VERSION "Version"

NS_ :

BS_:

BU_: Tester CCU ADC CCU_CCURT1 CCU_CCURT2 RLR RRR ZCUF ZCUL ZCUR ZCUT EMS IDM DCDC IPS NIDU NIDUF DCUR OBC OPC LPC CPC EMCM GCU DCUF IPU BMS EOPF EOPR EVCC DCDC2 EDL SRS ECS EPS EPB RBM IBCS ICM IID IDC PHUDD AMP WHUD IMR INU IFC FAPA PAS PCS SCMR SCMRL SCMRR HVSMR SCMRM MFS WSM DRM IDU FCP LBMSAD AVAS ATSS DLPFL FBLCM FLISD FLLCM FRLCM RLLCMA RLLCMB RRLCMA RRLCMB RLISD DLPML DLPMR TRM PSDL PSDR HVSPRL HVSPRR RFR SBM WCM ETC TBOX2 TBOX IDUR CBM PLGM TMC LPC2 SCMT RCP RRISD LBMS RLBMS CCURT1 CCURT2 RT1_C1 RT2_C3 RT1_C0 OTAWL RAS EBB RCICP WCMFR WCMRL SAS CD

BO_ 549 ADC_12: 64 ADC
 SG_ ADC_12_CRC : 7|16@0+ (1,0) [0|65535] ""  CCU,CCURT1,RT1_C0
 SG_ ADC_12_Counter : 23|8@0+ (1,0) [0|255] ""  CCU,CCURT1,RT1_C0
 SG_ ADC_APAst : 31|4@0+ (1,0) [0|15] ""  CCU
 SG_ ADC_AVPst : 27|4@0+ (1,0) [0|15] ""  CCU
 SG_ ADC_PAAFuncSt : 39|4@0+ (1,0) [0|15] ""  CCU,CCURT1,RT1_C0
 SG_ ADC_PAAVoiceReminder : 35|12@0+ (1,0) [0|4095] ""  CCU
 SG_ ADC_PAAVRSwitchFailSt : 55|1@0+ (1,0) [0|1] ""  CCU
 SG_ ADC_APKDisplayReq : 54|1@0+ (1,0) [0|1] ""  CCU
 SG_ ADC_APAActFuncInd : 53|4@0+ (1,0) [0|15] ""  CCU
 SG_ ADC_APABackParkDisplayReq : 49|2@0+ (1,0) [0|3] ""  CCU
 SG_ ADC_VCU_Gearshiftprompt : 56|1@0+ (1,0) [0|1] ""  CCU,CCURT1,RT1_C1
 SG_ ADC_AVPActFuncind : 63|5@0+ (1,0) [0|31] ""  CCU
 SG_ ADC_APAMessagePushSt : 58|2@0+ (1,0) [0|3] ""  CCU
 SG_ ADC_PedWarnToneCtrl : 67|2@0+ (1,0) [0|3] ""  CCU
 SG_ ADC_HPAMessagePushSt : 71|2@0+ (1,0) [0|3] ""  CCU
 SG_ ADC_AVPMessagePushSt : 69|2@0+ (1,0) [0|3] ""  CCU
 SG_ ADC_PAADrvInteraction : 64|9@0+ (1,0) [0|511] ""  CCU
 SG_ ADC_PAAToNDAReq : 89|2@0+ (1,0) [0|3] ""  CCU,ZCUF,ZCUT,IBCS,SBM
 SG_ ADC_PAARemoteParkingMode : 87|2@0+ (1,0) [0|3] ""  CCU
 SG_ ADC_PAARemoteParkingEnable : 85|1@0+ (1,0) [0|1] ""  CCU
 SG_ ADC_LocalToBeDRVReq : 83|1@0+ (1,0) [0|1] ""  CCU,CCURT1,RT1_C0
 SG_ ADC_UsageModeStAscendReq : 82|1@0+ (1,0) [0|1] ""  CCU,CCURT1,RT1_C0
 SG_ ADC_UsageModeStDescendReq : 81|1@0+ (1,0) [0|1] ""  CCU,CCURT1,RT1_C0
 SG_ ADC_PAAIGCInhibitSt : 80|1@0+ (1,0) [0|1] ""  CCU,CCURT1,RT1_C0
 SG_ ADC_UsageModeStHold : 90|1@0+ (1,0) [0|1] ""  CCU,CCURT1,RT1_C0
 SG_ ADC_PAARespondMode : 94|4@0+ (1,0) [0|15] ""  CCU
 SG_ ADC_PAAEDKFunInhibitReq : 95|1@0+ (1,0) [0|1] ""  CCU
 SG_ ADC_RAEBWorkSts : 101|2@0+ (1,0) [0|3] ""  CCU,CCURT1,RT1_C0,RT1_C1
 SG_ ADC_DriverPresentSt : 103|2@0+ (1,0) [0|3] ""  CCU,ZCUF,ZCUR,ZCUT,IBCS
 SG_ ADC_UsageModeStHoldVD : 99|1@0+ (1,0) [0|1] ""  CCU,CCURT1,RT1_C0
 SG_ ADC_RAEBEmgyBrkReq : 111|1@0+ (1,0) [0|1] ""  CCU
 SG_ ADC_RAEBTarAccel : 110|7@0+ (0.1,-10) [-10|0] "m/s"  CCU
 SG_ ADC_PAADrvReq : 119|8@0+ (1,0) [0|255] ""  CCU,ZCUR,IDC,SBM
 SG_ ADC_PAAQuitInd : 127|8@0+ (1,0) [0|255] ""  CCU,ZCUR,IDC,SBM
 SG_ ADC_PAARecInd : 135|6@0+ (1,0) [0|63] ""  CCU,ZCUR,IDC,SBM
 SG_ ADC_RA_RemainDist : 139|12@0+ (1,0) [0|4000] "m"  CCU
 SG_ ADC_RAButtonPress : 156|1@0+ (1,0) [0|1] ""  CCU
 SG_ ADC_Rast : 159|3@0+ (1,0) [0|7] ""  CCU
 SG_ ADC_SBMAuthst : 163|2@0+ (1,0) [0|3] ""  CCU
 SG_ ADC_AuthPassSt : 165|2@0+ (1,0) [0|3] ""  CCU
 SG_ ADC_RPADirectionSel : 155|4@0+ (1,0) [0|15] ""  CCU
 SG_ ADC_VehPoscoord : 167|1@0+ (1,0) [0|1] ""  CCU
 SG_ ADC_VehDynamicPosX : 161|13@0+ (1,-4000) [-4000|4000] "cm"  CCU
 SG_ ADC_VehDynamicPosY : 180|13@0+ (1,-4000) [-4000|4000] "cm"  CCU
 SG_ ADC_VehCurv : 206|10@0+ (1,-500) [-500|500] "m^-1"  CCU
 SG_ ADC_SlotPosX : 212|13@0+ (1,-4000) [-4000|4000] "cm"  CCU
 SG_ ADC_SlotPosY : 231|13@0+ (1,-4000) [-4000|4000] "cm"  CCU
 SG_ ADC_HPAst : 245|4@0+ (1,0) [0|15] ""  CCU,SBM
 SG_ ADC_SlotCurv : 241|10@0+ (1,-500) [-500|500] "m^-1"  CCU
 SG_ ADC_parkInOutDirection : 299|4@0+ (1,0) [0|15] ""  CCU
 SG_ ADC_RPAStMessagePush : 98|3@0+ (1,0) [0|7] ""  CCU
 SG_ ADC_RPAtype : 383|2@0+ (1,0) [0|3] ""  CCU
 SG_ ADC_VehPosYawrate : 343|16@0+ (0.01,-180) [-180|180] "degree"  CCU
 SG_ ADC_SlotAngle : 359|16@0+ (0.01,-180) [-180|180] "degree"  CCU
 SG_ ADC_DskScreenOperationReq : 368|1@0+ (1,0) [0|1] ""  CCU
 SG_ ADC_SenslesEtyParkingSt : 369|1@0+ (1,0) [0|1] ""  CCU
 SG_ ADC_PAALimitToast : 372|3@0+ (1,0) [0|7] ""  CCU
 SG_ ADC_PAALimitReminder : 375|3@0+ (1,0) [0|7] ""  CCU
 SG_ ADC_ParkOutMode : 381|3@0+ (1,0) [0|7] ""  CCU,SBM
 SG_ ADAS_ParkStats : 391|8@0+ (1,0) [0|255] ""  CCU,SBM
 SG_ ADC_ParkinDir : 393|2@0+ (1,0) [0|3] ""  CCU,SBM
 SG_ ADC_FrontEndParkInRes : 409|2@0+ (1,0) [0|3] ""  CCU,SBM
 SG_ ADC_ParkSlotType : 407|3@0+ (1,0) [0|7] ""  CCU,SBM
 SG_ ADC_BleRPAPageSt : 404|5@0+ (1,0) [0|31] ""  CCU,SBM
 SG_ ADC_RPAPreferRes : 415|3@0+ (1,0) [0|7] ""  CCU,SBM
 SG_ ADC_RPAPrkSlotoffset : 423|3@0+ (1,0) [0|7] ""  CCU,SBM
 SG_ ADC_RPAPreferavl : 412|3@0+ (1,0) [0|7] ""  CCU,SBM
 SG_ ADC_RPABlechnReq : 399|1@0+ (1,0) [0|1] ""  CCU,SBM
 SG_ ADC_RPABlePushSt : 398|5@0+ (1,0) [0|31] ""  CCU,SBM

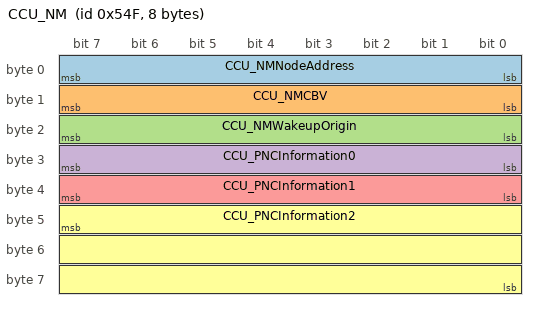
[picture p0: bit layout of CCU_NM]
BO_ 1359 CCU_NM: 8 CCU
 SG_ CCU_NMNodeAddress : 7|8@0+ (1,0) [0|255] ""  CCURT1,TMC,ZCUF,ZCUL,ZCUR,ZCUT,EMS,IPS,NIDU,NIDUF,BMS,EVCC,ECS,CBM,EPB,RBM,IBCS,ICM,IID,IDC,PHUDD,AMP,ADC,FAPA,SCMR,SCMRL,SCMRR,SCMRM,SCMT,IDU,LBMSAD,PLGM,TRM,PSDL,PSDR,LBMS,RLBMS,TBOX
 SG_ CCU_NMCBV : 15|8@0+ (1,0) [0|0] ""  CCURT1,TMC,ZCUF,ZCUL,ZCUR,ZCUT,EMS,IPS,NIDU,NIDUF,BMS,EVCC,ECS,CBM,EPB,RBM,IBCS,ICM,IID,IDC,PHUDD,AMP,ADC,FAPA,SCMR,SCMRL,SCMRR,SCMRM,SCMT,IDU,LBMSAD,PLGM,TRM,PSDL,PSDR,LBMS,RLBMS,TBOX
 SG_ CCU_NMWakeupOrigin : 23|8@0+ (1,0) [0|255] ""  CCURT1,TMC,ZCUF,ZCUL,ZCUR,ZCUT,EMS,IPS,NIDU,NIDUF,BMS,EVCC,ECS,CBM,RBM,IBCS,ICM,IID,IDC,PHUDD,AMP,ADC,FAPA,SCMR,SCMRL,SCMRR,SCMRM,SCMT,IDU,LBMSAD,PLGM,TRM,PSDL,PSDR,LBMS,RLBMS,TBOX
 SG_ CCU_PNCInformation0 : 31|8@0+ (1,0) [0|255] ""  CCURT1,TMC,ZCUF,ZCUL,ZCUR,ZCUT,EMS,IPS,NIDU,NIDUF,BMS,EVCC,ECS,CBM,EPB,RBM,IBCS,ICM,IID,IDC,PHUDD,AMP,ADC,FAPA,SCMR,SCMRL,SCMRR,SCMRM,SCMT,IDU,LBMSAD,PLGM,TRM,PSDL,PSDR,LBMS,RLBMS,TBOX
 SG_ CCU_PNCInformation1 : 39|8@0+ (1,0) [0|255] ""  CCURT1,TMC,ZCUF,ZCUL,ZCUR,ZCUT,EMS,IPS,NIDU,NIDUF,BMS,EVCC,ECS,CBM,EPB,RBM,IBCS,ICM,IID,IDC,PHUDD,AMP,ADC,FAPA,SCMR,SCMRL,SCMRR,SCMRM,SCMT,IDU,LBMSAD,PLGM,TRM,PSDL,PSDR,LBMS,RLBMS,TBOX
 SG_ CCU_PNCInformation2 : 47|24@0+ (1,0) [0|0] ""  CCURT1,TMC,ZCUF,ZCUL,ZCUR,ZCUT,EMS,IPS,NIDU,NIDUF,BMS,EVCC,ECS,CBM,EPB,RBM,IBCS,ICM,IID,IDC,PHUDD,AMP,ADC,FAPA,SCMR,SCMRL,SCMRR,SCMRM,SCMT,IDU,LBMSAD,PLGM,TRM,PSDL,PSDR,LBMS,RLBMS,TBOX

BO_ 905 CCU_IDC_ICM_1: 64 CCU
 SG_ ICM_SetIACCSt : 27|1@0+ (1,0) [0|1] ""  ADC,IFC,FAPA
 SG_ ICM_TotalOdometer : 35|20@0+ (1,0) [0|999999] "km"  ZCUF,ZCUL,ZCUR,ZCUT,EMS,NIDU,NIDUF,DCUR,IDUR,GCU,DCUF,IPU,ECS,EPS,EPB,IBCS,ADC,IFC,FAPA,RRR,RLR,PCS
 SG_ ICM_VehInsSpd : 103|8@0+ (1,0) [0|254] "km/h"  ADC,IFC,FAPA,RRR,RLR
 SG_ ICM_VehInsSpd_accurate : 272|11@0+ (0.1,0) [0|204.6] "km/h"  ECS,WHUD,ADC,IFC,FAPA,RRR,RLR
 SG_ ICM_FuelAvaibleDriveDistance : 311|11@0+ (1,0) [0|2046] "km"  ADC,FAPA
 SG_ ICM_TotalAvaibleDriveDistance : 316|11@0+ (1,0) [0|2046] "km"  ADC,FAPA

BO_ 516 CCU_VCU_9: 64 CCU_CCURT1
 SG_ VCU_9_CRC : 7|16@0+ (1,0) [0|65535] ""  CCURT2,RT2_C3,ZCUF,ZCUL,ZCUR,ZCUT,EMS,NIDU,DCUR,IDUR,EDL,ECS,EPB,IBCS,ICM,IDC,INU,ADC,IFC,FAPA,RRR,RLR,PAS
 SG_ VCU_9_Counter : 23|8@0+ (1,0) [0|255] ""  CCURT2,RT2_C3,ZCUF,ZCUL,ZCUR,ZCUT,EMS,NIDU,DCUR,IDUR,EDL,ECS,EPB,IBCS,ICM,IDC,INU,ADC,IFC,FAPA,RRR,RLR,PAS
 SG_ VCU_MaxDriveTorqVD : 25|1@0+ (1,0) [0|1] ""  ADC,IFC,FAPA
 SG_ VCU_RecpTorqVD : 74|1@0+ (1,0) [0|1] ""  IBCS,ADC,IFC,FAPA
 SG_ VCU_MaxRecpTorqVD : 72|1@0+ (1,0) [0|1] ""  IBCS,ADC,IFC,FAPA
 SG_ VCU_CrntGearLvl : 92|3@0+ (1,0) [0|7] ""  CCURT2,RT2_C3,OTAWL,ZCUF,ZCUL,ZCUR,ZCUT,NIDU,NIDUF,DCUR,IDUR,DCUF,IPU,SRS,ECS,RAS,EPS,EPB,IBCS,IDC,AMP,INU,ADC,IFC,FAPA,RRR,RLR,PAS,WSM,DLPML,DLPMR,TBOX
 SG_ VCU_CrntGearLvlVD : 88|1@0+ (1,0) [0|1] ""  ZCUF,ZCUL,ZCUR,ZCUT,SRS,ECS,EPS,EPB,IBCS,AMP,INU,ADC,IFC,FAPA,RRR,RLR,PAS
 SG_ VCU_BrkPedPstVD : 89|1@0+ (1,0) [0|1] ""  CCURT2,RT2_C3,NIDU,DCUR,IDUR,SRS,ECS,IBCS,IDC,ADC,IFC,FAPA,TBOX
 SG_ VCU_BrkPedPst : 103|8@0+ (0.392,0) [0|99.96] "%"  CCURT2,RT2_C3,NIDU,DCUR,IDUR,SRS,ECS,IBCS,IDC,ADC,IFC,FAPA,TBOX
 SG_ VCU_GearIntervern : 137|1@0+ (1,0) [0|1] ""  IBCS,ADC,IFC,FAPA
 SG_ VCU_AccPedalVirtPstVD : 136|1@0+ (1,0) [0|1] ""  CCURT2,RT2_C3,EMS,NIDU,DCUR,IDUR,SRS,ECS,IBCS,IDC,AMP,ADC,IFC,FAPA,TBOX
 SG_ VCU_ActVehWheelTorq : 378|15@0+ (1,-16000) [-16000|16000] "Nm"  ECS,IBCS,AMP,ADC
 SG_ VCU_MaxRecpTorq : 135|14@0+ (1,0) [0|16000] "Nm"  IBCS,ADC,IFC,FAPA
 SG_ VCU_AccPedalVirtPst : 146|9@0+ (0.2,0) [0|100] "%"  CCURT2,RT2_C3,EMS,NIDU,DCUR,IDUR,SRS,ECS,IBCS,IDC,AMP,ADC,IFC,FAPA,RRR,RLR,TBOX
 SG_ VCU_BrkPedalSt : 189|1@0+ (1,0) [0|1] ""  CCURT2,RT2_C3,EMS,SRS,ECS,IDC,ADC,IFC,FAPA,RRR,RLR,TBOX
 SG_ VCU_BrkPedalStVD : 188|1@0+ (1,0) [0|1] ""  CCURT2,RT2_C3,EMS,SRS,ECS,IDC,ADC,IFC,FAPA,TBOX
 SG_ VCU_ACCLimitOperatingSt : 186|1@0+ (1,0) [0|1] ""  ADC,IFC,FAPA
 SG_ VCU_AccButtInfo : 199|8@0+ (1,0) [0|255] ""  IDC,ADC,IFC,FAPA
 SG_ VCU_ACCmaxSpdLimit : 215|4@0+ (1,0) [0|15] ""  ADC,IFC,FAPA
 SG_ VCU_RecpTorqFAVD : 208|1@0+ (1,0) [0|1] ""  IBCS,ADC,IFC,FAPA
 SG_ VCU_RecpTorqRAVD : 209|1@0+ (1,0) [0|1] ""  IBCS,ADC,IFC,FAPA
 SG_ VCU_MaxRecpTorqFAVD : 152|1@0+ (1,0) [0|1] ""  IBCS,ADC,IFC,FAPA
 SG_ VCU_MaxRecpTorqRAVD : 153|1@0+ (1,0) [0|1] ""  IBCS,ADC,IFC,FAPA
 SG_ VCU_RecpTorq : 359|14@0+ (1,0) [0|16000] "Nm"  IBCS,ADC,IFC,FAPA
 SG_ VCU_MaxDriveTorq : 167|14@0+ (1,0) [0|16000] "Nm"  ECS,IBCS,ADC,IFC,FAPA
 SG_ VCU_RecpTorqFA : 231|14@0+ (1,0) [0|16000] "Nm"  IBCS,ADC,IFC,FAPA
 SG_ VCU_RecpTorqRA : 233|14@0+ (1,0) [0|16000] "Nm"  IBCS,ADC,IFC,FAPA
 SG_ VCU_MaxRecpTorqFA : 251|14@0+ (1,0) [0|16000] "Nm"  IBCS,ADC,IFC,FAPA
 SG_ VCU_MaxRecpTorqRA : 269|14@0+ (1,0) [0|16000] "Nm"  IBCS,ADC,IFC,FAPA
 SG_ VCU_BcsDecelEnable : 305|1@0+ (1,0) [0|1] ""  IBCS,IDC,ADC,IFC,FAPA
 SG_ VCU_CrntGearNoTrans : 317|3@0+ (1,0) [0|7] ""  ADC,IFC,FAPA
 SG_ VCU_EzTSt : 314|2@0+ (1,0) [0|3] ""  IBCS,IDC,ADC,FAPA
 SG_ VCU_ITASSt : 444|3@0+ (1,0) [0|7] ""  IBCS,IDC,ADC,FAPA

BO_ 909 CCU_ZCU_1: 64 CCU_CCURT2
 SG_ LCK_HoodAjarSt : 37|1@0+ (1,0) [0|1] ""  OTAWL,ZCUR,EMS,ECS,ICM,IID,IDC,PHUDD,AMP,ADC,IFC,FAPA,RRR,RLR,PCS
 SG_ LCK_FrontLeftDoorAjarSt : 36|1@0+ (1,0) [0|1] ""  OTAWL,ZCUF,ZCUR,ZCUT,EPB,IBCS,ICM,IID,IDC,PHUDD,AMP,IMR,ADC,IFC,FAPA,RRR,RLR,WSM,DLPML,DLPMR,PLGM
 SG_ LCK_FrontRightDoorAjarSt : 35|1@0+ (1,0) [0|1] ""  ZCUT,IBCS,ICM,IID,IDC,PHUDD,AMP,IMR,ADC,IFC,FAPA,RRR,RLR,WSM,DLPML,DLPMR,PLGM
 SG_ LCK_RearLeftDoorAjarSt : 34|1@0+ (1,0) [0|1] ""  OTAWL,ZCUL,ZCUR,ECS,IBCS,ICM,IID,IDC,PHUDD,AMP,IMR,ADC,IFC,FAPA,RRR,RLR,PCS,SCMR,SCMRL,SCMRR,SCMRM,DLPML,DLPMR,PLGM
 SG_ LCK_RearRightDoorAjarSt : 33|1@0+ (1,0) [0|1] ""  OTAWL,ZCUL,ZCUR,ECS,IBCS,ICM,IID,IDC,PHUDD,AMP,IMR,ADC,IFC,FAPA,RRR,RLR,PCS,SCMR,SCMRL,SCMRR,SCMRM,DLPML,DLPMR,PLGM
 SG_ LCK_TrunkAjarSt : 32|1@0+ (1,0) [0|1] ""  OTAWL,ZCUF,ZCUL,ZCUR,ECS,ICM,IID,IDC,PHUDD,AMP,IMR,ADC,IFC,FAPA,RRR,RLR,PCS
 SG_ LCK_FrontLeftDoorLockSt : 47|1@0+ (1,0) [0|1] ""  OTAWL,ZCUR,CBM,ICM,IDC,ADC,IFC,FAPA,RRR,RLR
 SG_ LCK_FrontRightDoorLockSt : 46|1@0+ (1,0) [0|1] ""  CBM,ICM,IDC,ADC,IFC,FAPA,RRR,RLR
 SG_ LCK_RearLeftDoorLockSt : 45|1@0+ (1,0) [0|1] ""  OTAWL,ZCUL,ZCUR,ECS,CBM,ICM,IDC,ADC,IFC,FAPA,RRR,RLR
 SG_ LCK_RearRightDoorLockSt : 44|1@0+ (1,0) [0|1] ""  OTAWL,ZCUL,ZCUR,ECS,CBM,ICM,IDC,ADC,IFC,FAPA,RRR,RLR
 SG_ LCK_RearLeftChildSaftyLockSt : 43|1@0+ (1,0) [0|1] ""  ZCUL,ZCUR,CBM,ICM,IDC,ADC,IFC,FAPA,RRR,RLR
 SG_ LCK_RearRightChildSaftyLockSt : 42|1@0+ (1,0) [0|1] ""  OTAWL,ZCUL,ZCUR,CBM,ICM,IDC,ADC,IFC,FAPA,RRR,RLR
 SG_ EMS_EngStForPHEV : 79|3@0+ (1,0) [0|7] ""  NIDU,BMS,IDC,ADC,FAPA
 SG_ WCM_Reminder : 103|1@0+ (1,0) [0|1] ""  ADC,FAPA
 SG_ WCM_ChargingSt : 89|2@0+ (1,0) [0|3] ""  ADC,FAPA
 SG_ LCK_FrontLeftDoorHandlePosition : 135|8@0+ (1,0) [0|255] ""  CBM,ICM,IDC,ADC,FAPA
 SG_ LCK_FrontRightDoorHandlePosition : 143|8@0+ (1,0) [0|255] ""  CBM,ICM,IDC,ADC,FAPA
 SG_ LCK_RearLeftDoorHandlePosition : 151|8@0+ (1,0) [0|255] ""  ZCUL,ZCUR,CBM,ICM,IDC,ADC,FAPA
 SG_ LCK_RearRightDoorHandlePosition : 159|8@0+ (1,0) [0|255] ""  ZCUL,ZCUR,CBM,ICM,IDC,ADC,FAPA
 SG_ WW_RWPMotorSt : 226|3@0+ (1,0) [0|7] ""  ADC,IFC,FAPA
 SG_ LCK_FillerCapASt : 239|1@0+ (1,0) [0|1] ""  ZCUL,ZCUR,EMS,ICM,IDC,ADC,FAPA
 SG_ LCK_FillerCapBSt : 238|1@0+ (1,0) [0|1] ""  ZCUL,ZCUR,EMS,ICM,IDC,ADC,FAPA
 SG_ MR_LeftMirrorFoldUnfoldSt : 233|2@0+ (1,0) [0|3] ""  ADC,IFC,FAPA,RRR,RLR,PCS,WSM,DLPML,DLPMR
 SG_ SBM_SwapHvBattModeSt : 247|4@0+ (1,0) [0|15] ""  ADC,FAPA
 SG_ SBM_SwapStaDiagCode : 243|4@0+ (1,0) [0|15] ""  ADC,FAPA
 SG_ SBM_SwapVehDiagCode : 255|4@0+ (1,0) [0|15] ""  ADC,FAPA
 SG_ SBM_SwapHvBattModeFaultSt : 251|3@0+ (1,0) [0|7] ""  ADC,FAPA
 SG_ IPDS_HDMapPowerSt : 271|1@0+ (1,0) [0|1] ""  ADC,IFC,FAPA
 SG_ IPDS_KL15L1PowerSt : 270|1@0+ (1,0) [0|1] ""  EBB,IBCS,ADC,IFC,FAPA,RRR,RLR
 SG_ IPDS_SRSECUPowerSt : 269|1@0+ (1,0) [0|1] ""  EPS,IBCS,ADC,IFC,FAPA
 SG_ IPDS_HODPowerSt : 268|1@0+ (1,0) [0|1] ""  ADC,IFC,FAPA
 SG_ KAE_BLEOption : 265|1@0+ (1,0) [0|1] ""  ADC,FAPA
 SG_ KAE_UWBOption : 264|1@0+ (1,0) [0|1] ""  ADC,FAPA
 SG_ PWL_WinCurrentPos_FLWinPst : 470|8@0+ (0.5,0) [0|100] "%"  ZCUT,ADC,FAPA,PLGM
 SG_ UINM_FrontLeftPowerReleaseReq : 456|1@0+ (1,0) [0|1] ""  ADC,FAPA
 SG_ UINM_FrontLeftPowerReleaseFaultSt : 457|1@0+ (1,0) [0|1] ""  ADC,FAPA
 SG_ UINM_FrontRightPowerReleaseReq : 458|1@0+ (1,0) [0|1] ""  ADC,FAPA
 SG_ UINM_FrontRightPowerReleaseFaultSt : 459|1@0+ (1,0) [0|1] ""  ADC,FAPA
 SG_ UINM_RearLeftPowerReleaseFaultSt : 460|1@0+ (1,0) [0|1] ""  ADC,FAPA
 SG_ UINM_RearLeftPowerReleaseReq : 461|1@0+ (1,0) [0|1] ""  ADC,FAPA
 SG_ UINM_RearRightPowerReleaseFaultSt : 462|1@0+ (1,0) [0|1] ""  ADC,FAPA
 SG_ UINM_RearRightPowerReleaseReq : 471|1@0+ (1,0) [0|1] ""  ADC,FAPA
 SG_ BMS_BattSOCAccurate : 478|14@0+ (0.01,0) [0|100] "%"  ADC,FAPA
 SG_ PWL_WinCurrentPos_RRWinPst : 503|8@0+ (0.5,0) [0|100] "％"  IDC,RCICP,AMP,IMR,ADC,FAPA,PLGM,HVSPRL,HVSPRR
 SG_ PWL_WinCurrentPos_RLWinPst : 511|8@0+ (0.5,0) [0|100] "％"  ZCUR,IDC,RCICP,AMP,IMR,ADC,FAPA,PLGM,HVSPRL,HVSPRR
 SG_ ACEleclocksSt : 282|3@0+ (1,0) [0|7] ""  ADC,FAPA
 SG_ DSASBM_MotResp : 375|4@0+ (1,0) [0|15] ""  ADC,FAPA

BO_ 792 CCU_ZCU_4: 64 CCU_CCURT2
 SG_ UMM_SecondRHSeatSt : 37|2@0+ (1,0) [0|3] ""  ICM,IDC,ADC,IFC
 SG_ UMM_SecondLHSeatSt : 39|2@0+ (1,0) [0|3] ""  ICM,IDC,ADC,IFC
 SG_ LCK_PowerFillerCapAngle : 103|8@0+ (1,0) [0|255] "deg"  ICM,IDC,ADC,FAPA
 SG_ EL_ReverseLightSt : 111|1@0+ (1,0) [0|1] ""  IDC,ADC,IFC,FAPA,PCS
 SG_ EL_ReverseLightFaultSt : 110|1@0+ (1,0) [0|1] ""  ICM,IDC,ADC,IFC,FAPA
 SG_ EL_RLPositionLightSt : 105|1@0+ (1,0) [0|1] ""  ICM,IDC,ADC,IFC,FAPA
 SG_ EL_RLPositionLightFaultSt : 104|1@0+ (1,0) [0|1] ""  ICM,IDC,ADC,IFC,FAPA
 SG_ EL_RRPositionLightSt : 119|1@0+ (1,0) [0|1] ""  ICM,IDC,ADC,IFC,FAPA
 SG_ EL_RRPositionLightFaultSt : 118|1@0+ (1,0) [0|1] ""  ICM,IDC,ADC,IFC,FAPA
 SG_ EL_RearFogLightSt : 117|1@0+ (1,0) [0|1] ""  ICM,IDC,ADC,IFC,FAPA
 SG_ EL_RearFogLightFaultSt : 116|1@0+ (1,0) [0|1] ""  ICM,IDC,ADC,IFC,FAPA

BO_ 860 CCU_VCU_7: 64 CCU_CCURT1
 SG_ VCU_7_CRC : 7|16@0+ (1,0) [0|65535] ""  CCURT2,RT2_C3,ZCUF,ZCUL,ZCUR,ZCUT,EPB,IDC,ADC,IFC,FAPA,RRR,RLR,DRM
 SG_ VCU_7_Counter : 23|8@0+ (1,0) [0|255] ""  CCURT2,RT2_C3,ZCUF,ZCUL,ZCUR,ZCUT,EPB,IDC,ADC,IFC,FAPA,RRR,RLR,DRM
 SG_ VCU_RoadMod : 27|3@0+ (1,0) [0|7] ""  ECS,IBCS,IDC,ADC,FAPA
 SG_ VCU_GearLvl : 31|4@0+ (1,0) [0|15] ""  CCURT2,RT2_C3,ZCUF,ZCUL,ZCUR,ZCUT,EMS,EPB,IBCS,ADC,IFC,FAPA,RRR,RLR,DRM
 SG_ VCU_VehDrvMod : 38|3@0+ (1,0) [0|7] ""  ZCUL,ZCUR,EMS,ECS,IBCS,ICM,IDC,AMP,ADC,IFC,FAPA,ATSS,WCM,WCMFR,WCMRL
 SG_ VCU_VehRdySt : 39|1@0+ (1,0) [0|1] ""  CCURT2,RT2_C3,OTAWL,ZCUF,ZCUL,ZCUR,ZCUT,EMS,IDM,IPS,NIDU,NIDUF,DCUR,IDUR,OBC,GCU,DCUF,IPU,BMS,ECS,EPB,IBCS,ICM,IID,IDC,PHUDD,ADC,IFC,FAPA,RRR,RLR,TBOX
 SG_ VCU_PlgConnSt : 91|1@0+ (1,0) [0|1] ""  CCURT2,RT2_C3,ZCUR,ZCUT,NIDU,NIDUF,DCUR,IDUR,GCU,DCUF,IPU,ECS,ICM,IID,IDC,PHUDD,ADC,IFC,FAPA
 SG_ VCU_GearLvlDisp : 155|4@0+ (1,0) [0|15] ""  ICM,IID,IDC,PHUDD,WHUD,IMR,ADC,IFC,FAPA,PCS
 SG_ VCU_SuspModeReq : 257|2@0+ (1,0) [0|3] ""  ECS,ADC,IFC,FAPA
 SG_ VCU_SuspModeReqEnable : 316|1@0+ (1,0) [0|1] ""  ECS,ADC,IFC,FAPA
 SG_ VCU_GearPosition : 315|3@0+ (1,0) [0|7] ""  CCURT2,RT2_C3,BMS,ADC,IFC,FAPA
 SG_ VCU_EcoPlusMod : 341|2@0+ (1,0) [0|3] ""  CCURT2,RT2_C3,IDC,WHUD,ADC
 SG_ ICC_RoadMod : 339|4@0+ (1,0) [0|8] ""  CCURT2,RT2_C3,NIDU,BMS,ECS,IBCS,IDC,AMP,ADC,WSM,ATSS
 SG_ VCU_TrailerModeSt : 396|3@0+ (1,0) [0|7] ""  ECS,IBCS,IDC,ADC
 SG_ VCU_BMS_BattSocDisp : 405|14@0+ (0.01,0) [0|100] "%"  CCURT2,RT2_C3,ZCUL,ZCUR,EMS,BMS,ICM,IID,IDC,PHUDD,ADC
 SG_ VCU_VehElcConspAccumAvg : 429|10@0+ (0.1,-51) [-51|51.2] "kWh/100km"  CCURT2,RT2_C3,BMS,IDC,ADC
 SG_ ICC_360Switch : 435|2@0+ (1,0) [0|3] ""  IDC,ADC

CM_ SG_ 549 ADC_12_CRC "E2E Profile 5 CRC";
CM_ SG_ 549 ADC_12_Counter "E2E Profile 5 Counter";
CM_ SG_ 549 ADC_APAst "APA and FAPA status";
CM_ SG_ 549 ADC_AVPst "HPA and AVP status";
CM_ SG_ 549 ADC_PAAFuncSt "PAA working functions inaication signal";
CM_ SG_ 549 ADC_PAAVoiceReminder "PAA Voice Reminder";
CM_ SG_ 549 ADC_PAAVRSwitchFailSt "PAA VR Switch Fail State";
CM_ SG_ 549 ADC_APKDisplayReq "APK display request";
CM_ SG_ 549 ADC_APAActFuncInd "Auto_parking Active Function Indication";
CM_ SG_ 549 ADC_APABackParkDisplayReq "APA Background Parking For AVNT Display";
CM_ SG_ 549 ADC_VCU_Gearshiftprompt "The signal prohibiting gear shifting prompt sent from the ADC to the VCU";
CM_ SG_ 549 ADC_AVPActFuncind "AVP Active Function Indication";
CM_ SG_ 549 ADC_APAMessagePushSt "APA Message Push Staus";
CM_ SG_ 549 ADC_PedWarnToneCtrl "Parking cost pedestrian warning sound";
CM_ SG_ 549 ADC_HPAMessagePushSt "HPA Message  Push Staus";
CM_ SG_ 549 ADC_AVPMessagePushSt "AVP Message  Push Staus";
CM_ SG_ 549 ADC_PAADrvInteraction "PAA Driver Interaction signal";
CM_ SG_ 549 ADC_PAAToNDAReq "PAA  to NDA status requested, or NDA to PAA  status requested";
CM_ SG_ 549 ADC_PAARemoteParkingMode "PAA Remote parking Mode";
CM_ SG_ 549 ADC_PAARemoteParkingEnable "PAA Remote Parking Enable";
CM_ SG_ 549 ADC_LocalToBeDRVReq "Request IPDS  PW KL15";
CM_ SG_ 549 ADC_UsageModeStAscendReq "Request UMM to Comfort";
CM_ SG_ 549 ADC_UsageModeStDescendReq "Request UMM to Standby";
CM_ SG_ 549 ADC_PAAIGCInhibitSt "The inhibit state of IGC function";
CM_ SG_ 549 ADC_UsageModeStHold "ADC UsageMode State Hold";
CM_ SG_ 549 ADC_PAARespondMode "PAA? Respond Mode";
CM_ SG_ 549 ADC_PAAEDKFunInhibitReq "PAA send key function inhibit request to EDK";
CM_ SG_ 549 ADC_RAEBWorkSts "RAEB Work status ";
CM_ SG_ 549 ADC_DriverPresentSt "The Status of Driver on/off the Front Left seat.";
CM_ SG_ 549 ADC_UsageModeStHoldVD "ADC UsageMode State Hold Valid";
CM_ SG_ 549 ADC_RAEBEmgyBrkReq "RAEB Emergency brake requested";
CM_ SG_ 549 ADC_RAEBTarAccel "RAEB target acceleration";
CM_ SG_ 549 ADC_PAADrvReq "Parking Driver Request";
CM_ SG_ 549 ADC_PAAQuitInd "Parking Quit indication";
CM_ SG_ 549 ADC_PAARecInd "Parking Recover indication";
CM_ SG_ 549 ADC_RA_RemainDist "RA the remainin distance";
CM_ SG_ 549 ADC_RAButtonPress "PCS RA button press status";
CM_ SG_ 549 ADC_Rast "RA state";
CM_ SG_ 549 ADC_SBMAuthst "PAA Authst with SBM";
CM_ SG_ 549 ADC_AuthPassSt "PAA Authst Pass Status";
CM_ SG_ 549 ADC_RPADirectionSel "ADC select park out direction for RPA";
CM_ SG_ 549 ADC_VehPoscoord "Vehicle coordinate system type";
CM_ SG_ 549 ADC_VehDynamicPosX "Vehicle dynamic postion in X axis";
CM_ SG_ 549 ADC_VehDynamicPosY "Vehicle dynamic postion in Y axis";
CM_ SG_ 549 ADC_VehCurv "Vehicle dynamic curve";
CM_ SG_ 549 ADC_SlotPosX "Current choosed slot postion in X axis";
CM_ SG_ 549 ADC_SlotPosY "Current choosed slot postion in Y axis";
CM_ SG_ 549 ADC_HPAst "HPA status";
CM_ SG_ 549 ADC_SlotCurv "Current choosed slot curve";
CM_ SG_ 549 ADC_parkInOutDirection "ADC Park in/out Direction";
CM_ SG_ 549 ADC_RPAStMessagePush "indicate the LRPA push message to APP";
CM_ SG_ 549 ADC_RPAtype "Indicate the RPA type";
CM_ SG_ 549 ADC_VehPosYawrate "Vehicle dynamic postion yawrate";
CM_ SG_ 549 ADC_SlotAngle "Current choosed slot angle";
CM_ SG_ 549 ADC_DskScreenOperationReq "Desktop Screen Operation State Request";
CM_ SG_ 549 ADC_SenslesEtyParkingSt "Senseless entry parking switch state";
CM_ SG_ 549 ADC_PAALimitToast "PAA not available toast";
CM_ SG_ 549 ADC_PAALimitReminder "PAA not available voice reminder";
CM_ SG_ 549 ADC_ParkOutMode "ADC Park out Mode";
CM_ SG_ 549 ADAS_ParkStats "HW ADS Parking status signal";
CM_ SG_ 549 ADC_ParkinDir "ADC  Parkin Direction";
CM_ SG_ 549 ADC_FrontEndParkInRes "ADC FrontEnd Park ";
CM_ SG_ 549 ADC_ParkSlotType "ADC ParkSlot Type";
CM_ SG_ 549 ADC_BleRPAPageSt "ADC RPA Page State";
CM_ SG_ 549 ADC_RPAPreferRes "ADC_RPAPreferRes";
CM_ SG_ 549 ADC_RPAPrkSlotoffset "ADC_RPAPrkSlotoffset";
CM_ SG_ 549 ADC_RPAPreferavl "ADC-RPAPreferavl";
CM_ SG_ 549 ADC_RPABlechnReq "RPA Ble channel Request";
CM_ SG_ 549 ADC_RPABlePushSt "RPA push state";
CM_ SG_ 1359 CCU_NMNodeAddress "CCU node address";
CM_ SG_ 1359 CCU_NMCBV "CCU Network management control bit vector";
CM_ SG_ 1359 CCU_NMWakeupOrigin "Origin of the wake up";
CM_ SG_ 1359 CCU_PNCInformation0 "PNC Information";
CM_ SG_ 1359 CCU_PNCInformation1 "PNC Information";
CM_ SG_ 1359 CCU_PNCInformation2 "PNC Information";
CM_ SG_ 905 ICM_SetIACCSt "ICM set IACC status";
CM_ SG_ 905 ICM_TotalOdometer "Total odometer";
CM_ SG_ 905 ICM_VehInsSpd "Vehicle instantaneous speed";
CM_ SG_ 905 ICM_VehInsSpd_accurate "Vehicle instantaneous speed";
CM_ SG_ 905 ICM_FuelAvaibleDriveDistance "The available driving distance according to the fuel";
CM_ SG_ 905 ICM_TotalAvaibleDriveDistance "The available driving distance according to the total";
CM_ SG_ 516 VCU_9_CRC "E2E Profile 5 CRC";
CM_ SG_ 516 VCU_9_Counter "E2E Profile 5 Counter";
CM_ SG_ 516 VCU_MaxDriveTorqVD "Actual effective maximum adjustable torque on wheel level validity";
CM_ SG_ 516 VCU_RecpTorqVD "Status of recuperation torque of generator";
CM_ SG_ 516 VCU_MaxRecpTorqVD "Status of target recuperation torque request by BCS to generator";
CM_ SG_ 516 VCU_CrntGearLvl "VCU current carry out gear level";
CM_ SG_ 516 VCU_CrntGearLvlVD "Valid bit for ActualGearPosition.";
CM_ SG_ 516 VCU_BrkPedPstVD "Current brake pedal position valid data";
CM_ SG_ 516 VCU_BrkPedPst "Current brake pedal position";
CM_ SG_ 516 VCU_GearIntervern "During parking, If there is a request from GSM to change the gearlevel, this signal will be set to 1:with intervention (GSM gearlevel invalid will also be regard as a gearlevel request)";
CM_ SG_ 516 VCU_AccPedalVirtPstVD "Current accelerate pedal actual position validity";
CM_ SG_ 516 VCU_ActVehWheelTorq "Actual effective engine torque on wheel level";
CM_ SG_ 516 VCU_MaxRecpTorq "Current maximum available recuperation torque of generator";
CM_ SG_ 516 VCU_AccPedalVirtPst "Current accelerate pedal actual position";
CM_ SG_ 516 VCU_BrkPedalSt " Brake pedal status";
CM_ SG_ 516 VCU_BrkPedalStVD "VCU_EMS_BrakePedSt valid data";
CM_ SG_ 516 VCU_ACCLimitOperatingSt "Operation status of ACC Limit mode, When VCU Enter the power-saving mode";
CM_ SG_ 516 VCU_AccButtInfo "ACC Button Information";
CM_ SG_ 516 VCU_ACCmaxSpdLimit "When VCU Enter the power-saving mode，the maximum ACC target speed limited by VCU";
CM_ SG_ 516 VCU_RecpTorqFAVD "Status of front axel maximum recuperation torque of generator";
CM_ SG_ 516 VCU_RecpTorqRAVD "Status of rear axel maximum recuperation torque of generator";
CM_ SG_ 516 VCU_MaxRecpTorqFAVD "Status of front axel maximum recuperation torque of generator";
CM_ SG_ 516 VCU_MaxRecpTorqRAVD "Status of front axel maximum recuperation torque of generator";
CM_ SG_ 516 VCU_RecpTorq "Current recuperation torque of generator";
CM_ SG_ 516 VCU_MaxDriveTorq "Actual effective maximum adjustable torque on wheel level";
CM_ SG_ 516 VCU_RecpTorqFA "Current recuperation torque of generator FA";
CM_ SG_ 516 VCU_RecpTorqRA "Current recuperation torque of generator RA";
CM_ SG_ 516 VCU_MaxRecpTorqFA "Current maximum available recuperation torque of generator FA";
CM_ SG_ 516 VCU_MaxRecpTorqRA "Current maximum available recuperation torque of generator RA";
CM_ SG_ 516 VCU_BcsDecelEnable "AVDC deceleration to BCS enable";
CM_ SG_ 516 VCU_CrntGearNoTrans "VCU Gear Lever send to ADS without trans";
CM_ SG_ 516 VCU_EzTSt "This signal indicates VCU-Easy turn state";
CM_ SG_ 516 VCU_ITASSt "This signal indicates VCU state that can enter iTAS or not";
CM_ SG_ 909 LCK_HoodAjarSt "HoodAjarSt";
CM_ SG_ 909 LCK_FrontLeftDoorAjarSt "FrontLeftDoorAjarSt";
CM_ SG_ 909 LCK_FrontRightDoorAjarSt "FrontRightDoorAjarSt";
CM_ SG_ 909 LCK_RearLeftDoorAjarSt "RearLeftDoorAjarSt";
CM_ SG_ 909 LCK_RearRightDoorAjarSt "RearRightDoorAjarSt";
CM_ SG_ 909 LCK_TrunkAjarSt "TrunkAjarSt";
CM_ SG_ 909 LCK_FrontLeftDoorLockSt "FrontLeftDoorLockSt";
CM_ SG_ 909 LCK_FrontRightDoorLockSt "FrontRightDoorLockSt";
CM_ SG_ 909 LCK_RearLeftDoorLockSt "RearLeftDoorLockSt";
CM_ SG_ 909 LCK_RearRightDoorLockSt "RearRightDoorLockSt";
CM_ SG_ 909 LCK_RearLeftChildSaftyLockSt "RearLeftChildSaftyLockSt";
CM_ SG_ 909 LCK_RearRightChildSaftyLockSt "RearRightChildSaftyLockSt";
CM_ SG_ 909 EMS_EngStForPHEV "Engine running status for PHEV";
CM_ SG_ 909 WCM_Reminder "Reminder the Phone lft";
CM_ SG_ 909 WCM_ChargingSt "Changing is ongoing or stopped";
CM_ SG_ 909 LCK_FrontLeftDoorHandlePosition "FrontLeftDoorHandlePosition";
CM_ SG_ 909 LCK_FrontRightDoorHandlePosition "FrontRightDoorHandlePosition";
CM_ SG_ 909 LCK_RearLeftDoorHandlePosition "RearLeftDoorHandlePosition";
CM_ SG_ 909 LCK_RearRightDoorHandlePosition "RearRightDoorHandlePosition";
CM_ SG_ 909 WW_RWPMotorSt "RearWiper Motor status";
CM_ SG_ 909 LCK_FillerCapASt "FillerCapASt";
CM_ SG_ 909 LCK_FillerCapBSt "FillerCapBSt";
CM_ SG_ 909 MR_LeftMirrorFoldUnfoldSt "Left Mirror Fold Unfold Status";
CM_ SG_ 909 SBM_SwapHvBattModeSt "Swap station mode statue";
CM_ SG_ 909 SBM_SwapStaDiagCode "Swap station erroe";
CM_ SG_ 909 SBM_SwapVehDiagCode "vehicl erroe in swap station";
CM_ SG_ 909 SBM_SwapHvBattModeFaultSt "Swap station mode fault statue";
CM_ SG_ 909 IPDS_HDMapPowerSt "HD map power state";
CM_ SG_ 909 IPDS_KL15L1PowerSt "KL15 L1 power state";
CM_ SG_ 909 IPDS_SRSECUPowerSt "SRS ECU power state";
CM_ SG_ 909 IPDS_HODPowerSt "HOD power state";
CM_ SG_ 909 KAE_BLEOption "BLEOption";
CM_ SG_ 909 KAE_UWBOption "UWB Option";
CM_ SG_ 909 PWL_WinCurrentPos_FLWinPst "Window Current Position Front left Window";
CM_ SG_ 909 UINM_FrontLeftPowerReleaseReq "FrontLeftPowerReleaseReq";
CM_ SG_ 909 UINM_FrontLeftPowerReleaseFaultSt "Front Left Power Release Swtich fault state";
CM_ SG_ 909 UINM_FrontRightPowerReleaseReq "FrontRightPowerReleaseReq";
CM_ SG_ 909 UINM_FrontRightPowerReleaseFaultSt "Front Right Power Release Swtich fault state";
CM_ SG_ 909 UINM_RearLeftPowerReleaseFaultSt "RearLeftPowerReleaseReq";
CM_ SG_ 909 UINM_RearLeftPowerReleaseReq "RearLeftPowerReleaseReq";
CM_ SG_ 909 UINM_RearRightPowerReleaseFaultSt "RearRightPowerReleaseReq";
CM_ SG_ 909 UINM_RearRightPowerReleaseReq "RearRightPowerReleaseReq";
CM_ SG_ 909 BMS_BattSOCAccurate "Accurate SOC Value sent to other contoller";
CM_ SG_ 909 PWL_WinCurrentPos_RRWinPst "Rear Right Window Current Position";
CM_ SG_ 909 PWL_WinCurrentPos_RLWinPst "Rear Left Window Current Position";
CM_ SG_ 909 ACEleclocksSt "AC gun electronic lock status feedback";
CM_ SG_ 909 DSASBM_MotResp "Driver Side Active Seat Belt Motor Response";
CM_ SG_ 792 UMM_SecondRHSeatSt "Second Right Seat Sensor Status";
CM_ SG_ 792 UMM_SecondLHSeatSt "Second Left Seat Sensor Status";
CM_ SG_ 792 LCK_PowerFillerCapAngle "PowerFillerCapOpenAngle";
CM_ SG_ 792 EL_ReverseLightSt "Reverse light status";
CM_ SG_ 792 EL_ReverseLightFaultSt "Reverse light fault status";
CM_ SG_ 792 EL_RLPositionLightSt "Rear left position light status";
CM_ SG_ 792 EL_RLPositionLightFaultSt "Rear left position light fault status";
CM_ SG_ 792 EL_RRPositionLightSt "Rear right position light status";
CM_ SG_ 792 EL_RRPositionLightFaultSt "Rear right position light fault status";
CM_ SG_ 792 EL_RearFogLightSt "Rear fog light status";
CM_ SG_ 792 EL_RearFogLightFaultSt "Rear fog light fault status";
CM_ SG_ 860 VCU_7_CRC "E2E Profile 5 CRC";
CM_ SG_ 860 VCU_7_Counter "E2E Profile 5 Counter";
CM_ SG_ 860 VCU_RoadMod "Road mode for display";
CM_ SG_ 860 VCU_GearLvl "Gear lever for PEPS";
CM_ SG_ 860 VCU_VehDrvMod "Drive mode for display";
CM_ SG_ 860 VCU_VehRdySt "HEV system ready status";
CM_ SG_ 860 VCU_PlgConnSt "Charge connector  connected Status";
CM_ SG_ 860 VCU_GearLvlDisp "Gear lever for display";
CM_ SG_ 860 VCU_SuspModeReq "VCU to SDC  AVDC mode request ";
CM_ SG_ 860 VCU_SuspModeReqEnable "VCU to SDC AVDC  mode request enable status ";
CM_ SG_ 860 VCU_GearPosition "Gear lever for PEPS TCC";
CM_ SG_ 860 VCU_EcoPlusMod "EcoPlus mode is activated";
CM_ SG_ 860 ICC_RoadMod "Cross-Country Road Mode for Display";
CM_ SG_ 860 VCU_TrailerModeSt "VCU Trailer Mode Status";
CM_ SG_ 860 VCU_BMS_BattSocDisp "Average SOC of battery pack for display";
CM_ SG_ 860 VCU_VehElcConspAccumAvg "Accumulated average electric consumption to A";
CM_ SG_ 860 ICC_360Switch "Switch of 360 under off-road terrain";

BA_DEF_ BO_  "GenMsgCycleTime" INT 0 0;
BA_DEF_ BO_  "GenMsgCycleTimeFast" INT 0 0;
BA_DEF_ BO_  "GenMsgSendType" ENUM  "Periodic","Event","IfActive","POE","PA","FixedPeriodic","Event","EnabledPeriodic","NotUsed","NotUsed","EventPeriodic","NotUsed","NotUsed","NoMsgSendType";
BA_DEF_ BO_  "VFrameFormat" ENUM  "StandardCAN","ExtendedCAN","reserved","reserved","reserved","reserved","reserved","reserved","reserved","reserved","reserved","reserved","reserved","reserved","StandardCAN_FD","ExtendedCAN_FD";
BA_DEF_ BO_  "CANFD_BRS" ENUM  "0","1";
BA_DEF_ SG_  "EventCommandSignal" ENUM  "No","Yes";
BA_DEF_ SG_  "GatewayedSignals" ENUM  "No","Yes";
BA_DEF_ SG_  "GenSigInactiveValue" HEX 0 0;
BA_DEF_ SG_  "GenSigInvalidValue" HEX 0 0;
BA_DEF_ SG_  "GenSigSendType" ENUM  "Trigger","Passive","Cyclic","OnWrite","OnWriteWithRepetition","OnChange","OnChangeWithRepetition","IfActive","IfActiveWithRepetition","NoSigSendType";
BA_DEF_ SG_  "GenSigStartValue" HEX 0 0;
BA_DEF_ SG_  "GenSigTimeoutValue" HEX 0 0;
BA_DEF_ SG_  "Remark" STRING ;
BA_ "GenMsgCycleTime" BO_ 549 20;
BA_ "GenMsgCycleTimeFast" BO_ 549 0;
BA_ "GenMsgSendType" BO_ 549 0;
BA_ "VFrameFormat" BO_ 549 14;
BA_ "CANFD_BRS" BO_ 549 1;
BA_ "GenMsgCycleTime" BO_ 549 20;
BA_ "GenMsgCycleTimeFast" BO_ 549 0;
BA_ "GenMsgSendType" BO_ 549 0;
BA_ "VFrameFormat" BO_ 549 14;
BA_ "CANFD_BRS" BO_ 549 1;
BA_ "GenMsgCycleTime" BO_ 549 20;
BA_ "GenMsgCycleTimeFast" BO_ 549 0;
BA_ "GenMsgSendType" BO_ 549 0;
BA_ "VFrameFormat" BO_ 549 14;
BA_ "CANFD_BRS" BO_ 549 1;
BA_ "GenMsgCycleTime" BO_ 549 20;
BA_ "GenMsgCycleTimeFast" BO_ 549 0;
BA_ "GenMsgSendType" BO_ 549 0;
BA_ "VFrameFormat" BO_ 549 14;
BA_ "CANFD_BRS" BO_ 549 1;
BA_ "GenMsgCycleTime" BO_ 549 20;
BA_ "GenMsgCycleTimeFast" BO_ 549 0;
BA_ "GenMsgSendType" BO_ 549 0;
BA_ "VFrameFormat" BO_ 549 14;
BA_ "CANFD_BRS" BO_ 549 1;
BA_ "GenMsgCycleTime" BO_ 549 20;
BA_ "GenMsgCycleTimeFast" BO_ 549 0;
BA_ "GenMsgSendType" BO_ 549 0;
BA_ "VFrameFormat" BO_ 549 14;
BA_ "CANFD_BRS" BO_ 549 1;
BA_ "GenMsgCycleTime" BO_ 549 20;
BA_ "GenMsgCycleTimeFast" BO_ 549 0;
BA_ "GenMsgSendType" BO_ 549 0;
BA_ "VFrameFormat" BO_ 549 14;
BA_ "CANFD_BRS" BO_ 549 1;
BA_ "GenMsgCycleTime" BO_ 549 20;
BA_ "GenMsgCycleTimeFast" BO_ 549 0;
BA_ "GenMsgSendType" BO_ 549 0;
BA_ "VFrameFormat" BO_ 549 14;
BA_ "CANFD_BRS" BO_ 549 1;
BA_ "GenMsgCycleTime" BO_ 549 20;
BA_ "GenMsgCycleTimeFast" BO_ 549 0;
BA_ "GenMsgSendType" BO_ 549 0;
BA_ "VFrameFormat" BO_ 549 14;
BA_ "CANFD_BRS" BO_ 549 1;
BA_ "GenMsgCycleTime" BO_ 549 20;
BA_ "GenMsgCycleTimeFast" BO_ 549 0;
BA_ "GenMsgSendType" BO_ 549 0;
BA_ "VFrameFormat" BO_ 549 14;
BA_ "CANFD_BRS" BO_ 549 1;
BA_ "GenMsgCycleTime" BO_ 549 20;
BA_ "GenMsgCycleTimeFast" BO_ 549 0;
BA_ "GenMsgSendType" BO_ 549 0;
BA_ "VFrameFormat" BO_ 549 14;
BA_ "CANFD_BRS" BO_ 549 1;
BA_ "GenMsgCycleTime" BO_ 549 20;
BA_ "GenMsgCycleTimeFast" BO_ 549 0;
BA_ "GenMsgSendType" BO_ 549 0;
BA_ "VFrameFormat" BO_ 549 14;
BA_ "CANFD_BRS" BO_ 549 1;
BA_ "GenMsgCycleTime" BO_ 549 20;
BA_ "GenMsgCycleTimeFast" BO_ 549 0;
BA_ "GenMsgSendType" BO_ 549 0;
BA_ "VFrameFormat" BO_ 549 14;
BA_ "CANFD_BRS" BO_ 549 1;
BA_ "GenMsgCycleTime" BO_ 549 20;
BA_ "GenMsgCycleTimeFast" BO_ 549 0;
BA_ "GenMsgSendType" BO_ 549 0;
BA_ "VFrameFormat" BO_ 549 14;
BA_ "CANFD_BRS" BO_ 549 1;
BA_ "GenMsgCycleTime" BO_ 549 20;
BA_ "GenMsgCycleTimeFast" BO_ 549 0;
BA_ "GenMsgSendType" BO_ 549 0;
BA_ "VFrameFormat" BO_ 549 14;
BA_ "CANFD_BRS" BO_ 549 1;
BA_ "GenMsgCycleTime" BO_ 549 20;
BA_ "GenMsgCycleTimeFast" BO_ 549 0;
BA_ "GenMsgSendType" BO_ 549 0;
BA_ "VFrameFormat" BO_ 549 14;
BA_ "CANFD_BRS" BO_ 549 1;
BA_ "GenMsgCycleTime" BO_ 549 20;
BA_ "GenMsgCycleTimeFast" BO_ 549 0;
BA_ "GenMsgSendType" BO_ 549 0;
BA_ "VFrameFormat" BO_ 549 14;
BA_ "CANFD_BRS" BO_ 549 1;
BA_ "GenMsgCycleTime" BO_ 549 20;
BA_ "GenMsgCycleTimeFast" BO_ 549 0;
BA_ "GenMsgSendType" BO_ 549 0;
BA_ "VFrameFormat" BO_ 549 14;
BA_ "CANFD_BRS" BO_ 549 1;
BA_ "GenMsgCycleTime" BO_ 549 20;
BA_ "GenMsgCycleTimeFast" BO_ 549 0;
BA_ "GenMsgSendType" BO_ 549 0;
BA_ "VFrameFormat" BO_ 549 14;
BA_ "CANFD_BRS" BO_ 549 1;
BA_ "GenMsgCycleTime" BO_ 549 20;
BA_ "GenMsgCycleTimeFast" BO_ 549 0;
BA_ "GenMsgSendType" BO_ 549 0;
BA_ "VFrameFormat" BO_ 549 14;
BA_ "CANFD_BRS" BO_ 549 1;
BA_ "GenMsgCycleTime" BO_ 549 20;
BA_ "GenMsgCycleTimeFast" BO_ 549 0;
BA_ "GenMsgSendType" BO_ 549 0;
BA_ "VFrameFormat" BO_ 549 14;
BA_ "CANFD_BRS" BO_ 549 1;
BA_ "GenMsgCycleTime" BO_ 549 20;
BA_ "GenMsgCycleTimeFast" BO_ 549 0;
BA_ "GenMsgSendType" BO_ 549 0;
BA_ "VFrameFormat" BO_ 549 14;
BA_ "CANFD_BRS" BO_ 549 1;
BA_ "GenMsgCycleTime" BO_ 549 20;
BA_ "GenMsgCycleTimeFast" BO_ 549 0;
BA_ "GenMsgSendType" BO_ 549 0;
BA_ "VFrameFormat" BO_ 549 14;
BA_ "CANFD_BRS" BO_ 549 1;
BA_ "GenMsgCycleTime" BO_ 549 20;
BA_ "GenMsgCycleTimeFast" BO_ 549 0;
BA_ "GenMsgSendType" BO_ 549 0;
BA_ "VFrameFormat" BO_ 549 14;
BA_ "CANFD_BRS" BO_ 549 1;
BA_ "GenMsgCycleTime" BO_ 549 20;
BA_ "GenMsgCycleTimeFast" BO_ 549 0;
BA_ "GenMsgSendType" BO_ 549 0;
BA_ "VFrameFormat" BO_ 549 14;
BA_ "CANFD_BRS" BO_ 549 1;
BA_ "GenMsgCycleTime" BO_ 549 20;
BA_ "GenMsgCycleTimeFast" BO_ 549 0;
BA_ "GenMsgSendType" BO_ 549 0;
BA_ "VFrameFormat" BO_ 549 14;
BA_ "CANFD_BRS" BO_ 549 1;
BA_ "GenMsgCycleTime" BO_ 549 20;
BA_ "GenMsgCycleTimeFast" BO_ 549 0;
BA_ "GenMsgSendType" BO_ 549 0;
BA_ "VFrameFormat" BO_ 549 14;
BA_ "CANFD_BRS" BO_ 549 1;
BA_ "GenMsgCycleTime" BO_ 549 20;
BA_ "GenMsgCycleTimeFast" BO_ 549 0;
BA_ "GenMsgSendType" BO_ 549 0;
BA_ "VFrameFormat" BO_ 549 14;
BA_ "CANFD_BRS" BO_ 549 1;
BA_ "GenMsgCycleTime" BO_ 549 20;
BA_ "GenMsgCycleTimeFast" BO_ 549 0;
BA_ "GenMsgSendType" BO_ 549 0;
BA_ "VFrameFormat" BO_ 549 14;
BA_ "CANFD_BRS" BO_ 549 1;
BA_ "GenMsgCycleTime" BO_ 549 20;
BA_ "GenMsgCycleTimeFast" BO_ 549 0;
BA_ "GenMsgSendType" BO_ 549 0;
BA_ "VFrameFormat" BO_ 549 14;
BA_ "CANFD_BRS" BO_ 549 1;
BA_ "GenMsgCycleTime" BO_ 549 20;
BA_ "GenMsgCycleTimeFast" BO_ 549 0;
BA_ "GenMsgSendType" BO_ 549 0;
BA_ "VFrameFormat" BO_ 549 14;
BA_ "CANFD_BRS" BO_ 549 1;
BA_ "GenMsgCycleTime" BO_ 549 20;
BA_ "GenMsgCycleTimeFast" BO_ 549 0;
BA_ "GenMsgSendType" BO_ 549 0;
BA_ "VFrameFormat" BO_ 549 14;
BA_ "CANFD_BRS" BO_ 549 1;
BA_ "GenMsgCycleTime" BO_ 549 20;
BA_ "GenMsgCycleTimeFast" BO_ 549 0;
BA_ "GenMsgSendType" BO_ 549 0;
BA_ "VFrameFormat" BO_ 549 14;
BA_ "CANFD_BRS" BO_ 549 1;
BA_ "GenMsgCycleTime" BO_ 549 20;
BA_ "GenMsgCycleTimeFast" BO_ 549 0;
BA_ "GenMsgSendType" BO_ 549 0;
BA_ "VFrameFormat" BO_ 549 14;
BA_ "CANFD_BRS" BO_ 549 1;
BA_ "GenMsgCycleTime" BO_ 549 20;
BA_ "GenMsgCycleTimeFast" BO_ 549 0;
BA_ "GenMsgSendType" BO_ 549 0;
BA_ "VFrameFormat" BO_ 549 14;
BA_ "CANFD_BRS" BO_ 549 1;
BA_ "GenMsgCycleTime" BO_ 549 20;
BA_ "GenMsgCycleTimeFast" BO_ 549 0;
BA_ "GenMsgSendType" BO_ 549 0;
BA_ "VFrameFormat" BO_ 549 14;
BA_ "CANFD_BRS" BO_ 549 1;
BA_ "GenMsgCycleTime" BO_ 549 20;
BA_ "GenMsgCycleTimeFast" BO_ 549 0;
BA_ "GenMsgSendType" BO_ 549 0;
BA_ "VFrameFormat" BO_ 549 14;
BA_ "CANFD_BRS" BO_ 549 1;
BA_ "GenMsgCycleTime" BO_ 549 20;
BA_ "GenMsgCycleTimeFast" BO_ 549 0;
BA_ "GenMsgSendType" BO_ 549 0;
BA_ "VFrameFormat" BO_ 549 14;
BA_ "CANFD_BRS" BO_ 549 1;
BA_ "GenMsgCycleTime" BO_ 549 20;
BA_ "GenMsgCycleTimeFast" BO_ 549 0;
BA_ "GenMsgSendType" BO_ 549 0;
BA_ "VFrameFormat" BO_ 549 14;
BA_ "CANFD_BRS" BO_ 549 1;
BA_ "GenMsgCycleTime" BO_ 549 20;
BA_ "GenMsgCycleTimeFast" BO_ 549 0;
BA_ "GenMsgSendType" BO_ 549 0;
BA_ "VFrameFormat" BO_ 549 14;
BA_ "CANFD_BRS" BO_ 549 1;
BA_ "GenMsgCycleTime" BO_ 549 20;
BA_ "GenMsgCycleTimeFast" BO_ 549 0;
BA_ "GenMsgSendType" BO_ 549 0;
BA_ "VFrameFormat" BO_ 549 14;
BA_ "CANFD_BRS" BO_ 549 1;
BA_ "GenMsgCycleTime" BO_ 549 20;
BA_ "GenMsgCycleTimeFast" BO_ 549 0;
BA_ "GenMsgSendType" BO_ 549 0;
BA_ "VFrameFormat" BO_ 549 14;
BA_ "CANFD_BRS" BO_ 549 1;
BA_ "GenMsgCycleTime" BO_ 549 20;
BA_ "GenMsgCycleTimeFast" BO_ 549 0;
BA_ "GenMsgSendType" BO_ 549 0;
BA_ "VFrameFormat" BO_ 549 14;
BA_ "CANFD_BRS" BO_ 549 1;
BA_ "GenMsgCycleTime" BO_ 549 20;
BA_ "GenMsgCycleTimeFast" BO_ 549 0;
BA_ "GenMsgSendType" BO_ 549 0;
BA_ "VFrameFormat" BO_ 549 14;
BA_ "CANFD_BRS" BO_ 549 1;
BA_ "GenMsgCycleTime" BO_ 549 20;
BA_ "GenMsgCycleTimeFast" BO_ 549 0;
BA_ "GenMsgSendType" BO_ 549 0;
BA_ "VFrameFormat" BO_ 549 14;
BA_ "CANFD_BRS" BO_ 549 1;
BA_ "GenMsgCycleTime" BO_ 549 20;
BA_ "GenMsgCycleTimeFast" BO_ 549 0;
BA_ "GenMsgSendType" BO_ 549 0;
BA_ "VFrameFormat" BO_ 549 14;
BA_ "CANFD_BRS" BO_ 549 1;
BA_ "GenMsgCycleTime" BO_ 549 20;
BA_ "GenMsgCycleTimeFast" BO_ 549 0;
BA_ "GenMsgSendType" BO_ 549 0;
BA_ "VFrameFormat" BO_ 549 14;
BA_ "CANFD_BRS" BO_ 549 1;
BA_ "GenMsgCycleTime" BO_ 549 20;
BA_ "GenMsgCycleTimeFast" BO_ 549 0;
BA_ "GenMsgSendType" BO_ 549 0;
BA_ "VFrameFormat" BO_ 549 14;
BA_ "CANFD_BRS" BO_ 549 1;
BA_ "GenMsgCycleTime" BO_ 549 20;
BA_ "GenMsgCycleTimeFast" BO_ 549 0;
BA_ "GenMsgSendType" BO_ 549 0;
BA_ "VFrameFormat" BO_ 549 14;
BA_ "CANFD_BRS" BO_ 549 1;
BA_ "GenMsgCycleTime" BO_ 549 20;
BA_ "GenMsgCycleTimeFast" BO_ 549 0;
BA_ "GenMsgSendType" BO_ 549 0;
BA_ "VFrameFormat" BO_ 549 14;
BA_ "CANFD_BRS" BO_ 549 1;
BA_ "GenMsgCycleTime" BO_ 549 20;
BA_ "GenMsgCycleTimeFast" BO_ 549 0;
BA_ "GenMsgSendType" BO_ 549 0;
BA_ "VFrameFormat" BO_ 549 14;
BA_ "CANFD_BRS" BO_ 549 1;
BA_ "GenMsgCycleTime" BO_ 549 20;
BA_ "GenMsgCycleTimeFast" BO_ 549 0;
BA_ "GenMsgSendType" BO_ 549 0;
BA_ "VFrameFormat" BO_ 549 14;
BA_ "CANFD_BRS" BO_ 549 1;
BA_ "GenMsgCycleTime" BO_ 549 20;
BA_ "GenMsgCycleTimeFast" BO_ 549 0;
BA_ "GenMsgSendType" BO_ 549 0;
BA_ "VFrameFormat" BO_ 549 14;
BA_ "CANFD_BRS" BO_ 549 1;
BA_ "GenMsgCycleTime" BO_ 549 20;
BA_ "GenMsgCycleTimeFast" BO_ 549 0;
BA_ "GenMsgSendType" BO_ 549 0;
BA_ "VFrameFormat" BO_ 549 14;
BA_ "CANFD_BRS" BO_ 549 1;
BA_ "GenMsgCycleTime" BO_ 549 20;
BA_ "GenMsgCycleTimeFast" BO_ 549 0;
BA_ "GenMsgSendType" BO_ 549 0;
BA_ "VFrameFormat" BO_ 549 14;
BA_ "CANFD_BRS" BO_ 549 1;
BA_ "GenMsgCycleTime" BO_ 549 20;
BA_ "GenMsgCycleTimeFast" BO_ 549 0;
BA_ "GenMsgSendType" BO_ 549 0;
BA_ "VFrameFormat" BO_ 549 14;
BA_ "CANFD_BRS" BO_ 549 1;
BA_ "GenMsgCycleTime" BO_ 549 20;
BA_ "GenMsgCycleTimeFast" BO_ 549 0;
BA_ "GenMsgSendType" BO_ 549 0;
BA_ "VFrameFormat" BO_ 549 14;
BA_ "CANFD_BRS" BO_ 549 1;
BA_ "GenMsgCycleTime" BO_ 549 20;
BA_ "GenMsgCycleTimeFast" BO_ 549 0;
BA_ "GenMsgSendType" BO_ 549 0;
BA_ "VFrameFormat" BO_ 549 14;
BA_ "CANFD_BRS" BO_ 549 1;
BA_ "GenMsgCycleTime" BO_ 549 20;
BA_ "GenMsgCycleTimeFast" BO_ 549 0;
BA_ "GenMsgSendType" BO_ 549 0;
BA_ "VFrameFormat" BO_ 549 14;
BA_ "CANFD_BRS" BO_ 549 1;
BA_ "GenMsgCycleTime" BO_ 549 20;
BA_ "GenMsgCycleTimeFast" BO_ 549 0;
BA_ "GenMsgSendType" BO_ 549 0;
BA_ "VFrameFormat" BO_ 549 14;
BA_ "CANFD_BRS" BO_ 549 1;
BA_ "GenMsgCycleTime" BO_ 549 20;
BA_ "GenMsgCycleTimeFast" BO_ 549 0;
BA_ "GenMsgSendType" BO_ 549 0;
BA_ "VFrameFormat" BO_ 549 14;
BA_ "CANFD_BRS" BO_ 549 1;
BA_ "GenMsgCycleTime" BO_ 549 20;
BA_ "GenMsgCycleTimeFast" BO_ 549 0;
BA_ "GenMsgSendType" BO_ 549 0;
BA_ "VFrameFormat" BO_ 549 14;
BA_ "CANFD_BRS" BO_ 549 1;
BA_ "GenMsgCycleTime" BO_ 549 20;
BA_ "GenMsgCycleTimeFast" BO_ 549 0;
BA_ "GenMsgSendType" BO_ 549 0;
BA_ "VFrameFormat" BO_ 549 14;
BA_ "CANFD_BRS" BO_ 549 1;
BA_ "GenMsgCycleTime" BO_ 549 20;
BA_ "GenMsgCycleTimeFast" BO_ 549 0;
BA_ "GenMsgSendType" BO_ 549 0;
BA_ "VFrameFormat" BO_ 549 14;
BA_ "CANFD_BRS" BO_ 549 1;
BA_ "GenMsgCycleTime" BO_ 549 20;
BA_ "GenMsgCycleTimeFast" BO_ 549 0;
BA_ "GenMsgSendType" BO_ 549 0;
BA_ "VFrameFormat" BO_ 549 14;
BA_ "CANFD_BRS" BO_ 549 1;
BA_ "GenMsgCycleTime" BO_ 549 20;
BA_ "GenMsgCycleTimeFast" BO_ 549 0;
BA_ "GenMsgSendType" BO_ 549 0;
BA_ "VFrameFormat" BO_ 549 14;
BA_ "CANFD_BRS" BO_ 549 1;
BA_ "GenMsgCycleTime" BO_ 549 20;
BA_ "GenMsgCycleTimeFast" BO_ 549 0;
BA_ "GenMsgSendType" BO_ 549 0;
BA_ "VFrameFormat" BO_ 549 14;
BA_ "CANFD_BRS" BO_ 549 1;
BA_ "GenMsgCycleTime" BO_ 549 20;
BA_ "GenMsgCycleTimeFast" BO_ 549 0;
BA_ "GenMsgSendType" BO_ 549 0;
BA_ "VFrameFormat" BO_ 549 14;
BA_ "CANFD_BRS" BO_ 549 1;
BA_ "GenMsgCycleTime" BO_ 549 20;
BA_ "GenMsgCycleTimeFast" BO_ 549 0;
BA_ "GenMsgSendType" BO_ 549 0;
BA_ "VFrameFormat" BO_ 549 14;
BA_ "CANFD_BRS" BO_ 549 1;
BA_ "GenMsgCycleTime" BO_ 1359 200;
BA_ "GenMsgCycleTimeFast" BO_ 1359 0;
BA_ "GenMsgSendType" BO_ 1359 0;
BA_ "VFrameFormat" BO_ 1359 0;
BA_ "CANFD_BRS" BO_ 1359 1;
BA_ "GenMsgCycleTime" BO_ 1359 200;
BA_ "GenMsgCycleTimeFast" BO_ 1359 0;
BA_ "GenMsgSendType" BO_ 1359 0;
BA_ "VFrameFormat" BO_ 1359 0;
BA_ "CANFD_BRS" BO_ 1359 1;
BA_ "GenMsgCycleTime" BO_ 1359 200;
BA_ "GenMsgCycleTimeFast" BO_ 1359 0;
BA_ "GenMsgSendType" BO_ 1359 0;
BA_ "VFrameFormat" BO_ 1359 0;
BA_ "CANFD_BRS" BO_ 1359 1;
BA_ "GenMsgCycleTime" BO_ 1359 200;
BA_ "GenMsgCycleTimeFast" BO_ 1359 0;
BA_ "GenMsgSendType" BO_ 1359 0;
BA_ "VFrameFormat" BO_ 1359 0;
BA_ "CANFD_BRS" BO_ 1359 1;
BA_ "GenMsgCycleTime" BO_ 1359 200;
BA_ "GenMsgCycleTimeFast" BO_ 1359 0;
BA_ "GenMsgSendType" BO_ 1359 0;
BA_ "VFrameFormat" BO_ 1359 0;
BA_ "CANFD_BRS" BO_ 1359 1;
BA_ "GenMsgCycleTime" BO_ 1359 200;
BA_ "GenMsgCycleTimeFast" BO_ 1359 0;
BA_ "GenMsgSendType" BO_ 1359 0;
BA_ "VFrameFormat" BO_ 1359 0;
BA_ "CANFD_BRS" BO_ 1359 1;
BA_ "GenMsgCycleTime" BO_ 905 100;
BA_ "GenMsgCycleTimeFast" BO_ 905 0;
BA_ "GenMsgSendType" BO_ 905 0;
BA_ "VFrameFormat" BO_ 905 14;
BA_ "CANFD_BRS" BO_ 905 1;
BA_ "GenMsgCycleTime" BO_ 905 100;
BA_ "GenMsgCycleTimeFast" BO_ 905 0;
BA_ "GenMsgSendType" BO_ 905 0;
BA_ "VFrameFormat" BO_ 905 14;
BA_ "CANFD_BRS" BO_ 905 1;
BA_ "GenMsgCycleTime" BO_ 905 100;
BA_ "GenMsgCycleTimeFast" BO_ 905 0;
BA_ "GenMsgSendType" BO_ 905 0;
BA_ "VFrameFormat" BO_ 905 14;
BA_ "CANFD_BRS" BO_ 905 1;
BA_ "GenMsgCycleTime" BO_ 905 100;
BA_ "GenMsgCycleTimeFast" BO_ 905 0;
BA_ "GenMsgSendType" BO_ 905 0;
BA_ "VFrameFormat" BO_ 905 14;
BA_ "CANFD_BRS" BO_ 905 1;
BA_ "GenMsgCycleTime" BO_ 905 100;
BA_ "GenMsgCycleTimeFast" BO_ 905 0;
BA_ "GenMsgSendType" BO_ 905 0;
BA_ "VFrameFormat" BO_ 905 14;
BA_ "CANFD_BRS" BO_ 905 1;
BA_ "GenMsgCycleTime" BO_ 905 100;
BA_ "GenMsgCycleTimeFast" BO_ 905 0;
BA_ "GenMsgSendType" BO_ 905 0;
BA_ "VFrameFormat" BO_ 905 14;
BA_ "CANFD_BRS" BO_ 905 1;
BA_ "GenMsgCycleTime" BO_ 516 20;
BA_ "GenMsgCycleTimeFast" BO_ 516 0;
BA_ "GenMsgSendType" BO_ 516 0;
BA_ "VFrameFormat" BO_ 516 14;
BA_ "CANFD_BRS" BO_ 516 1;
BA_ "GenMsgCycleTime" BO_ 516 20;
BA_ "GenMsgCycleTimeFast" BO_ 516 0;
BA_ "GenMsgSendType" BO_ 516 0;
BA_ "VFrameFormat" BO_ 516 14;
BA_ "CANFD_BRS" BO_ 516 1;
BA_ "GenMsgCycleTime" BO_ 516 20;
BA_ "GenMsgCycleTimeFast" BO_ 516 0;
BA_ "GenMsgSendType" BO_ 516 0;
BA_ "VFrameFormat" BO_ 516 14;
BA_ "CANFD_BRS" BO_ 516 1;
BA_ "GenMsgCycleTime" BO_ 516 20;
BA_ "GenMsgCycleTimeFast" BO_ 516 0;
BA_ "GenMsgSendType" BO_ 516 0;
BA_ "VFrameFormat" BO_ 516 14;
BA_ "CANFD_BRS" BO_ 516 1;
BA_ "GenMsgCycleTime" BO_ 516 20;
BA_ "GenMsgCycleTimeFast" BO_ 516 0;
BA_ "GenMsgSendType" BO_ 516 0;
BA_ "VFrameFormat" BO_ 516 14;
BA_ "CANFD_BRS" BO_ 516 1;
BA_ "GenMsgCycleTime" BO_ 516 20;
BA_ "GenMsgCycleTimeFast" BO_ 516 0;
BA_ "GenMsgSendType" BO_ 516 0;
BA_ "VFrameFormat" BO_ 516 14;
BA_ "CANFD_BRS" BO_ 516 1;
BA_ "GenMsgCycleTime" BO_ 516 20;
BA_ "GenMsgCycleTimeFast" BO_ 516 0;
BA_ "GenMsgSendType" BO_ 516 0;
BA_ "VFrameFormat" BO_ 516 14;
BA_ "CANFD_BRS" BO_ 516 1;
BA_ "GenMsgCycleTime" BO_ 516 20;
BA_ "GenMsgCycleTimeFast" BO_ 516 0;
BA_ "GenMsgSendType" BO_ 516 0;
BA_ "VFrameFormat" BO_ 516 14;
BA_ "CANFD_BRS" BO_ 516 1;
BA_ "GenMsgCycleTime" BO_ 516 20;
BA_ "GenMsgCycleTimeFast" BO_ 516 0;
BA_ "GenMsgSendType" BO_ 516 0;
BA_ "VFrameFormat" BO_ 516 14;
BA_ "CANFD_BRS" BO_ 516 1;
BA_ "GenMsgCycleTime" BO_ 516 20;
BA_ "GenMsgCycleTimeFast" BO_ 516 0;
BA_ "GenMsgSendType" BO_ 516 0;
BA_ "VFrameFormat" BO_ 516 14;
BA_ "CANFD_BRS" BO_ 516 1;
BA_ "GenMsgCycleTime" BO_ 516 20;
BA_ "GenMsgCycleTimeFast" BO_ 516 0;
BA_ "GenMsgSendType" BO_ 516 0;
BA_ "VFrameFormat" BO_ 516 14;
BA_ "CANFD_BRS" BO_ 516 1;
BA_ "GenMsgCycleTime" BO_ 516 20;
BA_ "GenMsgCycleTimeFast" BO_ 516 0;
BA_ "GenMsgSendType" BO_ 516 0;
BA_ "VFrameFormat" BO_ 516 14;
BA_ "CANFD_BRS" BO_ 516 1;
BA_ "GenMsgCycleTime" BO_ 516 20;
BA_ "GenMsgCycleTimeFast" BO_ 516 0;
BA_ "GenMsgSendType" BO_ 516 0;
BA_ "VFrameFormat" BO_ 516 14;
BA_ "CANFD_BRS" BO_ 516 1;
BA_ "GenMsgCycleTime" BO_ 516 20;
BA_ "GenMsgCycleTimeFast" BO_ 516 0;
BA_ "GenMsgSendType" BO_ 516 0;
BA_ "VFrameFormat" BO_ 516 14;
BA_ "CANFD_BRS" BO_ 516 1;
BA_ "GenMsgCycleTime" BO_ 516 20;
BA_ "GenMsgCycleTimeFast" BO_ 516 0;
BA_ "GenMsgSendType" BO_ 516 0;
BA_ "VFrameFormat" BO_ 516 14;
BA_ "CANFD_BRS" BO_ 516 1;
BA_ "GenMsgCycleTime" BO_ 516 20;
BA_ "GenMsgCycleTimeFast" BO_ 516 0;
BA_ "GenMsgSendType" BO_ 516 0;
BA_ "VFrameFormat" BO_ 516 14;
BA_ "CANFD_BRS" BO_ 516 1;
BA_ "GenMsgCycleTime" BO_ 516 20;
BA_ "GenMsgCycleTimeFast" BO_ 516 0;
BA_ "GenMsgSendType" BO_ 516 0;
BA_ "VFrameFormat" BO_ 516 14;
BA_ "CANFD_BRS" BO_ 516 1;
BA_ "GenMsgCycleTime" BO_ 516 20;
BA_ "GenMsgCycleTimeFast" BO_ 516 0;
BA_ "GenMsgSendType" BO_ 516 0;
BA_ "VFrameFormat" BO_ 516 14;
BA_ "CANFD_BRS" BO_ 516 1;
BA_ "GenMsgCycleTime" BO_ 516 20;
BA_ "GenMsgCycleTimeFast" BO_ 516 0;
BA_ "GenMsgSendType" BO_ 516 0;
BA_ "VFrameFormat" BO_ 516 14;
BA_ "CANFD_BRS" BO_ 516 1;
BA_ "GenMsgCycleTime" BO_ 516 20;
BA_ "GenMsgCycleTimeFast" BO_ 516 0;
BA_ "GenMsgSendType" BO_ 516 0;
BA_ "VFrameFormat" BO_ 516 14;
BA_ "CANFD_BRS" BO_ 516 1;
BA_ "GenMsgCycleTime" BO_ 516 20;
BA_ "GenMsgCycleTimeFast" BO_ 516 0;
BA_ "GenMsgSendType" BO_ 516 0;
BA_ "VFrameFormat" BO_ 516 14;
BA_ "CANFD_BRS" BO_ 516 1;
BA_ "GenMsgCycleTime" BO_ 516 20;
BA_ "GenMsgCycleTimeFast" BO_ 516 0;
BA_ "GenMsgSendType" BO_ 516 0;
BA_ "VFrameFormat" BO_ 516 14;
BA_ "CANFD_BRS" BO_ 516 1;
BA_ "GenMsgCycleTime" BO_ 516 20;
BA_ "GenMsgCycleTimeFast" BO_ 516 0;
BA_ "GenMsgSendType" BO_ 516 0;
BA_ "VFrameFormat" BO_ 516 14;
BA_ "CANFD_BRS" BO_ 516 1;
BA_ "GenMsgCycleTime" BO_ 516 20;
BA_ "GenMsgCycleTimeFast" BO_ 516 0;
BA_ "GenMsgSendType" BO_ 516 0;
BA_ "VFrameFormat" BO_ 516 14;
BA_ "CANFD_BRS" BO_ 516 1;
BA_ "GenMsgCycleTime" BO_ 516 20;
BA_ "GenMsgCycleTimeFast" BO_ 516 0;
BA_ "GenMsgSendType" BO_ 516 0;
BA_ "VFrameFormat" BO_ 516 14;
BA_ "CANFD_BRS" BO_ 516 1;
BA_ "GenMsgCycleTime" BO_ 516 20;
BA_ "GenMsgCycleTimeFast" BO_ 516 0;
BA_ "GenMsgSendType" BO_ 516 0;
BA_ "VFrameFormat" BO_ 516 14;
BA_ "CANFD_BRS" BO_ 516 1;
BA_ "GenMsgCycleTime" BO_ 516 20;
BA_ "GenMsgCycleTimeFast" BO_ 516 0;
BA_ "GenMsgSendType" BO_ 516 0;
BA_ "VFrameFormat" BO_ 516 14;
BA_ "CANFD_BRS" BO_ 516 1;
BA_ "GenMsgCycleTime" BO_ 516 20;
BA_ "GenMsgCycleTimeFast" BO_ 516 0;
BA_ "GenMsgSendType" BO_ 516 0;
BA_ "VFrameFormat" BO_ 516 14;
BA_ "CANFD_BRS" BO_ 516 1;
BA_ "GenMsgCycleTime" BO_ 516 20;
BA_ "GenMsgCycleTimeFast" BO_ 516 0;
BA_ "GenMsgSendType" BO_ 516 0;
BA_ "VFrameFormat" BO_ 516 14;
BA_ "CANFD_BRS" BO_ 516 1;
BA_ "GenMsgCycleTime" BO_ 516 20;
BA_ "GenMsgCycleTimeFast" BO_ 516 0;
BA_ "GenMsgSendType" BO_ 516 0;
BA_ "VFrameFormat" BO_ 516 14;
BA_ "CANFD_BRS" BO_ 516 1;
BA_ "GenMsgCycleTime" BO_ 516 20;
BA_ "GenMsgCycleTimeFast" BO_ 516 0;
BA_ "GenMsgSendType" BO_ 516 0;
BA_ "VFrameFormat" BO_ 516 14;
BA_ "CANFD_BRS" BO_ 516 1;
BA_ "GenMsgCycleTime" BO_ 516 20;
BA_ "GenMsgCycleTimeFast" BO_ 516 0;
BA_ "GenMsgSendType" BO_ 516 0;
BA_ "VFrameFormat" BO_ 516 14;
BA_ "CANFD_BRS" BO_ 516 1;
BA_ "GenMsgCycleTime" BO_ 516 20;
BA_ "GenMsgCycleTimeFast" BO_ 516 0;
BA_ "GenMsgSendType" BO_ 516 0;
BA_ "VFrameFormat" BO_ 516 14;
BA_ "CANFD_BRS" BO_ 516 1;
BA_ "GenMsgCycleTime" BO_ 909 100;
BA_ "GenMsgCycleTimeFast" BO_ 909 0;
BA_ "GenMsgSendType" BO_ 909 0;
BA_ "VFrameFormat" BO_ 909 14;
BA_ "CANFD_BRS" BO_ 909 1;
BA_ "GenMsgCycleTime" BO_ 909 100;
BA_ "GenMsgCycleTimeFast" BO_ 909 0;
BA_ "GenMsgSendType" BO_ 909 0;
BA_ "VFrameFormat" BO_ 909 14;
BA_ "CANFD_BRS" BO_ 909 1;
BA_ "GenMsgCycleTime" BO_ 909 100;
BA_ "GenMsgCycleTimeFast" BO_ 909 0;
BA_ "GenMsgSendType" BO_ 909 0;
BA_ "VFrameFormat" BO_ 909 14;
BA_ "CANFD_BRS" BO_ 909 1;
BA_ "GenMsgCycleTime" BO_ 909 100;
BA_ "GenMsgCycleTimeFast" BO_ 909 0;
BA_ "GenMsgSendType" BO_ 909 0;
BA_ "VFrameFormat" BO_ 909 14;
BA_ "CANFD_BRS" BO_ 909 1;
BA_ "GenMsgCycleTime" BO_ 909 100;
BA_ "GenMsgCycleTimeFast" BO_ 909 0;
BA_ "GenMsgSendType" BO_ 909 0;
BA_ "VFrameFormat" BO_ 909 14;
BA_ "CANFD_BRS" BO_ 909 1;
BA_ "GenMsgCycleTime" BO_ 909 100;
BA_ "GenMsgCycleTimeFast" BO_ 909 0;
BA_ "GenMsgSendType" BO_ 909 0;
BA_ "VFrameFormat" BO_ 909 14;
BA_ "CANFD_BRS" BO_ 909 1;
BA_ "GenMsgCycleTime" BO_ 909 100;
BA_ "GenMsgCycleTimeFast" BO_ 909 0;
BA_ "GenMsgSendType" BO_ 909 0;
BA_ "VFrameFormat" BO_ 909 14;
BA_ "CANFD_BRS" BO_ 909 1;
BA_ "GenMsgCycleTime" BO_ 909 100;
BA_ "GenMsgCycleTimeFast" BO_ 909 0;
BA_ "GenMsgSendType" BO_ 909 0;
BA_ "VFrameFormat" BO_ 909 14;
BA_ "CANFD_BRS" BO_ 909 1;
BA_ "GenMsgCycleTime" BO_ 909 100;
BA_ "GenMsgCycleTimeFast" BO_ 909 0;
BA_ "GenMsgSendType" BO_ 909 0;
BA_ "VFrameFormat" BO_ 909 14;
BA_ "CANFD_BRS" BO_ 909 1;
BA_ "GenMsgCycleTime" BO_ 909 100;
BA_ "GenMsgCycleTimeFast" BO_ 909 0;
BA_ "GenMsgSendType" BO_ 909 0;
BA_ "VFrameFormat" BO_ 909 14;
BA_ "CANFD_BRS" BO_ 909 1;
BA_ "GenMsgCycleTime" BO_ 909 100;
BA_ "GenMsgCycleTimeFast" BO_ 909 0;
BA_ "GenMsgSendType" BO_ 909 0;
BA_ "VFrameFormat" BO_ 909 14;
BA_ "CANFD_BRS" BO_ 909 1;
BA_ "GenMsgCycleTime" BO_ 909 100;
BA_ "GenMsgCycleTimeFast" BO_ 909 0;
BA_ "GenMsgSendType" BO_ 909 0;
BA_ "VFrameFormat" BO_ 909 14;
BA_ "CANFD_BRS" BO_ 909 1;
BA_ "GenMsgCycleTime" BO_ 909 100;
BA_ "GenMsgCycleTimeFast" BO_ 909 0;
BA_ "GenMsgSendType" BO_ 909 0;
BA_ "VFrameFormat" BO_ 909 14;
BA_ "CANFD_BRS" BO_ 909 1;
BA_ "GenMsgCycleTime" BO_ 909 100;
BA_ "GenMsgCycleTimeFast" BO_ 909 0;
BA_ "GenMsgSendType" BO_ 909 0;
BA_ "VFrameFormat" BO_ 909 14;
BA_ "CANFD_BRS" BO_ 909 1;
BA_ "GenMsgCycleTime" BO_ 909 100;
BA_ "GenMsgCycleTimeFast" BO_ 909 0;
BA_ "GenMsgSendType" BO_ 909 0;
BA_ "VFrameFormat" BO_ 909 14;
BA_ "CANFD_BRS" BO_ 909 1;
BA_ "GenMsgCycleTime" BO_ 909 100;
BA_ "GenMsgCycleTimeFast" BO_ 909 0;
BA_ "GenMsgSendType" BO_ 909 0;
BA_ "VFrameFormat" BO_ 909 14;
BA_ "CANFD_BRS" BO_ 909 1;
BA_ "GenMsgCycleTime" BO_ 909 100;
BA_ "GenMsgCycleTimeFast" BO_ 909 0;
BA_ "GenMsgSendType" BO_ 909 0;
BA_ "VFrameFormat" BO_ 909 14;
BA_ "CANFD_BRS" BO_ 909 1;
BA_ "GenMsgCycleTime" BO_ 909 100;
BA_ "GenMsgCycleTimeFast" BO_ 909 0;
BA_ "GenMsgSendType" BO_ 909 0;
BA_ "VFrameFormat" BO_ 909 14;
BA_ "CANFD_BRS" BO_ 909 1;
BA_ "GenMsgCycleTime" BO_ 909 100;
BA_ "GenMsgCycleTimeFast" BO_ 909 0;
BA_ "GenMsgSendType" BO_ 909 0;
BA_ "VFrameFormat" BO_ 909 14;
BA_ "CANFD_BRS" BO_ 909 1;
BA_ "GenMsgCycleTime" BO_ 909 100;
BA_ "GenMsgCycleTimeFast" BO_ 909 0;
BA_ "GenMsgSendType" BO_ 909 0;
BA_ "VFrameFormat" BO_ 909 14;
BA_ "CANFD_BRS" BO_ 909 1;
BA_ "GenMsgCycleTime" BO_ 909 100;
BA_ "GenMsgCycleTimeFast" BO_ 909 0;
BA_ "GenMsgSendType" BO_ 909 0;
BA_ "VFrameFormat" BO_ 909 14;
BA_ "CANFD_BRS" BO_ 909 1;
BA_ "GenMsgCycleTime" BO_ 909 100;
BA_ "GenMsgCycleTimeFast" BO_ 909 0;
BA_ "GenMsgSendType" BO_ 909 0;
BA_ "VFrameFormat" BO_ 909 14;
BA_ "CANFD_BRS" BO_ 909 1;
BA_ "GenMsgCycleTime" BO_ 909 100;
BA_ "GenMsgCycleTimeFast" BO_ 909 0;
BA_ "GenMsgSendType" BO_ 909 0;
BA_ "VFrameFormat" BO_ 909 14;
BA_ "CANFD_BRS" BO_ 909 1;
BA_ "GenMsgCycleTime" BO_ 909 100;
BA_ "GenMsgCycleTimeFast" BO_ 909 0;
BA_ "GenMsgSendType" BO_ 909 0;
BA_ "VFrameFormat" BO_ 909 14;
BA_ "CANFD_BRS" BO_ 909 1;
BA_ "GenMsgCycleTime" BO_ 909 100;
BA_ "GenMsgCycleTimeFast" BO_ 909 0;
BA_ "GenMsgSendType" BO_ 909 0;
BA_ "VFrameFormat" BO_ 909 14;
BA_ "CANFD_BRS" BO_ 909 1;
BA_ "GenMsgCycleTime" BO_ 909 100;
BA_ "GenMsgCycleTimeFast" BO_ 909 0;
BA_ "GenMsgSendType" BO_ 909 0;
BA_ "VFrameFormat" BO_ 909 14;
BA_ "CANFD_BRS" BO_ 909 1;
BA_ "GenMsgCycleTime" BO_ 909 100;
BA_ "GenMsgCycleTimeFast" BO_ 909 0;
BA_ "GenMsgSendType" BO_ 909 0;
BA_ "VFrameFormat" BO_ 909 14;
BA_ "CANFD_BRS" BO_ 909 1;
BA_ "GenMsgCycleTime" BO_ 909 100;
BA_ "GenMsgCycleTimeFast" BO_ 909 0;
BA_ "GenMsgSendType" BO_ 909 0;
BA_ "VFrameFormat" BO_ 909 14;
BA_ "CANFD_BRS" BO_ 909 1;
BA_ "GenMsgCycleTime" BO_ 909 100;
BA_ "GenMsgCycleTimeFast" BO_ 909 0;
BA_ "GenMsgSendType" BO_ 909 0;
BA_ "VFrameFormat" BO_ 909 14;
BA_ "CANFD_BRS" BO_ 909 1;
BA_ "GenMsgCycleTime" BO_ 909 100;
BA_ "GenMsgCycleTimeFast" BO_ 909 0;
BA_ "GenMsgSendType" BO_ 909 0;
BA_ "VFrameFormat" BO_ 909 14;
BA_ "CANFD_BRS" BO_ 909 1;
BA_ "GenMsgCycleTime" BO_ 909 100;
BA_ "GenMsgCycleTimeFast" BO_ 909 0;
BA_ "GenMsgSendType" BO_ 909 0;
BA_ "VFrameFormat" BO_ 909 14;
BA_ "CANFD_BRS" BO_ 909 1;
BA_ "GenMsgCycleTime" BO_ 909 100;
BA_ "GenMsgCycleTimeFast" BO_ 909 0;
BA_ "GenMsgSendType" BO_ 909 0;
BA_ "VFrameFormat" BO_ 909 14;
BA_ "CANFD_BRS" BO_ 909 1;
BA_ "GenMsgCycleTime" BO_ 909 100;
BA_ "GenMsgCycleTimeFast" BO_ 909 0;
BA_ "GenMsgSendType" BO_ 909 0;
BA_ "VFrameFormat" BO_ 909 14;
BA_ "CANFD_BRS" BO_ 909 1;
BA_ "GenMsgCycleTime" BO_ 909 100;
BA_ "GenMsgCycleTimeFast" BO_ 909 0;
BA_ "GenMsgSendType" BO_ 909 0;
BA_ "VFrameFormat" BO_ 909 14;
BA_ "CANFD_BRS" BO_ 909 1;
BA_ "GenMsgCycleTime" BO_ 909 100;
BA_ "GenMsgCycleTimeFast" BO_ 909 0;
BA_ "GenMsgSendType" BO_ 909 0;
BA_ "VFrameFormat" BO_ 909 14;
BA_ "CANFD_BRS" BO_ 909 1;
BA_ "GenMsgCycleTime" BO_ 909 100;
BA_ "GenMsgCycleTimeFast" BO_ 909 0;
BA_ "GenMsgSendType" BO_ 909 0;
BA_ "VFrameFormat" BO_ 909 14;
BA_ "CANFD_BRS" BO_ 909 1;
BA_ "GenMsgCycleTime" BO_ 909 100;
BA_ "GenMsgCycleTimeFast" BO_ 909 0;
BA_ "GenMsgSendType" BO_ 909 0;
BA_ "VFrameFormat" BO_ 909 14;
BA_ "CANFD_BRS" BO_ 909 1;
BA_ "GenMsgCycleTime" BO_ 909 100;
BA_ "GenMsgCycleTimeFast" BO_ 909 0;
BA_ "GenMsgSendType" BO_ 909 0;
BA_ "VFrameFormat" BO_ 909 14;
BA_ "CANFD_BRS" BO_ 909 1;
BA_ "GenMsgCycleTime" BO_ 909 100;
BA_ "GenMsgCycleTimeFast" BO_ 909 0;
BA_ "GenMsgSendType" BO_ 909 0;
BA_ "VFrameFormat" BO_ 909 14;
BA_ "CANFD_BRS" BO_ 909 1;
BA_ "GenMsgCycleTime" BO_ 909 100;
BA_ "GenMsgCycleTimeFast" BO_ 909 0;
BA_ "GenMsgSendType" BO_ 909 0;
BA_ "VFrameFormat" BO_ 909 14;
BA_ "CANFD_BRS" BO_ 909 1;
BA_ "GenMsgCycleTime" BO_ 909 100;
BA_ "GenMsgCycleTimeFast" BO_ 909 0;
BA_ "GenMsgSendType" BO_ 909 0;
BA_ "VFrameFormat" BO_ 909 14;
BA_ "CANFD_BRS" BO_ 909 1;
BA_ "GenMsgCycleTime" BO_ 909 100;
BA_ "GenMsgCycleTimeFast" BO_ 909 0;
BA_ "GenMsgSendType" BO_ 909 0;
BA_ "VFrameFormat" BO_ 909 14;
BA_ "CANFD_BRS" BO_ 909 1;
BA_ "GenMsgCycleTime" BO_ 909 100;
BA_ "GenMsgCycleTimeFast" BO_ 909 0;
BA_ "GenMsgSendType" BO_ 909 0;
BA_ "VFrameFormat" BO_ 909 14;
BA_ "CANFD_BRS" BO_ 909 1;
BA_ "GenMsgCycleTime" BO_ 909 100;
BA_ "GenMsgCycleTimeFast" BO_ 909 0;
BA_ "GenMsgSendType" BO_ 909 0;
BA_ "VFrameFormat" BO_ 909 14;
BA_ "CANFD_BRS" BO_ 909 1;
BA_ "GenMsgCycleTime" BO_ 909 100;
BA_ "GenMsgCycleTimeFast" BO_ 909 0;
BA_ "GenMsgSendType" BO_ 909 0;
BA_ "VFrameFormat" BO_ 909 14;
BA_ "CANFD_BRS" BO_ 909 1;
BA_ "GenMsgCycleTime" BO_ 909 100;
BA_ "GenMsgCycleTimeFast" BO_ 909 0;
BA_ "GenMsgSendType" BO_ 909 0;
BA_ "VFrameFormat" BO_ 909 14;
BA_ "CANFD_BRS" BO_ 909 1;
BA_ "GenMsgCycleTime" BO_ 909 100;
BA_ "GenMsgCycleTimeFast" BO_ 909 0;
BA_ "GenMsgSendType" BO_ 909 0;
BA_ "VFrameFormat" BO_ 909 14;
BA_ "CANFD_BRS" BO_ 909 1;
BA_ "GenMsgCycleTime" BO_ 792 100;
BA_ "GenMsgCycleTimeFast" BO_ 792 0;
BA_ "GenMsgSendType" BO_ 792 0;
BA_ "VFrameFormat" BO_ 792 14;
BA_ "CANFD_BRS" BO_ 792 1;
BA_ "GenMsgCycleTime" BO_ 792 100;
BA_ "GenMsgCycleTimeFast" BO_ 792 0;
BA_ "GenMsgSendType" BO_ 792 0;
BA_ "VFrameFormat" BO_ 792 14;
BA_ "CANFD_BRS" BO_ 792 1;
BA_ "GenMsgCycleTime" BO_ 792 100;
BA_ "GenMsgCycleTimeFast" BO_ 792 0;
BA_ "GenMsgSendType" BO_ 792 0;
BA_ "VFrameFormat" BO_ 792 14;
BA_ "CANFD_BRS" BO_ 792 1;
BA_ "GenMsgCycleTime" BO_ 792 100;
BA_ "GenMsgCycleTimeFast" BO_ 792 0;
BA_ "GenMsgSendType" BO_ 792 0;
BA_ "VFrameFormat" BO_ 792 14;
BA_ "CANFD_BRS" BO_ 792 1;
BA_ "GenMsgCycleTime" BO_ 792 100;
BA_ "GenMsgCycleTimeFast" BO_ 792 0;
BA_ "GenMsgSendType" BO_ 792 0;
BA_ "VFrameFormat" BO_ 792 14;
BA_ "CANFD_BRS" BO_ 792 1;
BA_ "GenMsgCycleTime" BO_ 792 100;
BA_ "GenMsgCycleTimeFast" BO_ 792 0;
BA_ "GenMsgSendType" BO_ 792 0;
BA_ "VFrameFormat" BO_ 792 14;
BA_ "CANFD_BRS" BO_ 792 1;
BA_ "GenMsgCycleTime" BO_ 792 100;
BA_ "GenMsgCycleTimeFast" BO_ 792 0;
BA_ "GenMsgSendType" BO_ 792 0;
BA_ "VFrameFormat" BO_ 792 14;
BA_ "CANFD_BRS" BO_ 792 1;
BA_ "GenMsgCycleTime" BO_ 792 100;
BA_ "GenMsgCycleTimeFast" BO_ 792 0;
BA_ "GenMsgSendType" BO_ 792 0;
BA_ "VFrameFormat" BO_ 792 14;
BA_ "CANFD_BRS" BO_ 792 1;
BA_ "GenMsgCycleTime" BO_ 792 100;
BA_ "GenMsgCycleTimeFast" BO_ 792 0;
BA_ "GenMsgSendType" BO_ 792 0;
BA_ "VFrameFormat" BO_ 792 14;
BA_ "CANFD_BRS" BO_ 792 1;
BA_ "GenMsgCycleTime" BO_ 792 100;
BA_ "GenMsgCycleTimeFast" BO_ 792 0;
BA_ "GenMsgSendType" BO_ 792 0;
BA_ "VFrameFormat" BO_ 792 14;
BA_ "CANFD_BRS" BO_ 792 1;
BA_ "GenMsgCycleTime" BO_ 792 100;
BA_ "GenMsgCycleTimeFast" BO_ 792 0;
BA_ "GenMsgSendType" BO_ 792 0;
BA_ "VFrameFormat" BO_ 792 14;
BA_ "CANFD_BRS" BO_ 792 1;
BA_ "GenMsgCycleTime" BO_ 860 100;
BA_ "GenMsgCycleTimeFast" BO_ 860 0;
BA_ "GenMsgSendType" BO_ 860 0;
BA_ "VFrameFormat" BO_ 860 14;
BA_ "CANFD_BRS" BO_ 860 1;
BA_ "GenMsgCycleTime" BO_ 860 100;
BA_ "GenMsgCycleTimeFast" BO_ 860 0;
BA_ "GenMsgSendType" BO_ 860 0;
BA_ "VFrameFormat" BO_ 860 14;
BA_ "CANFD_BRS" BO_ 860 1;
BA_ "GenMsgCycleTime" BO_ 860 100;
BA_ "GenMsgCycleTimeFast" BO_ 860 0;
BA_ "GenMsgSendType" BO_ 860 0;
BA_ "VFrameFormat" BO_ 860 14;
BA_ "CANFD_BRS" BO_ 860 1;
BA_ "GenMsgCycleTime" BO_ 860 100;
BA_ "GenMsgCycleTimeFast" BO_ 860 0;
BA_ "GenMsgSendType" BO_ 860 0;
BA_ "VFrameFormat" BO_ 860 14;
BA_ "CANFD_BRS" BO_ 860 1;
BA_ "GenMsgCycleTime" BO_ 860 100;
BA_ "GenMsgCycleTimeFast" BO_ 860 0;
BA_ "GenMsgSendType" BO_ 860 0;
BA_ "VFrameFormat" BO_ 860 14;
BA_ "CANFD_BRS" BO_ 860 1;
BA_ "GenMsgCycleTime" BO_ 860 100;
BA_ "GenMsgCycleTimeFast" BO_ 860 0;
BA_ "GenMsgSendType" BO_ 860 0;
BA_ "VFrameFormat" BO_ 860 14;
BA_ "CANFD_BRS" BO_ 860 1;
BA_ "GenMsgCycleTime" BO_ 860 100;
BA_ "GenMsgCycleTimeFast" BO_ 860 0;
BA_ "GenMsgSendType" BO_ 860 0;
BA_ "VFrameFormat" BO_ 860 14;
BA_ "CANFD_BRS" BO_ 860 1;
BA_ "GenMsgCycleTime" BO_ 860 100;
BA_ "GenMsgCycleTimeFast" BO_ 860 0;
BA_ "GenMsgSendType" BO_ 860 0;
BA_ "VFrameFormat" BO_ 860 14;
BA_ "CANFD_BRS" BO_ 860 1;
BA_ "GenMsgCycleTime" BO_ 860 100;
BA_ "GenMsgCycleTimeFast" BO_ 860 0;
BA_ "GenMsgSendType" BO_ 860 0;
BA_ "VFrameFormat" BO_ 860 14;
BA_ "CANFD_BRS" BO_ 860 1;
BA_ "GenMsgCycleTime" BO_ 860 100;
BA_ "GenMsgCycleTimeFast" BO_ 860 0;
BA_ "GenMsgSendType" BO_ 860 0;
BA_ "VFrameFormat" BO_ 860 14;
BA_ "CANFD_BRS" BO_ 860 1;
BA_ "GenMsgCycleTime" BO_ 860 100;
BA_ "GenMsgCycleTimeFast" BO_ 860 0;
BA_ "GenMsgSendType" BO_ 860 0;
BA_ "VFrameFormat" BO_ 860 14;
BA_ "CANFD_BRS" BO_ 860 1;
BA_ "GenMsgCycleTime" BO_ 860 100;
BA_ "GenMsgCycleTimeFast" BO_ 860 0;
BA_ "GenMsgSendType" BO_ 860 0;
BA_ "VFrameFormat" BO_ 860 14;
BA_ "CANFD_BRS" BO_ 860 1;
BA_ "GenMsgCycleTime" BO_ 860 100;
BA_ "GenMsgCycleTimeFast" BO_ 860 0;
BA_ "GenMsgSendType" BO_ 860 0;
BA_ "VFrameFormat" BO_ 860 14;
BA_ "CANFD_BRS" BO_ 860 1;
BA_ "GenMsgCycleTime" BO_ 860 100;
BA_ "GenMsgCycleTimeFast" BO_ 860 0;
BA_ "GenMsgSendType" BO_ 860 0;
BA_ "VFrameFormat" BO_ 860 14;
BA_ "CANFD_BRS" BO_ 860 1;
BA_ "GenMsgCycleTime" BO_ 860 100;
BA_ "GenMsgCycleTimeFast" BO_ 860 0;
BA_ "GenMsgSendType" BO_ 860 0;
BA_ "VFrameFormat" BO_ 860 14;
BA_ "CANFD_BRS" BO_ 860 1;
BA_ "GenMsgCycleTime" BO_ 860 100;
BA_ "GenMsgCycleTimeFast" BO_ 860 0;
BA_ "GenMsgSendType" BO_ 860 0;
BA_ "VFrameFormat" BO_ 860 14;
BA_ "CANFD_BRS" BO_ 860 1;
BA_ "GenMsgCycleTime" BO_ 860 100;
BA_ "GenMsgCycleTimeFast" BO_ 860 0;
BA_ "GenMsgSendType" BO_ 860 0;
BA_ "VFrameFormat" BO_ 860 14;
BA_ "CANFD_BRS" BO_ 860 1;
BA_ "EventCommandSignal" SG_ 549 ADC_12_CRC 0;
BA_ "GatewayedSignals" SG_ 549 ADC_12_CRC 0;
BA_ "GenSigInactiveValue" SG_ 549 ADC_12_CRC 0;
BA_ "GenSigInvalidValue" SG_ 549 ADC_12_CRC 0;
BA_ "GenSigSendType" SG_ 549 ADC_12_CRC 1;
BA_ "GenSigStartValue" SG_ 549 ADC_12_CRC 0;
BA_ "GenSigTimeoutValue" SG_ 549 ADC_12_CRC 0;
BA_ "Remark" SG_ 549 ADC_12_CRC "";
BA_ "EventCommandSignal" SG_ 549 ADC_12_Counter 0;
BA_ "GatewayedSignals" SG_ 549 ADC_12_Counter 0;
BA_ "GenSigInactiveValue" SG_ 549 ADC_12_Counter 0;
BA_ "GenSigInvalidValue" SG_ 549 ADC_12_Counter 0;
BA_ "GenSigSendType" SG_ 549 ADC_12_Counter 1;
BA_ "GenSigStartValue" SG_ 549 ADC_12_Counter 0;
BA_ "GenSigTimeoutValue" SG_ 549 ADC_12_Counter 0;
BA_ "Remark" SG_ 549 ADC_12_Counter "";
BA_ "EventCommandSignal" SG_ 549 ADC_APAst 0;
BA_ "GatewayedSignals" SG_ 549 ADC_APAst 0;
BA_ "GenSigInactiveValue" SG_ 549 ADC_APAst 0;
BA_ "GenSigInvalidValue" SG_ 549 ADC_APAst 0;
BA_ "GenSigSendType" SG_ 549 ADC_APAst 1;
BA_ "GenSigStartValue" SG_ 549 ADC_APAst 0;
BA_ "GenSigTimeoutValue" SG_ 549 ADC_APAst 0;
BA_ "Remark" SG_ 549 ADC_APAst "";
BA_ "EventCommandSignal" SG_ 549 ADC_AVPst 0;
BA_ "GatewayedSignals" SG_ 549 ADC_AVPst 0;
BA_ "GenSigInactiveValue" SG_ 549 ADC_AVPst 0;
BA_ "GenSigInvalidValue" SG_ 549 ADC_AVPst 0;
BA_ "GenSigSendType" SG_ 549 ADC_AVPst 1;
BA_ "GenSigStartValue" SG_ 549 ADC_AVPst 0;
BA_ "GenSigTimeoutValue" SG_ 549 ADC_AVPst 0;
BA_ "Remark" SG_ 549 ADC_AVPst "";
BA_ "EventCommandSignal" SG_ 549 ADC_PAAFuncSt 0;
BA_ "GatewayedSignals" SG_ 549 ADC_PAAFuncSt 0;
BA_ "GenSigInactiveValue" SG_ 549 ADC_PAAFuncSt 0;
BA_ "GenSigInvalidValue" SG_ 549 ADC_PAAFuncSt 0;
BA_ "GenSigSendType" SG_ 549 ADC_PAAFuncSt 1;
BA_ "GenSigStartValue" SG_ 549 ADC_PAAFuncSt 0;
BA_ "GenSigTimeoutValue" SG_ 549 ADC_PAAFuncSt 0;
BA_ "Remark" SG_ 549 ADC_PAAFuncSt "";
BA_ "EventCommandSignal" SG_ 549 ADC_PAAVoiceReminder 0;
BA_ "GatewayedSignals" SG_ 549 ADC_PAAVoiceReminder 0;
BA_ "GenSigInactiveValue" SG_ 549 ADC_PAAVoiceReminder 0;
BA_ "GenSigInvalidValue" SG_ 549 ADC_PAAVoiceReminder 0;
BA_ "GenSigSendType" SG_ 549 ADC_PAAVoiceReminder 1;
BA_ "GenSigStartValue" SG_ 549 ADC_PAAVoiceReminder 0;
BA_ "GenSigTimeoutValue" SG_ 549 ADC_PAAVoiceReminder 0;
BA_ "Remark" SG_ 549 ADC_PAAVoiceReminder "";
BA_ "EventCommandSignal" SG_ 549 ADC_PAAVRSwitchFailSt 0;
BA_ "GatewayedSignals" SG_ 549 ADC_PAAVRSwitchFailSt 0;
BA_ "GenSigInactiveValue" SG_ 549 ADC_PAAVRSwitchFailSt 0;
BA_ "GenSigInvalidValue" SG_ 549 ADC_PAAVRSwitchFailSt 0;
BA_ "GenSigSendType" SG_ 549 ADC_PAAVRSwitchFailSt 1;
BA_ "GenSigStartValue" SG_ 549 ADC_PAAVRSwitchFailSt 0;
BA_ "GenSigTimeoutValue" SG_ 549 ADC_PAAVRSwitchFailSt 0;
BA_ "Remark" SG_ 549 ADC_PAAVRSwitchFailSt "";
BA_ "EventCommandSignal" SG_ 549 ADC_APKDisplayReq 0;
BA_ "GatewayedSignals" SG_ 549 ADC_APKDisplayReq 0;
BA_ "GenSigInactiveValue" SG_ 549 ADC_APKDisplayReq 0;
BA_ "GenSigInvalidValue" SG_ 549 ADC_APKDisplayReq 0;
BA_ "GenSigSendType" SG_ 549 ADC_APKDisplayReq 1;
BA_ "GenSigStartValue" SG_ 549 ADC_APKDisplayReq 0;
BA_ "GenSigTimeoutValue" SG_ 549 ADC_APKDisplayReq 0;
BA_ "Remark" SG_ 549 ADC_APKDisplayReq "";
BA_ "EventCommandSignal" SG_ 549 ADC_APAActFuncInd 0;
BA_ "GatewayedSignals" SG_ 549 ADC_APAActFuncInd 0;
BA_ "GenSigInactiveValue" SG_ 549 ADC_APAActFuncInd 0;
BA_ "GenSigInvalidValue" SG_ 549 ADC_APAActFuncInd 0;
BA_ "GenSigSendType" SG_ 549 ADC_APAActFuncInd 1;
BA_ "GenSigStartValue" SG_ 549 ADC_APAActFuncInd 0;
BA_ "GenSigTimeoutValue" SG_ 549 ADC_APAActFuncInd 0;
BA_ "Remark" SG_ 549 ADC_APAActFuncInd "";
BA_ "EventCommandSignal" SG_ 549 ADC_APABackParkDisplayReq 0;
BA_ "GatewayedSignals" SG_ 549 ADC_APABackParkDisplayReq 0;
BA_ "GenSigInactiveValue" SG_ 549 ADC_APABackParkDisplayReq 0;
BA_ "GenSigInvalidValue" SG_ 549 ADC_APABackParkDisplayReq 0;
BA_ "GenSigSendType" SG_ 549 ADC_APABackParkDisplayReq 1;
BA_ "GenSigStartValue" SG_ 549 ADC_APABackParkDisplayReq 0;
BA_ "GenSigTimeoutValue" SG_ 549 ADC_APABackParkDisplayReq 0;
BA_ "Remark" SG_ 549 ADC_APABackParkDisplayReq "";
BA_ "EventCommandSignal" SG_ 549 ADC_VCU_Gearshiftprompt 0;
BA_ "GatewayedSignals" SG_ 549 ADC_VCU_Gearshiftprompt 0;
BA_ "GenSigInactiveValue" SG_ 549 ADC_VCU_Gearshiftprompt 0;
BA_ "GenSigInvalidValue" SG_ 549 ADC_VCU_Gearshiftprompt 0;
BA_ "GenSigSendType" SG_ 549 ADC_VCU_Gearshiftprompt 1;
BA_ "GenSigStartValue" SG_ 549 ADC_VCU_Gearshiftprompt 0;
BA_ "GenSigTimeoutValue" SG_ 549 ADC_VCU_Gearshiftprompt 0;
BA_ "Remark" SG_ 549 ADC_VCU_Gearshiftprompt "";
BA_ "EventCommandSignal" SG_ 549 ADC_AVPActFuncind 0;
BA_ "GatewayedSignals" SG_ 549 ADC_AVPActFuncind 0;
BA_ "GenSigInactiveValue" SG_ 549 ADC_AVPActFuncind 0;
BA_ "GenSigInvalidValue" SG_ 549 ADC_AVPActFuncind 0;
BA_ "GenSigSendType" SG_ 549 ADC_AVPActFuncind 1;
BA_ "GenSigStartValue" SG_ 549 ADC_AVPActFuncind 0;
BA_ "GenSigTimeoutValue" SG_ 549 ADC_AVPActFuncind 0;
BA_ "Remark" SG_ 549 ADC_AVPActFuncind "";
BA_ "EventCommandSignal" SG_ 549 ADC_APAMessagePushSt 0;
BA_ "GatewayedSignals" SG_ 549 ADC_APAMessagePushSt 0;
BA_ "GenSigInactiveValue" SG_ 549 ADC_APAMessagePushSt 0;
BA_ "GenSigInvalidValue" SG_ 549 ADC_APAMessagePushSt 0;
BA_ "GenSigSendType" SG_ 549 ADC_APAMessagePushSt 1;
BA_ "GenSigStartValue" SG_ 549 ADC_APAMessagePushSt 0;
BA_ "GenSigTimeoutValue" SG_ 549 ADC_APAMessagePushSt 0;
BA_ "Remark" SG_ 549 ADC_APAMessagePushSt "";
BA_ "EventCommandSignal" SG_ 549 ADC_PedWarnToneCtrl 0;
BA_ "GatewayedSignals" SG_ 549 ADC_PedWarnToneCtrl 0;
BA_ "GenSigInactiveValue" SG_ 549 ADC_PedWarnToneCtrl 0;
BA_ "GenSigInvalidValue" SG_ 549 ADC_PedWarnToneCtrl 0;
BA_ "GenSigSendType" SG_ 549 ADC_PedWarnToneCtrl 1;
BA_ "GenSigStartValue" SG_ 549 ADC_PedWarnToneCtrl 0;
BA_ "GenSigTimeoutValue" SG_ 549 ADC_PedWarnToneCtrl 0;
BA_ "Remark" SG_ 549 ADC_PedWarnToneCtrl "";
BA_ "EventCommandSignal" SG_ 549 ADC_HPAMessagePushSt 0;
BA_ "GatewayedSignals" SG_ 549 ADC_HPAMessagePushSt 0;
BA_ "GenSigInactiveValue" SG_ 549 ADC_HPAMessagePushSt 0;
BA_ "GenSigInvalidValue" SG_ 549 ADC_HPAMessagePushSt 0;
BA_ "GenSigSendType" SG_ 549 ADC_HPAMessagePushSt 1;
BA_ "GenSigStartValue" SG_ 549 ADC_HPAMessagePushSt 0;
BA_ "GenSigTimeoutValue" SG_ 549 ADC_HPAMessagePushSt 0;
BA_ "Remark" SG_ 549 ADC_HPAMessagePushSt "";
BA_ "EventCommandSignal" SG_ 549 ADC_AVPMessagePushSt 0;
BA_ "GatewayedSignals" SG_ 549 ADC_AVPMessagePushSt 0;
BA_ "GenSigInactiveValue" SG_ 549 ADC_AVPMessagePushSt 0;
BA_ "GenSigInvalidValue" SG_ 549 ADC_AVPMessagePushSt 0;
BA_ "GenSigSendType" SG_ 549 ADC_AVPMessagePushSt 1;
BA_ "GenSigStartValue" SG_ 549 ADC_AVPMessagePushSt 0;
BA_ "GenSigTimeoutValue" SG_ 549 ADC_AVPMessagePushSt 0;
BA_ "Remark" SG_ 549 ADC_AVPMessagePushSt "";
BA_ "EventCommandSignal" SG_ 549 ADC_PAADrvInteraction 0;
BA_ "GatewayedSignals" SG_ 549 ADC_PAADrvInteraction 0;
BA_ "GenSigInactiveValue" SG_ 549 ADC_PAADrvInteraction 0;
BA_ "GenSigInvalidValue" SG_ 549 ADC_PAADrvInteraction 0;
BA_ "GenSigSendType" SG_ 549 ADC_PAADrvInteraction 1;
BA_ "GenSigStartValue" SG_ 549 ADC_PAADrvInteraction 0;
BA_ "GenSigTimeoutValue" SG_ 549 ADC_PAADrvInteraction 0;
BA_ "Remark" SG_ 549 ADC_PAADrvInteraction "";
BA_ "EventCommandSignal" SG_ 549 ADC_PAAToNDAReq 0;
BA_ "GatewayedSignals" SG_ 549 ADC_PAAToNDAReq 0;
BA_ "GenSigInactiveValue" SG_ 549 ADC_PAAToNDAReq 0;
BA_ "GenSigInvalidValue" SG_ 549 ADC_PAAToNDAReq 0;
BA_ "GenSigSendType" SG_ 549 ADC_PAAToNDAReq 1;
BA_ "GenSigStartValue" SG_ 549 ADC_PAAToNDAReq 0;
BA_ "GenSigTimeoutValue" SG_ 549 ADC_PAAToNDAReq 0;
BA_ "Remark" SG_ 549 ADC_PAAToNDAReq "";
BA_ "EventCommandSignal" SG_ 549 ADC_PAARemoteParkingMode 0;
BA_ "GatewayedSignals" SG_ 549 ADC_PAARemoteParkingMode 0;
BA_ "GenSigInactiveValue" SG_ 549 ADC_PAARemoteParkingMode 0;
BA_ "GenSigInvalidValue" SG_ 549 ADC_PAARemoteParkingMode 0;
BA_ "GenSigSendType" SG_ 549 ADC_PAARemoteParkingMode 1;
BA_ "GenSigStartValue" SG_ 549 ADC_PAARemoteParkingMode 0;
BA_ "GenSigTimeoutValue" SG_ 549 ADC_PAARemoteParkingMode 0;
BA_ "Remark" SG_ 549 ADC_PAARemoteParkingMode "";
BA_ "EventCommandSignal" SG_ 549 ADC_PAARemoteParkingEnable 0;
BA_ "GatewayedSignals" SG_ 549 ADC_PAARemoteParkingEnable 0;
BA_ "GenSigInactiveValue" SG_ 549 ADC_PAARemoteParkingEnable 0;
BA_ "GenSigInvalidValue" SG_ 549 ADC_PAARemoteParkingEnable 0;
BA_ "GenSigSendType" SG_ 549 ADC_PAARemoteParkingEnable 1;
BA_ "GenSigStartValue" SG_ 549 ADC_PAARemoteParkingEnable 0;
BA_ "GenSigTimeoutValue" SG_ 549 ADC_PAARemoteParkingEnable 0;
BA_ "Remark" SG_ 549 ADC_PAARemoteParkingEnable "";
BA_ "EventCommandSignal" SG_ 549 ADC_LocalToBeDRVReq 0;
BA_ "GatewayedSignals" SG_ 549 ADC_LocalToBeDRVReq 0;
BA_ "GenSigInactiveValue" SG_ 549 ADC_LocalToBeDRVReq 0;
BA_ "GenSigInvalidValue" SG_ 549 ADC_LocalToBeDRVReq 0;
BA_ "GenSigSendType" SG_ 549 ADC_LocalToBeDRVReq 1;
BA_ "GenSigStartValue" SG_ 549 ADC_LocalToBeDRVReq 0;
BA_ "GenSigTimeoutValue" SG_ 549 ADC_LocalToBeDRVReq 0;
BA_ "Remark" SG_ 549 ADC_LocalToBeDRVReq "";
BA_ "EventCommandSignal" SG_ 549 ADC_UsageModeStAscendReq 0;
BA_ "GatewayedSignals" SG_ 549 ADC_UsageModeStAscendReq 0;
BA_ "GenSigInactiveValue" SG_ 549 ADC_UsageModeStAscendReq 0;
BA_ "GenSigInvalidValue" SG_ 549 ADC_UsageModeStAscendReq 0;
BA_ "GenSigSendType" SG_ 549 ADC_UsageModeStAscendReq 1;
BA_ "GenSigStartValue" SG_ 549 ADC_UsageModeStAscendReq 0;
BA_ "GenSigTimeoutValue" SG_ 549 ADC_UsageModeStAscendReq 0;
BA_ "Remark" SG_ 549 ADC_UsageModeStAscendReq "";
BA_ "EventCommandSignal" SG_ 549 ADC_UsageModeStDescendReq 0;
BA_ "GatewayedSignals" SG_ 549 ADC_UsageModeStDescendReq 0;
BA_ "GenSigInactiveValue" SG_ 549 ADC_UsageModeStDescendReq 0;
BA_ "GenSigInvalidValue" SG_ 549 ADC_UsageModeStDescendReq 0;
BA_ "GenSigSendType" SG_ 549 ADC_UsageModeStDescendReq 1;
BA_ "GenSigStartValue" SG_ 549 ADC_UsageModeStDescendReq 0;
BA_ "GenSigTimeoutValue" SG_ 549 ADC_UsageModeStDescendReq 0;
BA_ "Remark" SG_ 549 ADC_UsageModeStDescendReq "";
BA_ "EventCommandSignal" SG_ 549 ADC_PAAIGCInhibitSt 0;
BA_ "GatewayedSignals" SG_ 549 ADC_PAAIGCInhibitSt 0;
BA_ "GenSigInactiveValue" SG_ 549 ADC_PAAIGCInhibitSt 0;
BA_ "GenSigInvalidValue" SG_ 549 ADC_PAAIGCInhibitSt 0;
BA_ "GenSigSendType" SG_ 549 ADC_PAAIGCInhibitSt 1;
BA_ "GenSigStartValue" SG_ 549 ADC_PAAIGCInhibitSt 0;
BA_ "GenSigTimeoutValue" SG_ 549 ADC_PAAIGCInhibitSt 0;
BA_ "Remark" SG_ 549 ADC_PAAIGCInhibitSt "";
BA_ "EventCommandSignal" SG_ 549 ADC_UsageModeStHold 0;
BA_ "GatewayedSignals" SG_ 549 ADC_UsageModeStHold 0;
BA_ "GenSigInactiveValue" SG_ 549 ADC_UsageModeStHold 0;
BA_ "GenSigInvalidValue" SG_ 549 ADC_UsageModeStHold 0;
BA_ "GenSigSendType" SG_ 549 ADC_UsageModeStHold 1;
BA_ "GenSigStartValue" SG_ 549 ADC_UsageModeStHold 0;
BA_ "GenSigTimeoutValue" SG_ 549 ADC_UsageModeStHold 0;
BA_ "Remark" SG_ 549 ADC_UsageModeStHold "";
BA_ "EventCommandSignal" SG_ 549 ADC_PAARespondMode 0;
BA_ "GatewayedSignals" SG_ 549 ADC_PAARespondMode 0;
BA_ "GenSigInactiveValue" SG_ 549 ADC_PAARespondMode 0;
BA_ "GenSigInvalidValue" SG_ 549 ADC_PAARespondMode 0;
BA_ "GenSigSendType" SG_ 549 ADC_PAARespondMode 1;
BA_ "GenSigStartValue" SG_ 549 ADC_PAARespondMode 0;
BA_ "GenSigTimeoutValue" SG_ 549 ADC_PAARespondMode 0;
BA_ "Remark" SG_ 549 ADC_PAARespondMode "";
BA_ "EventCommandSignal" SG_ 549 ADC_PAAEDKFunInhibitReq 0;
BA_ "GatewayedSignals" SG_ 549 ADC_PAAEDKFunInhibitReq 0;
BA_ "GenSigInactiveValue" SG_ 549 ADC_PAAEDKFunInhibitReq 0;
BA_ "GenSigInvalidValue" SG_ 549 ADC_PAAEDKFunInhibitReq 0;
BA_ "GenSigSendType" SG_ 549 ADC_PAAEDKFunInhibitReq 1;
BA_ "GenSigStartValue" SG_ 549 ADC_PAAEDKFunInhibitReq 0;
BA_ "GenSigTimeoutValue" SG_ 549 ADC_PAAEDKFunInhibitReq 0;
BA_ "Remark" SG_ 549 ADC_PAAEDKFunInhibitReq "";
BA_ "EventCommandSignal" SG_ 549 ADC_RAEBWorkSts 0;
BA_ "GatewayedSignals" SG_ 549 ADC_RAEBWorkSts 0;
BA_ "GenSigInactiveValue" SG_ 549 ADC_RAEBWorkSts 0;
BA_ "GenSigInvalidValue" SG_ 549 ADC_RAEBWorkSts 0;
BA_ "GenSigSendType" SG_ 549 ADC_RAEBWorkSts 1;
BA_ "GenSigStartValue" SG_ 549 ADC_RAEBWorkSts 0;
BA_ "GenSigTimeoutValue" SG_ 549 ADC_RAEBWorkSts 0;
BA_ "Remark" SG_ 549 ADC_RAEBWorkSts "";
BA_ "EventCommandSignal" SG_ 549 ADC_DriverPresentSt 0;
BA_ "GatewayedSignals" SG_ 549 ADC_DriverPresentSt 0;
BA_ "GenSigInactiveValue" SG_ 549 ADC_DriverPresentSt 0;
BA_ "GenSigInvalidValue" SG_ 549 ADC_DriverPresentSt 0;
BA_ "GenSigSendType" SG_ 549 ADC_DriverPresentSt 1;
BA_ "GenSigStartValue" SG_ 549 ADC_DriverPresentSt 0;
BA_ "GenSigTimeoutValue" SG_ 549 ADC_DriverPresentSt 0;
BA_ "Remark" SG_ 549 ADC_DriverPresentSt "";
BA_ "EventCommandSignal" SG_ 549 ADC_UsageModeStHoldVD 0;
BA_ "GatewayedSignals" SG_ 549 ADC_UsageModeStHoldVD 0;
BA_ "GenSigInactiveValue" SG_ 549 ADC_UsageModeStHoldVD 0;
BA_ "GenSigInvalidValue" SG_ 549 ADC_UsageModeStHoldVD 0;
BA_ "GenSigSendType" SG_ 549 ADC_UsageModeStHoldVD 1;
BA_ "GenSigStartValue" SG_ 549 ADC_UsageModeStHoldVD 0;
BA_ "GenSigTimeoutValue" SG_ 549 ADC_UsageModeStHoldVD 0;
BA_ "Remark" SG_ 549 ADC_UsageModeStHoldVD "";
BA_ "EventCommandSignal" SG_ 549 ADC_RAEBEmgyBrkReq 0;
BA_ "GatewayedSignals" SG_ 549 ADC_RAEBEmgyBrkReq 0;
BA_ "GenSigInactiveValue" SG_ 549 ADC_RAEBEmgyBrkReq 0;
BA_ "GenSigInvalidValue" SG_ 549 ADC_RAEBEmgyBrkReq 0;
BA_ "GenSigSendType" SG_ 549 ADC_RAEBEmgyBrkReq 1;
BA_ "GenSigStartValue" SG_ 549 ADC_RAEBEmgyBrkReq 0;
BA_ "GenSigTimeoutValue" SG_ 549 ADC_RAEBEmgyBrkReq 0;
BA_ "Remark" SG_ 549 ADC_RAEBEmgyBrkReq "";
BA_ "EventCommandSignal" SG_ 549 ADC_RAEBTarAccel 0;
BA_ "GatewayedSignals" SG_ 549 ADC_RAEBTarAccel 0;
BA_ "GenSigInactiveValue" SG_ 549 ADC_RAEBTarAccel 0;
BA_ "GenSigInvalidValue" SG_ 549 ADC_RAEBTarAccel 0;
BA_ "GenSigSendType" SG_ 549 ADC_RAEBTarAccel 1;
BA_ "GenSigStartValue" SG_ 549 ADC_RAEBTarAccel 0;
BA_ "GenSigTimeoutValue" SG_ 549 ADC_RAEBTarAccel 0;
BA_ "Remark" SG_ 549 ADC_RAEBTarAccel "";
BA_ "EventCommandSignal" SG_ 549 ADC_PAADrvReq 0;
BA_ "GatewayedSignals" SG_ 549 ADC_PAADrvReq 0;
BA_ "GenSigInactiveValue" SG_ 549 ADC_PAADrvReq 0;
BA_ "GenSigInvalidValue" SG_ 549 ADC_PAADrvReq 0;
BA_ "GenSigSendType" SG_ 549 ADC_PAADrvReq 1;
BA_ "GenSigStartValue" SG_ 549 ADC_PAADrvReq 0;
BA_ "GenSigTimeoutValue" SG_ 549 ADC_PAADrvReq 0;
BA_ "Remark" SG_ 549 ADC_PAADrvReq "";
BA_ "EventCommandSignal" SG_ 549 ADC_PAAQuitInd 0;
BA_ "GatewayedSignals" SG_ 549 ADC_PAAQuitInd 0;
BA_ "GenSigInactiveValue" SG_ 549 ADC_PAAQuitInd 0;
BA_ "GenSigInvalidValue" SG_ 549 ADC_PAAQuitInd 0;
BA_ "GenSigSendType" SG_ 549 ADC_PAAQuitInd 1;
BA_ "GenSigStartValue" SG_ 549 ADC_PAAQuitInd 0;
BA_ "GenSigTimeoutValue" SG_ 549 ADC_PAAQuitInd 0;
BA_ "Remark" SG_ 549 ADC_PAAQuitInd "";
BA_ "EventCommandSignal" SG_ 549 ADC_PAARecInd 0;
BA_ "GatewayedSignals" SG_ 549 ADC_PAARecInd 0;
BA_ "GenSigInactiveValue" SG_ 549 ADC_PAARecInd 0;
BA_ "GenSigInvalidValue" SG_ 549 ADC_PAARecInd 0;
BA_ "GenSigSendType" SG_ 549 ADC_PAARecInd 1;
BA_ "GenSigStartValue" SG_ 549 ADC_PAARecInd 0;
BA_ "GenSigTimeoutValue" SG_ 549 ADC_PAARecInd 0;
BA_ "Remark" SG_ 549 ADC_PAARecInd "";
BA_ "EventCommandSignal" SG_ 549 ADC_RA_RemainDist 0;
BA_ "GatewayedSignals" SG_ 549 ADC_RA_RemainDist 0;
BA_ "GenSigInactiveValue" SG_ 549 ADC_RA_RemainDist 0;
BA_ "GenSigInvalidValue" SG_ 549 ADC_RA_RemainDist 0;
BA_ "GenSigSendType" SG_ 549 ADC_RA_RemainDist 1;
BA_ "GenSigStartValue" SG_ 549 ADC_RA_RemainDist 0;
BA_ "GenSigTimeoutValue" SG_ 549 ADC_RA_RemainDist 0;
BA_ "Remark" SG_ 549 ADC_RA_RemainDist "";
BA_ "EventCommandSignal" SG_ 549 ADC_RAButtonPress 0;
BA_ "GatewayedSignals" SG_ 549 ADC_RAButtonPress 0;
BA_ "GenSigInactiveValue" SG_ 549 ADC_RAButtonPress 0;
BA_ "GenSigInvalidValue" SG_ 549 ADC_RAButtonPress 0;
BA_ "GenSigSendType" SG_ 549 ADC_RAButtonPress 1;
BA_ "GenSigStartValue" SG_ 549 ADC_RAButtonPress 0;
BA_ "GenSigTimeoutValue" SG_ 549 ADC_RAButtonPress 0;
BA_ "Remark" SG_ 549 ADC_RAButtonPress "";
BA_ "EventCommandSignal" SG_ 549 ADC_Rast 0;
BA_ "GatewayedSignals" SG_ 549 ADC_Rast 0;
BA_ "GenSigInactiveValue" SG_ 549 ADC_Rast 0;
BA_ "GenSigInvalidValue" SG_ 549 ADC_Rast 0;
BA_ "GenSigSendType" SG_ 549 ADC_Rast 1;
BA_ "GenSigStartValue" SG_ 549 ADC_Rast 0;
BA_ "GenSigTimeoutValue" SG_ 549 ADC_Rast 0;
BA_ "Remark" SG_ 549 ADC_Rast "";
BA_ "EventCommandSignal" SG_ 549 ADC_SBMAuthst 0;
BA_ "GatewayedSignals" SG_ 549 ADC_SBMAuthst 0;
BA_ "GenSigInactiveValue" SG_ 549 ADC_SBMAuthst 0;
BA_ "GenSigInvalidValue" SG_ 549 ADC_SBMAuthst 0;
BA_ "GenSigSendType" SG_ 549 ADC_SBMAuthst 1;
BA_ "GenSigStartValue" SG_ 549 ADC_SBMAuthst 0;
BA_ "GenSigTimeoutValue" SG_ 549 ADC_SBMAuthst 0;
BA_ "Remark" SG_ 549 ADC_SBMAuthst "";
BA_ "EventCommandSignal" SG_ 549 ADC_AuthPassSt 0;
BA_ "GatewayedSignals" SG_ 549 ADC_AuthPassSt 0;
BA_ "GenSigInactiveValue" SG_ 549 ADC_AuthPassSt 0;
BA_ "GenSigInvalidValue" SG_ 549 ADC_AuthPassSt 0;
BA_ "GenSigSendType" SG_ 549 ADC_AuthPassSt 1;
BA_ "GenSigStartValue" SG_ 549 ADC_AuthPassSt 0;
BA_ "GenSigTimeoutValue" SG_ 549 ADC_AuthPassSt 0;
BA_ "Remark" SG_ 549 ADC_AuthPassSt "";
BA_ "EventCommandSignal" SG_ 549 ADC_RPADirectionSel 0;
BA_ "GatewayedSignals" SG_ 549 ADC_RPADirectionSel 0;
BA_ "GenSigInactiveValue" SG_ 549 ADC_RPADirectionSel 0;
BA_ "GenSigInvalidValue" SG_ 549 ADC_RPADirectionSel 0;
BA_ "GenSigSendType" SG_ 549 ADC_RPADirectionSel 1;
BA_ "GenSigStartValue" SG_ 549 ADC_RPADirectionSel 0;
BA_ "GenSigTimeoutValue" SG_ 549 ADC_RPADirectionSel 0;
BA_ "Remark" SG_ 549 ADC_RPADirectionSel "";
BA_ "EventCommandSignal" SG_ 549 ADC_VehPoscoord 0;
BA_ "GatewayedSignals" SG_ 549 ADC_VehPoscoord 0;
BA_ "GenSigInactiveValue" SG_ 549 ADC_VehPoscoord 0;
BA_ "GenSigInvalidValue" SG_ 549 ADC_VehPoscoord 0;
BA_ "GenSigSendType" SG_ 549 ADC_VehPoscoord 1;
BA_ "GenSigStartValue" SG_ 549 ADC_VehPoscoord 0;
BA_ "GenSigTimeoutValue" SG_ 549 ADC_VehPoscoord 0;
BA_ "Remark" SG_ 549 ADC_VehPoscoord "";
BA_ "EventCommandSignal" SG_ 549 ADC_VehDynamicPosX 0;
BA_ "GatewayedSignals" SG_ 549 ADC_VehDynamicPosX 0;
BA_ "GenSigInactiveValue" SG_ 549 ADC_VehDynamicPosX 0;
BA_ "GenSigInvalidValue" SG_ 549 ADC_VehDynamicPosX 0;
BA_ "GenSigSendType" SG_ 549 ADC_VehDynamicPosX 1;
BA_ "GenSigStartValue" SG_ 549 ADC_VehDynamicPosX 0;
BA_ "GenSigTimeoutValue" SG_ 549 ADC_VehDynamicPosX 0;
BA_ "Remark" SG_ 549 ADC_VehDynamicPosX "";
BA_ "EventCommandSignal" SG_ 549 ADC_VehDynamicPosY 0;
BA_ "GatewayedSignals" SG_ 549 ADC_VehDynamicPosY 0;
BA_ "GenSigInactiveValue" SG_ 549 ADC_VehDynamicPosY 0;
BA_ "GenSigInvalidValue" SG_ 549 ADC_VehDynamicPosY 0;
BA_ "GenSigSendType" SG_ 549 ADC_VehDynamicPosY 1;
BA_ "GenSigStartValue" SG_ 549 ADC_VehDynamicPosY 0;
BA_ "GenSigTimeoutValue" SG_ 549 ADC_VehDynamicPosY 0;
BA_ "Remark" SG_ 549 ADC_VehDynamicPosY "";
BA_ "EventCommandSignal" SG_ 549 ADC_VehCurv 0;
BA_ "GatewayedSignals" SG_ 549 ADC_VehCurv 0;
BA_ "GenSigInactiveValue" SG_ 549 ADC_VehCurv 0;
BA_ "GenSigInvalidValue" SG_ 549 ADC_VehCurv 0;
BA_ "GenSigSendType" SG_ 549 ADC_VehCurv 1;
BA_ "GenSigStartValue" SG_ 549 ADC_VehCurv 0;
BA_ "GenSigTimeoutValue" SG_ 549 ADC_VehCurv 0;
BA_ "Remark" SG_ 549 ADC_VehCurv "";
BA_ "EventCommandSignal" SG_ 549 ADC_SlotPosX 0;
BA_ "GatewayedSignals" SG_ 549 ADC_SlotPosX 0;
BA_ "GenSigInactiveValue" SG_ 549 ADC_SlotPosX 0;
BA_ "GenSigInvalidValue" SG_ 549 ADC_SlotPosX 0;
BA_ "GenSigSendType" SG_ 549 ADC_SlotPosX 1;
BA_ "GenSigStartValue" SG_ 549 ADC_SlotPosX 0;
BA_ "GenSigTimeoutValue" SG_ 549 ADC_SlotPosX 0;
BA_ "Remark" SG_ 549 ADC_SlotPosX "";
BA_ "EventCommandSignal" SG_ 549 ADC_SlotPosY 0;
BA_ "GatewayedSignals" SG_ 549 ADC_SlotPosY 0;
BA_ "GenSigInactiveValue" SG_ 549 ADC_SlotPosY 0;
BA_ "GenSigInvalidValue" SG_ 549 ADC_SlotPosY 0;
BA_ "GenSigSendType" SG_ 549 ADC_SlotPosY 1;
BA_ "GenSigStartValue" SG_ 549 ADC_SlotPosY 0;
BA_ "GenSigTimeoutValue" SG_ 549 ADC_SlotPosY 0;
BA_ "Remark" SG_ 549 ADC_SlotPosY "";
BA_ "EventCommandSignal" SG_ 549 ADC_HPAst 0;
BA_ "GatewayedSignals" SG_ 549 ADC_HPAst 0;
BA_ "GenSigInactiveValue" SG_ 549 ADC_HPAst 0;
BA_ "GenSigInvalidValue" SG_ 549 ADC_HPAst 0;
BA_ "GenSigSendType" SG_ 549 ADC_HPAst 1;
BA_ "GenSigStartValue" SG_ 549 ADC_HPAst 0;
BA_ "GenSigTimeoutValue" SG_ 549 ADC_HPAst 0;
BA_ "Remark" SG_ 549 ADC_HPAst "";
BA_ "EventCommandSignal" SG_ 549 ADC_SlotCurv 0;
BA_ "GatewayedSignals" SG_ 549 ADC_SlotCurv 0;
BA_ "GenSigInactiveValue" SG_ 549 ADC_SlotCurv 0;
BA_ "GenSigInvalidValue" SG_ 549 ADC_SlotCurv 0;
BA_ "GenSigSendType" SG_ 549 ADC_SlotCurv 1;
BA_ "GenSigStartValue" SG_ 549 ADC_SlotCurv 0;
BA_ "GenSigTimeoutValue" SG_ 549 ADC_SlotCurv 0;
BA_ "Remark" SG_ 549 ADC_SlotCurv "";
BA_ "EventCommandSignal" SG_ 549 ADC_parkInOutDirection 0;
BA_ "GatewayedSignals" SG_ 549 ADC_parkInOutDirection 0;
BA_ "GenSigInactiveValue" SG_ 549 ADC_parkInOutDirection 0;
BA_ "GenSigInvalidValue" SG_ 549 ADC_parkInOutDirection 0;
BA_ "GenSigSendType" SG_ 549 ADC_parkInOutDirection 1;
BA_ "GenSigStartValue" SG_ 549 ADC_parkInOutDirection 0;
BA_ "GenSigTimeoutValue" SG_ 549 ADC_parkInOutDirection 0;
BA_ "Remark" SG_ 549 ADC_parkInOutDirection "";
BA_ "EventCommandSignal" SG_ 549 ADC_RPAStMessagePush 0;
BA_ "GatewayedSignals" SG_ 549 ADC_RPAStMessagePush 0;
BA_ "GenSigInactiveValue" SG_ 549 ADC_RPAStMessagePush 0;
BA_ "GenSigInvalidValue" SG_ 549 ADC_RPAStMessagePush 0;
BA_ "GenSigSendType" SG_ 549 ADC_RPAStMessagePush 1;
BA_ "GenSigStartValue" SG_ 549 ADC_RPAStMessagePush 0;
BA_ "GenSigTimeoutValue" SG_ 549 ADC_RPAStMessagePush 0;
BA_ "Remark" SG_ 549 ADC_RPAStMessagePush "";
BA_ "EventCommandSignal" SG_ 549 ADC_RPAtype 0;
BA_ "GatewayedSignals" SG_ 549 ADC_RPAtype 0;
BA_ "GenSigInactiveValue" SG_ 549 ADC_RPAtype 0;
BA_ "GenSigInvalidValue" SG_ 549 ADC_RPAtype 0;
BA_ "GenSigSendType" SG_ 549 ADC_RPAtype 1;
BA_ "GenSigStartValue" SG_ 549 ADC_RPAtype 0;
BA_ "GenSigTimeoutValue" SG_ 549 ADC_RPAtype 0;
BA_ "Remark" SG_ 549 ADC_RPAtype "";
BA_ "EventCommandSignal" SG_ 549 ADC_VehPosYawrate 0;
BA_ "GatewayedSignals" SG_ 549 ADC_VehPosYawrate 0;
BA_ "GenSigInactiveValue" SG_ 549 ADC_VehPosYawrate 0;
BA_ "GenSigInvalidValue" SG_ 549 ADC_VehPosYawrate 0;
BA_ "GenSigSendType" SG_ 549 ADC_VehPosYawrate 1;
BA_ "GenSigStartValue" SG_ 549 ADC_VehPosYawrate 0;
BA_ "GenSigTimeoutValue" SG_ 549 ADC_VehPosYawrate 0;
BA_ "Remark" SG_ 549 ADC_VehPosYawrate "";
BA_ "EventCommandSignal" SG_ 549 ADC_SlotAngle 0;
BA_ "GatewayedSignals" SG_ 549 ADC_SlotAngle 0;
BA_ "GenSigInactiveValue" SG_ 549 ADC_SlotAngle 0;
BA_ "GenSigInvalidValue" SG_ 549 ADC_SlotAngle 0;
BA_ "GenSigSendType" SG_ 549 ADC_SlotAngle 1;
BA_ "GenSigStartValue" SG_ 549 ADC_SlotAngle 0;
BA_ "GenSigTimeoutValue" SG_ 549 ADC_SlotAngle 0;
BA_ "Remark" SG_ 549 ADC_SlotAngle "";
BA_ "EventCommandSignal" SG_ 549 ADC_DskScreenOperationReq 0;
BA_ "GatewayedSignals" SG_ 549 ADC_DskScreenOperationReq 0;
BA_ "GenSigInactiveValue" SG_ 549 ADC_DskScreenOperationReq 0;
BA_ "GenSigInvalidValue" SG_ 549 ADC_DskScreenOperationReq 0;
BA_ "GenSigSendType" SG_ 549 ADC_DskScreenOperationReq 1;
BA_ "GenSigStartValue" SG_ 549 ADC_DskScreenOperationReq 1;
BA_ "GenSigTimeoutValue" SG_ 549 ADC_DskScreenOperationReq 0;
BA_ "Remark" SG_ 549 ADC_DskScreenOperationReq "";
BA_ "EventCommandSignal" SG_ 549 ADC_SenslesEtyParkingSt 0;
BA_ "GatewayedSignals" SG_ 549 ADC_SenslesEtyParkingSt 0;
BA_ "GenSigInactiveValue" SG_ 549 ADC_SenslesEtyParkingSt 0;
BA_ "GenSigInvalidValue" SG_ 549 ADC_SenslesEtyParkingSt 0;
BA_ "GenSigSendType" SG_ 549 ADC_SenslesEtyParkingSt 1;
BA_ "GenSigStartValue" SG_ 549 ADC_SenslesEtyParkingSt 0;
BA_ "GenSigTimeoutValue" SG_ 549 ADC_SenslesEtyParkingSt 0;
BA_ "Remark" SG_ 549 ADC_SenslesEtyParkingSt "";
BA_ "EventCommandSignal" SG_ 549 ADC_PAALimitToast 0;
BA_ "GatewayedSignals" SG_ 549 ADC_PAALimitToast 0;
BA_ "GenSigInactiveValue" SG_ 549 ADC_PAALimitToast 0;
BA_ "GenSigInvalidValue" SG_ 549 ADC_PAALimitToast 0;
BA_ "GenSigSendType" SG_ 549 ADC_PAALimitToast 1;
BA_ "GenSigStartValue" SG_ 549 ADC_PAALimitToast 0;
BA_ "GenSigTimeoutValue" SG_ 549 ADC_PAALimitToast 0;
BA_ "Remark" SG_ 549 ADC_PAALimitToast "";
BA_ "EventCommandSignal" SG_ 549 ADC_PAALimitReminder 0;
BA_ "GatewayedSignals" SG_ 549 ADC_PAALimitReminder 0;
BA_ "GenSigInactiveValue" SG_ 549 ADC_PAALimitReminder 0;
BA_ "GenSigInvalidValue" SG_ 549 ADC_PAALimitReminder 0;
BA_ "GenSigSendType" SG_ 549 ADC_PAALimitReminder 1;
BA_ "GenSigStartValue" SG_ 549 ADC_PAALimitReminder 0;
BA_ "GenSigTimeoutValue" SG_ 549 ADC_PAALimitReminder 0;
BA_ "Remark" SG_ 549 ADC_PAALimitReminder "";
BA_ "EventCommandSignal" SG_ 549 ADC_ParkOutMode 0;
BA_ "GatewayedSignals" SG_ 549 ADC_ParkOutMode 0;
BA_ "GenSigInactiveValue" SG_ 549 ADC_ParkOutMode 0;
BA_ "GenSigInvalidValue" SG_ 549 ADC_ParkOutMode 0;
BA_ "GenSigSendType" SG_ 549 ADC_ParkOutMode 1;
BA_ "GenSigStartValue" SG_ 549 ADC_ParkOutMode 0;
BA_ "GenSigTimeoutValue" SG_ 549 ADC_ParkOutMode 0;
BA_ "Remark" SG_ 549 ADC_ParkOutMode "";
BA_ "EventCommandSignal" SG_ 549 ADAS_ParkStats 0;
BA_ "GatewayedSignals" SG_ 549 ADAS_ParkStats 0;
BA_ "GenSigInactiveValue" SG_ 549 ADAS_ParkStats 0;
BA_ "GenSigInvalidValue" SG_ 549 ADAS_ParkStats 0;
BA_ "GenSigSendType" SG_ 549 ADAS_ParkStats 1;
BA_ "GenSigStartValue" SG_ 549 ADAS_ParkStats 0;
BA_ "GenSigTimeoutValue" SG_ 549 ADAS_ParkStats 0;
BA_ "Remark" SG_ 549 ADAS_ParkStats "";
BA_ "EventCommandSignal" SG_ 549 ADC_ParkinDir 0;
BA_ "GatewayedSignals" SG_ 549 ADC_ParkinDir 0;
BA_ "GenSigInactiveValue" SG_ 549 ADC_ParkinDir 0;
BA_ "GenSigInvalidValue" SG_ 549 ADC_ParkinDir 0;
BA_ "GenSigSendType" SG_ 549 ADC_ParkinDir 1;
BA_ "GenSigStartValue" SG_ 549 ADC_ParkinDir 0;
BA_ "GenSigTimeoutValue" SG_ 549 ADC_ParkinDir 0;
BA_ "Remark" SG_ 549 ADC_ParkinDir "";
BA_ "EventCommandSignal" SG_ 549 ADC_FrontEndParkInRes 0;
BA_ "GatewayedSignals" SG_ 549 ADC_FrontEndParkInRes 0;
BA_ "GenSigInactiveValue" SG_ 549 ADC_FrontEndParkInRes 0;
BA_ "GenSigInvalidValue" SG_ 549 ADC_FrontEndParkInRes 0;
BA_ "GenSigSendType" SG_ 549 ADC_FrontEndParkInRes 1;
BA_ "GenSigStartValue" SG_ 549 ADC_FrontEndParkInRes 0;
BA_ "GenSigTimeoutValue" SG_ 549 ADC_FrontEndParkInRes 0;
BA_ "Remark" SG_ 549 ADC_FrontEndParkInRes "";
BA_ "EventCommandSignal" SG_ 549 ADC_ParkSlotType 0;
BA_ "GatewayedSignals" SG_ 549 ADC_ParkSlotType 0;
BA_ "GenSigInactiveValue" SG_ 549 ADC_ParkSlotType 0;
BA_ "GenSigInvalidValue" SG_ 549 ADC_ParkSlotType 0;
BA_ "GenSigSendType" SG_ 549 ADC_ParkSlotType 1;
BA_ "GenSigStartValue" SG_ 549 ADC_ParkSlotType 0;
BA_ "GenSigTimeoutValue" SG_ 549 ADC_ParkSlotType 0;
BA_ "Remark" SG_ 549 ADC_ParkSlotType "";
BA_ "EventCommandSignal" SG_ 549 ADC_BleRPAPageSt 0;
BA_ "GatewayedSignals" SG_ 549 ADC_BleRPAPageSt 0;
BA_ "GenSigInactiveValue" SG_ 549 ADC_BleRPAPageSt 0;
BA_ "GenSigInvalidValue" SG_ 549 ADC_BleRPAPageSt 0;
BA_ "GenSigSendType" SG_ 549 ADC_BleRPAPageSt 1;
BA_ "GenSigStartValue" SG_ 549 ADC_BleRPAPageSt 0;
BA_ "GenSigTimeoutValue" SG_ 549 ADC_BleRPAPageSt 0;
BA_ "Remark" SG_ 549 ADC_BleRPAPageSt "";
BA_ "EventCommandSignal" SG_ 549 ADC_RPAPreferRes 0;
BA_ "GatewayedSignals" SG_ 549 ADC_RPAPreferRes 0;
BA_ "GenSigInactiveValue" SG_ 549 ADC_RPAPreferRes 0;
BA_ "GenSigInvalidValue" SG_ 549 ADC_RPAPreferRes 0;
BA_ "GenSigSendType" SG_ 549 ADC_RPAPreferRes 1;
BA_ "GenSigStartValue" SG_ 549 ADC_RPAPreferRes 0;
BA_ "GenSigTimeoutValue" SG_ 549 ADC_RPAPreferRes 0;
BA_ "Remark" SG_ 549 ADC_RPAPreferRes "";
BA_ "EventCommandSignal" SG_ 549 ADC_RPAPrkSlotoffset 0;
BA_ "GatewayedSignals" SG_ 549 ADC_RPAPrkSlotoffset 0;
BA_ "GenSigInactiveValue" SG_ 549 ADC_RPAPrkSlotoffset 0;
BA_ "GenSigInvalidValue" SG_ 549 ADC_RPAPrkSlotoffset 0;
BA_ "GenSigSendType" SG_ 549 ADC_RPAPrkSlotoffset 1;
BA_ "GenSigStartValue" SG_ 549 ADC_RPAPrkSlotoffset 0;
BA_ "GenSigTimeoutValue" SG_ 549 ADC_RPAPrkSlotoffset 0;
BA_ "Remark" SG_ 549 ADC_RPAPrkSlotoffset "";
BA_ "EventCommandSignal" SG_ 549 ADC_RPAPreferavl 0;
BA_ "GatewayedSignals" SG_ 549 ADC_RPAPreferavl 0;
BA_ "GenSigInactiveValue" SG_ 549 ADC_RPAPreferavl 0;
BA_ "GenSigInvalidValue" SG_ 549 ADC_RPAPreferavl 0;
BA_ "GenSigSendType" SG_ 549 ADC_RPAPreferavl 1;
BA_ "GenSigStartValue" SG_ 549 ADC_RPAPreferavl 0;
BA_ "GenSigTimeoutValue" SG_ 549 ADC_RPAPreferavl 0;
BA_ "Remark" SG_ 549 ADC_RPAPreferavl "";
BA_ "EventCommandSignal" SG_ 549 ADC_RPABlechnReq 0;
BA_ "GatewayedSignals" SG_ 549 ADC_RPABlechnReq 0;
BA_ "GenSigInactiveValue" SG_ 549 ADC_RPABlechnReq 0;
BA_ "GenSigInvalidValue" SG_ 549 ADC_RPABlechnReq 0;
BA_ "GenSigSendType" SG_ 549 ADC_RPABlechnReq 1;
BA_ "GenSigStartValue" SG_ 549 ADC_RPABlechnReq 0;
BA_ "GenSigTimeoutValue" SG_ 549 ADC_RPABlechnReq 0;
BA_ "Remark" SG_ 549 ADC_RPABlechnReq "";
BA_ "EventCommandSignal" SG_ 549 ADC_RPABlePushSt 0;
BA_ "GatewayedSignals" SG_ 549 ADC_RPABlePushSt 0;
BA_ "GenSigInactiveValue" SG_ 549 ADC_RPABlePushSt 0;
BA_ "GenSigInvalidValue" SG_ 549 ADC_RPABlePushSt 0;
BA_ "GenSigSendType" SG_ 549 ADC_RPABlePushSt 1;
BA_ "GenSigStartValue" SG_ 549 ADC_RPABlePushSt 0;
BA_ "GenSigTimeoutValue" SG_ 549 ADC_RPABlePushSt 0;
BA_ "Remark" SG_ 549 ADC_RPABlePushSt "";
BA_ "EventCommandSignal" SG_ 1359 CCU_NMNodeAddress 0;
BA_ "GatewayedSignals" SG_ 1359 CCU_NMNodeAddress 0;
BA_ "GenSigInactiveValue" SG_ 1359 CCU_NMNodeAddress 0;
BA_ "GenSigInvalidValue" SG_ 1359 CCU_NMNodeAddress 0;
BA_ "GenSigSendType" SG_ 1359 CCU_NMNodeAddress 1;
BA_ "GenSigStartValue" SG_ 1359 CCU_NMNodeAddress 79;
BA_ "GenSigTimeoutValue" SG_ 1359 CCU_NMNodeAddress 0;
BA_ "Remark" SG_ 1359 CCU_NMNodeAddress "";
BA_ "EventCommandSignal" SG_ 1359 CCU_NMCBV 0;
BA_ "GatewayedSignals" SG_ 1359 CCU_NMCBV 0;
BA_ "GenSigInactiveValue" SG_ 1359 CCU_NMCBV 0;
BA_ "GenSigInvalidValue" SG_ 1359 CCU_NMCBV 0;
BA_ "GenSigSendType" SG_ 1359 CCU_NMCBV 1;
BA_ "GenSigStartValue" SG_ 1359 CCU_NMCBV 0;
BA_ "GenSigTimeoutValue" SG_ 1359 CCU_NMCBV 0;
BA_ "Remark" SG_ 1359 CCU_NMCBV "";
BA_ "EventCommandSignal" SG_ 1359 CCU_NMWakeupOrigin 0;
BA_ "GatewayedSignals" SG_ 1359 CCU_NMWakeupOrigin 0;
BA_ "GenSigInactiveValue" SG_ 1359 CCU_NMWakeupOrigin 0;
BA_ "GenSigInvalidValue" SG_ 1359 CCU_NMWakeupOrigin 0;
BA_ "GenSigSendType" SG_ 1359 CCU_NMWakeupOrigin 1;
BA_ "GenSigStartValue" SG_ 1359 CCU_NMWakeupOrigin 0;
BA_ "GenSigTimeoutValue" SG_ 1359 CCU_NMWakeupOrigin 0;
BA_ "Remark" SG_ 1359 CCU_NMWakeupOrigin "";
BA_ "EventCommandSignal" SG_ 1359 CCU_PNCInformation0 0;
BA_ "GatewayedSignals" SG_ 1359 CCU_PNCInformation0 0;
BA_ "GenSigInactiveValue" SG_ 1359 CCU_PNCInformation0 0;
BA_ "GenSigInvalidValue" SG_ 1359 CCU_PNCInformation0 0;
BA_ "GenSigSendType" SG_ 1359 CCU_PNCInformation0 1;
BA_ "GenSigStartValue" SG_ 1359 CCU_PNCInformation0 0;
BA_ "GenSigTimeoutValue" SG_ 1359 CCU_PNCInformation0 0;
BA_ "Remark" SG_ 1359 CCU_PNCInformation0 "";
BA_ "EventCommandSignal" SG_ 1359 CCU_PNCInformation1 0;
BA_ "GatewayedSignals" SG_ 1359 CCU_PNCInformation1 0;
BA_ "GenSigInactiveValue" SG_ 1359 CCU_PNCInformation1 0;
BA_ "GenSigInvalidValue" SG_ 1359 CCU_PNCInformation1 0;
BA_ "GenSigSendType" SG_ 1359 CCU_PNCInformation1 1;
BA_ "GenSigStartValue" SG_ 1359 CCU_PNCInformation1 0;
BA_ "GenSigTimeoutValue" SG_ 1359 CCU_PNCInformation1 0;
BA_ "Remark" SG_ 1359 CCU_PNCInformation1 "";
BA_ "EventCommandSignal" SG_ 1359 CCU_PNCInformation2 0;
BA_ "GatewayedSignals" SG_ 1359 CCU_PNCInformation2 0;
BA_ "GenSigInactiveValue" SG_ 1359 CCU_PNCInformation2 0;
BA_ "GenSigInvalidValue" SG_ 1359 CCU_PNCInformation2 0;
BA_ "GenSigSendType" SG_ 1359 CCU_PNCInformation2 1;
BA_ "GenSigStartValue" SG_ 1359 CCU_PNCInformation2 0;
BA_ "GenSigTimeoutValue" SG_ 1359 CCU_PNCInformation2 0;
BA_ "Remark" SG_ 1359 CCU_PNCInformation2 "";
BA_ "EventCommandSignal" SG_ 905 ICM_SetIACCSt 0;
BA_ "GatewayedSignals" SG_ 905 ICM_SetIACCSt 0;
BA_ "GenSigInactiveValue" SG_ 905 ICM_SetIACCSt 0;
BA_ "GenSigInvalidValue" SG_ 905 ICM_SetIACCSt 0;
BA_ "GenSigSendType" SG_ 905 ICM_SetIACCSt 1;
BA_ "GenSigStartValue" SG_ 905 ICM_SetIACCSt 0;
BA_ "GenSigTimeoutValue" SG_ 905 ICM_SetIACCSt 0;
BA_ "Remark" SG_ 905 ICM_SetIACCSt "";
BA_ "EventCommandSignal" SG_ 905 ICM_TotalOdometer 0;
BA_ "GatewayedSignals" SG_ 905 ICM_TotalOdometer 0;
BA_ "GenSigInactiveValue" SG_ 905 ICM_TotalOdometer 0;
BA_ "GenSigInvalidValue" SG_ 905 ICM_TotalOdometer 0;
BA_ "GenSigSendType" SG_ 905 ICM_TotalOdometer 1;
BA_ "GenSigStartValue" SG_ 905 ICM_TotalOdometer 0;
BA_ "EventCommandSignal" SG_ 905 ICM_VehInsSpd 0;
BA_ "GatewayedSignals" SG_ 905 ICM_VehInsSpd 0;
BA_ "GenSigInactiveValue" SG_ 905 ICM_VehInsSpd 0;
BA_ "GenSigInvalidValue" SG_ 905 ICM_VehInsSpd 255;
BA_ "GenSigSendType" SG_ 905 ICM_VehInsSpd 1;
BA_ "GenSigStartValue" SG_ 905 ICM_VehInsSpd 0;
BA_ "GenSigTimeoutValue" SG_ 905 ICM_VehInsSpd 0;
BA_ "Remark" SG_ 905 ICM_VehInsSpd "";
BA_ "EventCommandSignal" SG_ 905 ICM_VehInsSpd_accurate 0;
BA_ "GatewayedSignals" SG_ 905 ICM_VehInsSpd_accurate 0;
BA_ "GenSigInactiveValue" SG_ 905 ICM_VehInsSpd_accurate 0;
BA_ "GenSigInvalidValue" SG_ 905 ICM_VehInsSpd_accurate 2047;
BA_ "GenSigSendType" SG_ 905 ICM_VehInsSpd_accurate 1;
BA_ "GenSigStartValue" SG_ 905 ICM_VehInsSpd_accurate 0;
BA_ "GenSigTimeoutValue" SG_ 905 ICM_VehInsSpd_accurate 0;
BA_ "Remark" SG_ 905 ICM_VehInsSpd_accurate "";
BA_ "EventCommandSignal" SG_ 905 ICM_FuelAvaibleDriveDistance 0;
BA_ "GatewayedSignals" SG_ 905 ICM_FuelAvaibleDriveDistance 0;
BA_ "GenSigInactiveValue" SG_ 905 ICM_FuelAvaibleDriveDistance 0;
BA_ "GenSigInvalidValue" SG_ 905 ICM_FuelAvaibleDriveDistance 2047;
BA_ "GenSigSendType" SG_ 905 ICM_FuelAvaibleDriveDistance 1;
BA_ "GenSigStartValue" SG_ 905 ICM_FuelAvaibleDriveDistance 0;
BA_ "GenSigTimeoutValue" SG_ 905 ICM_FuelAvaibleDriveDistance 0;
BA_ "Remark" SG_ 905 ICM_FuelAvaibleDriveDistance "";
BA_ "EventCommandSignal" SG_ 905 ICM_TotalAvaibleDriveDistance 0;
BA_ "GatewayedSignals" SG_ 905 ICM_TotalAvaibleDriveDistance 0;
BA_ "GenSigInactiveValue" SG_ 905 ICM_TotalAvaibleDriveDistance 0;
BA_ "GenSigInvalidValue" SG_ 905 ICM_TotalAvaibleDriveDistance 2047;
BA_ "GenSigSendType" SG_ 905 ICM_TotalAvaibleDriveDistance 1;
BA_ "GenSigStartValue" SG_ 905 ICM_TotalAvaibleDriveDistance 0;
BA_ "GenSigTimeoutValue" SG_ 905 ICM_TotalAvaibleDriveDistance 0;
BA_ "Remark" SG_ 905 ICM_TotalAvaibleDriveDistance "";
BA_ "EventCommandSignal" SG_ 516 VCU_9_CRC 0;
BA_ "GatewayedSignals" SG_ 516 VCU_9_CRC 0;
BA_ "GenSigInactiveValue" SG_ 516 VCU_9_CRC 0;
BA_ "GenSigInvalidValue" SG_ 516 VCU_9_CRC 0;
BA_ "GenSigSendType" SG_ 516 VCU_9_CRC 1;
BA_ "GenSigStartValue" SG_ 516 VCU_9_CRC 0;
BA_ "GenSigTimeoutValue" SG_ 516 VCU_9_CRC 0;
BA_ "Remark" SG_ 516 VCU_9_CRC "涉及ID管理表";
BA_ "EventCommandSignal" SG_ 516 VCU_9_Counter 0;
BA_ "GatewayedSignals" SG_ 516 VCU_9_Counter 0;
BA_ "GenSigInactiveValue" SG_ 516 VCU_9_Counter 0;
BA_ "GenSigInvalidValue" SG_ 516 VCU_9_Counter 0;
BA_ "GenSigSendType" SG_ 516 VCU_9_Counter 1;
BA_ "GenSigStartValue" SG_ 516 VCU_9_Counter 0;
BA_ "GenSigTimeoutValue" SG_ 516 VCU_9_Counter 0;
BA_ "Remark" SG_ 516 VCU_9_Counter "涉及ID管理表";
BA_ "EventCommandSignal" SG_ 516 VCU_MaxDriveTorqVD 0;
BA_ "GatewayedSignals" SG_ 516 VCU_MaxDriveTorqVD 0;
BA_ "GenSigInactiveValue" SG_ 516 VCU_MaxDriveTorqVD 0;
BA_ "GenSigInvalidValue" SG_ 516 VCU_MaxDriveTorqVD 0;
BA_ "GenSigSendType" SG_ 516 VCU_MaxDriveTorqVD 1;
BA_ "GenSigStartValue" SG_ 516 VCU_MaxDriveTorqVD 0;
BA_ "GenSigTimeoutValue" SG_ 516 VCU_MaxDriveTorqVD 0;
BA_ "Remark" SG_ 516 VCU_MaxDriveTorqVD "涉及ID管理表";
BA_ "EventCommandSignal" SG_ 516 VCU_RecpTorqVD 0;
BA_ "GatewayedSignals" SG_ 516 VCU_RecpTorqVD 0;
BA_ "GenSigInactiveValue" SG_ 516 VCU_RecpTorqVD 0;
BA_ "GenSigInvalidValue" SG_ 516 VCU_RecpTorqVD 0;
BA_ "GenSigSendType" SG_ 516 VCU_RecpTorqVD 1;
BA_ "GenSigStartValue" SG_ 516 VCU_RecpTorqVD 0;
BA_ "GenSigTimeoutValue" SG_ 516 VCU_RecpTorqVD 0;
BA_ "Remark" SG_ 516 VCU_RecpTorqVD "涉及ID管理表";
BA_ "EventCommandSignal" SG_ 516 VCU_MaxRecpTorqVD 0;
BA_ "GatewayedSignals" SG_ 516 VCU_MaxRecpTorqVD 0;
BA_ "GenSigInactiveValue" SG_ 516 VCU_MaxRecpTorqVD 0;
BA_ "GenSigInvalidValue" SG_ 516 VCU_MaxRecpTorqVD 0;
BA_ "GenSigSendType" SG_ 516 VCU_MaxRecpTorqVD 1;
BA_ "GenSigStartValue" SG_ 516 VCU_MaxRecpTorqVD 0;
BA_ "GenSigTimeoutValue" SG_ 516 VCU_MaxRecpTorqVD 0;
BA_ "Remark" SG_ 516 VCU_MaxRecpTorqVD "涉及ID管理表";
BA_ "EventCommandSignal" SG_ 516 VCU_CrntGearLvl 0;
BA_ "GatewayedSignals" SG_ 516 VCU_CrntGearLvl 0;
BA_ "GenSigInactiveValue" SG_ 516 VCU_CrntGearLvl 0;
BA_ "GenSigInvalidValue" SG_ 516 VCU_CrntGearLvl 0;
BA_ "GenSigSendType" SG_ 516 VCU_CrntGearLvl 1;
BA_ "GenSigStartValue" SG_ 516 VCU_CrntGearLvl 0;
BA_ "GenSigTimeoutValue" SG_ 516 VCU_CrntGearLvl 0;
BA_ "Remark" SG_ 516 VCU_CrntGearLvl "涉及ID管理表";
BA_ "EventCommandSignal" SG_ 516 VCU_CrntGearLvlVD 0;
BA_ "GatewayedSignals" SG_ 516 VCU_CrntGearLvlVD 0;
BA_ "GenSigInactiveValue" SG_ 516 VCU_CrntGearLvlVD 0;
BA_ "GenSigInvalidValue" SG_ 516 VCU_CrntGearLvlVD 0;
BA_ "GenSigSendType" SG_ 516 VCU_CrntGearLvlVD 1;
BA_ "GenSigStartValue" SG_ 516 VCU_CrntGearLvlVD 0;
BA_ "GenSigTimeoutValue" SG_ 516 VCU_CrntGearLvlVD 0;
BA_ "Remark" SG_ 516 VCU_CrntGearLvlVD "涉及ID管理表";
BA_ "EventCommandSignal" SG_ 516 VCU_BrkPedPstVD 0;
BA_ "GatewayedSignals" SG_ 516 VCU_BrkPedPstVD 0;
BA_ "GenSigInactiveValue" SG_ 516 VCU_BrkPedPstVD 0;
BA_ "GenSigInvalidValue" SG_ 516 VCU_BrkPedPstVD 0;
BA_ "GenSigSendType" SG_ 516 VCU_BrkPedPstVD 1;
BA_ "GenSigStartValue" SG_ 516 VCU_BrkPedPstVD 0;
BA_ "GenSigTimeoutValue" SG_ 516 VCU_BrkPedPstVD 0;
BA_ "Remark" SG_ 516 VCU_BrkPedPstVD "涉及ID管理表";
BA_ "EventCommandSignal" SG_ 516 VCU_BrkPedPst 0;
BA_ "GatewayedSignals" SG_ 516 VCU_BrkPedPst 0;
BA_ "GenSigInactiveValue" SG_ 516 VCU_BrkPedPst 0;
BA_ "GenSigInvalidValue" SG_ 516 VCU_BrkPedPst 0;
BA_ "GenSigSendType" SG_ 516 VCU_BrkPedPst 1;
BA_ "GenSigStartValue" SG_ 516 VCU_BrkPedPst 0;
BA_ "GenSigTimeoutValue" SG_ 516 VCU_BrkPedPst 0;
BA_ "Remark" SG_ 516 VCU_BrkPedPst "涉及ID管理表";
BA_ "EventCommandSignal" SG_ 516 VCU_GearIntervern 0;
BA_ "GatewayedSignals" SG_ 516 VCU_GearIntervern 0;
BA_ "GenSigInactiveValue" SG_ 516 VCU_GearIntervern 0;
BA_ "GenSigInvalidValue" SG_ 516 VCU_GearIntervern 0;
BA_ "GenSigSendType" SG_ 516 VCU_GearIntervern 1;
BA_ "GenSigStartValue" SG_ 516 VCU_GearIntervern 0;
BA_ "GenSigTimeoutValue" SG_ 516 VCU_GearIntervern 0;
BA_ "Remark" SG_ 516 VCU_GearIntervern "涉及ID管理表";
BA_ "EventCommandSignal" SG_ 516 VCU_AccPedalVirtPstVD 0;
BA_ "GatewayedSignals" SG_ 516 VCU_AccPedalVirtPstVD 0;
BA_ "GenSigInactiveValue" SG_ 516 VCU_AccPedalVirtPstVD 0;
BA_ "GenSigInvalidValue" SG_ 516 VCU_AccPedalVirtPstVD 0;
BA_ "GenSigSendType" SG_ 516 VCU_AccPedalVirtPstVD 1;
BA_ "GenSigStartValue" SG_ 516 VCU_AccPedalVirtPstVD 0;
BA_ "GenSigTimeoutValue" SG_ 516 VCU_AccPedalVirtPstVD 0;
BA_ "Remark" SG_ 516 VCU_AccPedalVirtPstVD "涉及ID管理表";
BA_ "EventCommandSignal" SG_ 516 VCU_ActVehWheelTorq 0;
BA_ "GatewayedSignals" SG_ 516 VCU_ActVehWheelTorq 0;
BA_ "GenSigInactiveValue" SG_ 516 VCU_ActVehWheelTorq 0;
BA_ "GenSigInvalidValue" SG_ 516 VCU_ActVehWheelTorq 32767;
BA_ "GenSigSendType" SG_ 516 VCU_ActVehWheelTorq 1;
BA_ "GenSigStartValue" SG_ 516 VCU_ActVehWheelTorq 32766;
BA_ "GenSigTimeoutValue" SG_ 516 VCU_ActVehWheelTorq 0;
BA_ "Remark" SG_ 516 VCU_ActVehWheelTorq "涉及ID管理表";
BA_ "EventCommandSignal" SG_ 516 VCU_MaxRecpTorq 0;
BA_ "GatewayedSignals" SG_ 516 VCU_MaxRecpTorq 0;
BA_ "GenSigInactiveValue" SG_ 516 VCU_MaxRecpTorq 0;
BA_ "GenSigInvalidValue" SG_ 516 VCU_MaxRecpTorq 0;
BA_ "GenSigSendType" SG_ 516 VCU_MaxRecpTorq 1;
BA_ "GenSigStartValue" SG_ 516 VCU_MaxRecpTorq 0;
BA_ "GenSigTimeoutValue" SG_ 516 VCU_MaxRecpTorq 0;
BA_ "Remark" SG_ 516 VCU_MaxRecpTorq "涉及ID管理表";
BA_ "EventCommandSignal" SG_ 516 VCU_AccPedalVirtPst 0;
BA_ "GatewayedSignals" SG_ 516 VCU_AccPedalVirtPst 0;
BA_ "GenSigInactiveValue" SG_ 516 VCU_AccPedalVirtPst 0;
BA_ "GenSigInvalidValue" SG_ 516 VCU_AccPedalVirtPst 0;
BA_ "GenSigSendType" SG_ 516 VCU_AccPedalVirtPst 1;
BA_ "GenSigStartValue" SG_ 516 VCU_AccPedalVirtPst 0;
BA_ "GenSigTimeoutValue" SG_ 516 VCU_AccPedalVirtPst 0;
BA_ "Remark" SG_ 516 VCU_AccPedalVirtPst "涉及ID管理表";
BA_ "EventCommandSignal" SG_ 516 VCU_BrkPedalSt 0;
BA_ "GatewayedSignals" SG_ 516 VCU_BrkPedalSt 0;
BA_ "GenSigInactiveValue" SG_ 516 VCU_BrkPedalSt 0;
BA_ "GenSigInvalidValue" SG_ 516 VCU_BrkPedalSt 0;
BA_ "GenSigSendType" SG_ 516 VCU_BrkPedalSt 1;
BA_ "GenSigStartValue" SG_ 516 VCU_BrkPedalSt 0;
BA_ "GenSigTimeoutValue" SG_ 516 VCU_BrkPedalSt 0;
BA_ "Remark" SG_ 516 VCU_BrkPedalSt "涉及ID管理表";
BA_ "EventCommandSignal" SG_ 516 VCU_BrkPedalStVD 0;
BA_ "GatewayedSignals" SG_ 516 VCU_BrkPedalStVD 0;
BA_ "GenSigInactiveValue" SG_ 516 VCU_BrkPedalStVD 0;
BA_ "GenSigInvalidValue" SG_ 516 VCU_BrkPedalStVD 0;
BA_ "GenSigSendType" SG_ 516 VCU_BrkPedalStVD 1;
BA_ "GenSigStartValue" SG_ 516 VCU_BrkPedalStVD 0;
BA_ "GenSigTimeoutValue" SG_ 516 VCU_BrkPedalStVD 0;
BA_ "Remark" SG_ 516 VCU_BrkPedalStVD "涉及ID管理表";
BA_ "EventCommandSignal" SG_ 516 VCU_ACCLimitOperatingSt 0;
BA_ "GatewayedSignals" SG_ 516 VCU_ACCLimitOperatingSt 0;
BA_ "GenSigInactiveValue" SG_ 516 VCU_ACCLimitOperatingSt 0;
BA_ "GenSigInvalidValue" SG_ 516 VCU_ACCLimitOperatingSt 0;
BA_ "GenSigSendType" SG_ 516 VCU_ACCLimitOperatingSt 1;
BA_ "GenSigStartValue" SG_ 516 VCU_ACCLimitOperatingSt 0;
BA_ "GenSigTimeoutValue" SG_ 516 VCU_ACCLimitOperatingSt 0;
BA_ "Remark" SG_ 516 VCU_ACCLimitOperatingSt "涉及ID管理表";
BA_ "EventCommandSignal" SG_ 516 VCU_AccButtInfo 0;
BA_ "GatewayedSignals" SG_ 516 VCU_AccButtInfo 0;
BA_ "GenSigInactiveValue" SG_ 516 VCU_AccButtInfo 0;
BA_ "GenSigInvalidValue" SG_ 516 VCU_AccButtInfo 0;
BA_ "GenSigSendType" SG_ 516 VCU_AccButtInfo 1;
BA_ "GenSigStartValue" SG_ 516 VCU_AccButtInfo 0;
BA_ "GenSigTimeoutValue" SG_ 516 VCU_AccButtInfo 0;
BA_ "Remark" SG_ 516 VCU_AccButtInfo "涉及ID管理表";
BA_ "EventCommandSignal" SG_ 516 VCU_ACCmaxSpdLimit 0;
BA_ "GatewayedSignals" SG_ 516 VCU_ACCmaxSpdLimit 0;
BA_ "GenSigInactiveValue" SG_ 516 VCU_ACCmaxSpdLimit 0;
BA_ "GenSigInvalidValue" SG_ 516 VCU_ACCmaxSpdLimit 0;
BA_ "GenSigSendType" SG_ 516 VCU_ACCmaxSpdLimit 1;
BA_ "GenSigStartValue" SG_ 516 VCU_ACCmaxSpdLimit 0;
BA_ "GenSigTimeoutValue" SG_ 516 VCU_ACCmaxSpdLimit 0;
BA_ "Remark" SG_ 516 VCU_ACCmaxSpdLimit "涉及ID管理表";
BA_ "EventCommandSignal" SG_ 516 VCU_RecpTorqFAVD 0;
BA_ "GatewayedSignals" SG_ 516 VCU_RecpTorqFAVD 0;
BA_ "GenSigInactiveValue" SG_ 516 VCU_RecpTorqFAVD 0;
BA_ "GenSigInvalidValue" SG_ 516 VCU_RecpTorqFAVD 0;
BA_ "GenSigSendType" SG_ 516 VCU_RecpTorqFAVD 1;
BA_ "GenSigStartValue" SG_ 516 VCU_RecpTorqFAVD 0;
BA_ "GenSigTimeoutValue" SG_ 516 VCU_RecpTorqFAVD 0;
BA_ "Remark" SG_ 516 VCU_RecpTorqFAVD "涉及ID管理表";
BA_ "EventCommandSignal" SG_ 516 VCU_RecpTorqRAVD 0;
BA_ "GatewayedSignals" SG_ 516 VCU_RecpTorqRAVD 0;
BA_ "GenSigInactiveValue" SG_ 516 VCU_RecpTorqRAVD 0;
BA_ "GenSigInvalidValue" SG_ 516 VCU_RecpTorqRAVD 0;
BA_ "GenSigSendType" SG_ 516 VCU_RecpTorqRAVD 1;
BA_ "GenSigStartValue" SG_ 516 VCU_RecpTorqRAVD 0;
BA_ "GenSigTimeoutValue" SG_ 516 VCU_RecpTorqRAVD 0;
BA_ "Remark" SG_ 516 VCU_RecpTorqRAVD "涉及ID管理表";
BA_ "EventCommandSignal" SG_ 516 VCU_MaxRecpTorqFAVD 0;
BA_ "GatewayedSignals" SG_ 516 VCU_MaxRecpTorqFAVD 0;
BA_ "GenSigInactiveValue" SG_ 516 VCU_MaxRecpTorqFAVD 0;
BA_ "GenSigInvalidValue" SG_ 516 VCU_MaxRecpTorqFAVD 0;
BA_ "GenSigSendType" SG_ 516 VCU_MaxRecpTorqFAVD 1;
BA_ "GenSigStartValue" SG_ 516 VCU_MaxRecpTorqFAVD 0;
BA_ "GenSigTimeoutValue" SG_ 516 VCU_MaxRecpTorqFAVD 0;
BA_ "Remark" SG_ 516 VCU_MaxRecpTorqFAVD "涉及ID管理表";
BA_ "EventCommandSignal" SG_ 516 VCU_MaxRecpTorqRAVD 0;
BA_ "GatewayedSignals" SG_ 516 VCU_MaxRecpTorqRAVD 0;
BA_ "GenSigInactiveValue" SG_ 516 VCU_MaxRecpTorqRAVD 0;
BA_ "GenSigInvalidValue" SG_ 516 VCU_MaxRecpTorqRAVD 0;
BA_ "GenSigSendType" SG_ 516 VCU_MaxRecpTorqRAVD 1;
BA_ "GenSigStartValue" SG_ 516 VCU_MaxRecpTorqRAVD 0;
BA_ "GenSigTimeoutValue" SG_ 516 VCU_MaxRecpTorqRAVD 0;
BA_ "Remark" SG_ 516 VCU_MaxRecpTorqRAVD "涉及ID管理表";
BA_ "EventCommandSignal" SG_ 516 VCU_RecpTorq 0;
BA_ "GatewayedSignals" SG_ 516 VCU_RecpTorq 0;
BA_ "GenSigInactiveValue" SG_ 516 VCU_RecpTorq 0;
BA_ "GenSigInvalidValue" SG_ 516 VCU_RecpTorq 0;
BA_ "GenSigSendType" SG_ 516 VCU_RecpTorq 1;
BA_ "GenSigStartValue" SG_ 516 VCU_RecpTorq 0;
BA_ "GenSigTimeoutValue" SG_ 516 VCU_RecpTorq 0;
BA_ "Remark" SG_ 516 VCU_RecpTorq "涉及ID管理表";
BA_ "EventCommandSignal" SG_ 516 VCU_MaxDriveTorq 0;
BA_ "GatewayedSignals" SG_ 516 VCU_MaxDriveTorq 0;
BA_ "GenSigInactiveValue" SG_ 516 VCU_MaxDriveTorq 0;
BA_ "GenSigInvalidValue" SG_ 516 VCU_MaxDriveTorq 16383;
BA_ "GenSigSendType" SG_ 516 VCU_MaxDriveTorq 1;
BA_ "GenSigStartValue" SG_ 516 VCU_MaxDriveTorq 16382;
BA_ "GenSigTimeoutValue" SG_ 516 VCU_MaxDriveTorq 0;
BA_ "Remark" SG_ 516 VCU_MaxDriveTorq "涉及ID管理表";
BA_ "EventCommandSignal" SG_ 516 VCU_RecpTorqFA 0;
BA_ "GatewayedSignals" SG_ 516 VCU_RecpTorqFA 0;
BA_ "GenSigInactiveValue" SG_ 516 VCU_RecpTorqFA 0;
BA_ "GenSigInvalidValue" SG_ 516 VCU_RecpTorqFA 0;
BA_ "GenSigSendType" SG_ 516 VCU_RecpTorqFA 1;
BA_ "GenSigStartValue" SG_ 516 VCU_RecpTorqFA 0;
BA_ "GenSigTimeoutValue" SG_ 516 VCU_RecpTorqFA 0;
BA_ "Remark" SG_ 516 VCU_RecpTorqFA "涉及ID管理表";
BA_ "EventCommandSignal" SG_ 516 VCU_RecpTorqRA 0;
BA_ "GatewayedSignals" SG_ 516 VCU_RecpTorqRA 0;
BA_ "GenSigInactiveValue" SG_ 516 VCU_RecpTorqRA 0;
BA_ "GenSigInvalidValue" SG_ 516 VCU_RecpTorqRA 0;
BA_ "GenSigSendType" SG_ 516 VCU_RecpTorqRA 1;
BA_ "GenSigStartValue" SG_ 516 VCU_RecpTorqRA 0;
BA_ "GenSigTimeoutValue" SG_ 516 VCU_RecpTorqRA 0;
BA_ "Remark" SG_ 516 VCU_RecpTorqRA "涉及ID管理表";
BA_ "EventCommandSignal" SG_ 516 VCU_MaxRecpTorqFA 0;
BA_ "GatewayedSignals" SG_ 516 VCU_MaxRecpTorqFA 0;
BA_ "GenSigInactiveValue" SG_ 516 VCU_MaxRecpTorqFA 0;
BA_ "GenSigInvalidValue" SG_ 516 VCU_MaxRecpTorqFA 0;
BA_ "GenSigSendType" SG_ 516 VCU_MaxRecpTorqFA 1;
BA_ "GenSigStartValue" SG_ 516 VCU_MaxRecpTorqFA 0;
BA_ "GenSigTimeoutValue" SG_ 516 VCU_MaxRecpTorqFA 0;
BA_ "Remark" SG_ 516 VCU_MaxRecpTorqFA "涉及ID管理表";
BA_ "EventCommandSignal" SG_ 516 VCU_MaxRecpTorqRA 0;
BA_ "GatewayedSignals" SG_ 516 VCU_MaxRecpTorqRA 0;
BA_ "GenSigInactiveValue" SG_ 516 VCU_MaxRecpTorqRA 0;
BA_ "GenSigInvalidValue" SG_ 516 VCU_MaxRecpTorqRA 0;
BA_ "GenSigSendType" SG_ 516 VCU_MaxRecpTorqRA 1;
BA_ "GenSigStartValue" SG_ 516 VCU_MaxRecpTorqRA 0;
BA_ "GenSigTimeoutValue" SG_ 516 VCU_MaxRecpTorqRA 0;
BA_ "Remark" SG_ 516 VCU_MaxRecpTorqRA "涉及ID管理表";
BA_ "EventCommandSignal" SG_ 516 VCU_BcsDecelEnable 0;
BA_ "GatewayedSignals" SG_ 516 VCU_BcsDecelEnable 0;
BA_ "GenSigInactiveValue" SG_ 516 VCU_BcsDecelEnable 0;
BA_ "GenSigInvalidValue" SG_ 516 VCU_BcsDecelEnable 0;
BA_ "GenSigSendType" SG_ 516 VCU_BcsDecelEnable 1;
BA_ "GenSigStartValue" SG_ 516 VCU_BcsDecelEnable 0;
BA_ "GenSigTimeoutValue" SG_ 516 VCU_BcsDecelEnable 0;
BA_ "Remark" SG_ 516 VCU_BcsDecelEnable "涉及ID管理表";
BA_ "EventCommandSignal" SG_ 516 VCU_CrntGearNoTrans 0;
BA_ "GatewayedSignals" SG_ 516 VCU_CrntGearNoTrans 0;
BA_ "GenSigInactiveValue" SG_ 516 VCU_CrntGearNoTrans 0;
BA_ "GenSigInvalidValue" SG_ 516 VCU_CrntGearNoTrans 0;
BA_ "GenSigSendType" SG_ 516 VCU_CrntGearNoTrans 1;
BA_ "GenSigStartValue" SG_ 516 VCU_CrntGearNoTrans 0;
BA_ "GenSigTimeoutValue" SG_ 516 VCU_CrntGearNoTrans 0;
BA_ "Remark" SG_ 516 VCU_CrntGearNoTrans "涉及ID管理表";
BA_ "EventCommandSignal" SG_ 516 VCU_EzTSt 0;
BA_ "GatewayedSignals" SG_ 516 VCU_EzTSt 0;
BA_ "GenSigInactiveValue" SG_ 516 VCU_EzTSt 0;
BA_ "GenSigInvalidValue" SG_ 516 VCU_EzTSt 0;
BA_ "GenSigSendType" SG_ 516 VCU_EzTSt 1;
BA_ "GenSigStartValue" SG_ 516 VCU_EzTSt 0;
BA_ "GenSigTimeoutValue" SG_ 516 VCU_EzTSt 0;
BA_ "Remark" SG_ 516 VCU_EzTSt "涉及ID管理表";
BA_ "EventCommandSignal" SG_ 516 VCU_ITASSt 0;
BA_ "GatewayedSignals" SG_ 516 VCU_ITASSt 0;
BA_ "GenSigInactiveValue" SG_ 516 VCU_ITASSt 0;
BA_ "GenSigInvalidValue" SG_ 516 VCU_ITASSt 0;
BA_ "GenSigSendType" SG_ 516 VCU_ITASSt 1;
BA_ "GenSigStartValue" SG_ 516 VCU_ITASSt 0;
BA_ "GenSigTimeoutValue" SG_ 516 VCU_ITASSt 0;
BA_ "Remark" SG_ 516 VCU_ITASSt "涉及ID管理表";
BA_ "EventCommandSignal" SG_ 909 LCK_HoodAjarSt 0;
BA_ "GatewayedSignals" SG_ 909 LCK_HoodAjarSt 0;
BA_ "GenSigInactiveValue" SG_ 909 LCK_HoodAjarSt 0;
BA_ "GenSigInvalidValue" SG_ 909 LCK_HoodAjarSt 0;
BA_ "GenSigSendType" SG_ 909 LCK_HoodAjarSt 0;
BA_ "GenSigStartValue" SG_ 909 LCK_HoodAjarSt 0;
BA_ "GenSigTimeoutValue" SG_ 909 LCK_HoodAjarSt 0;
BA_ "Remark" SG_ 909 LCK_HoodAjarSt "";
BA_ "EventCommandSignal" SG_ 909 LCK_FrontLeftDoorAjarSt 0;
BA_ "GatewayedSignals" SG_ 909 LCK_FrontLeftDoorAjarSt 0;
BA_ "GenSigInactiveValue" SG_ 909 LCK_FrontLeftDoorAjarSt 0;
BA_ "GenSigInvalidValue" SG_ 909 LCK_FrontLeftDoorAjarSt 0;
BA_ "GenSigSendType" SG_ 909 LCK_FrontLeftDoorAjarSt 0;
BA_ "GenSigStartValue" SG_ 909 LCK_FrontLeftDoorAjarSt 0;
BA_ "GenSigTimeoutValue" SG_ 909 LCK_FrontLeftDoorAjarSt 0;
BA_ "Remark" SG_ 909 LCK_FrontLeftDoorAjarSt "";
BA_ "EventCommandSignal" SG_ 909 LCK_FrontRightDoorAjarSt 0;
BA_ "GatewayedSignals" SG_ 909 LCK_FrontRightDoorAjarSt 0;
BA_ "GenSigInactiveValue" SG_ 909 LCK_FrontRightDoorAjarSt 0;
BA_ "GenSigInvalidValue" SG_ 909 LCK_FrontRightDoorAjarSt 0;
BA_ "GenSigSendType" SG_ 909 LCK_FrontRightDoorAjarSt 0;
BA_ "GenSigStartValue" SG_ 909 LCK_FrontRightDoorAjarSt 0;
BA_ "GenSigTimeoutValue" SG_ 909 LCK_FrontRightDoorAjarSt 0;
BA_ "Remark" SG_ 909 LCK_FrontRightDoorAjarSt "";
BA_ "EventCommandSignal" SG_ 909 LCK_RearLeftDoorAjarSt 0;
BA_ "GatewayedSignals" SG_ 909 LCK_RearLeftDoorAjarSt 0;
BA_ "GenSigInactiveValue" SG_ 909 LCK_RearLeftDoorAjarSt 0;
BA_ "GenSigInvalidValue" SG_ 909 LCK_RearLeftDoorAjarSt 0;
BA_ "GenSigSendType" SG_ 909 LCK_RearLeftDoorAjarSt 0;
BA_ "GenSigStartValue" SG_ 909 LCK_RearLeftDoorAjarSt 0;
BA_ "GenSigTimeoutValue" SG_ 909 LCK_RearLeftDoorAjarSt 0;
BA_ "Remark" SG_ 909 LCK_RearLeftDoorAjarSt "";
BA_ "EventCommandSignal" SG_ 909 LCK_RearRightDoorAjarSt 0;
BA_ "GatewayedSignals" SG_ 909 LCK_RearRightDoorAjarSt 0;
BA_ "GenSigInactiveValue" SG_ 909 LCK_RearRightDoorAjarSt 0;
BA_ "GenSigInvalidValue" SG_ 909 LCK_RearRightDoorAjarSt 0;
BA_ "GenSigSendType" SG_ 909 LCK_RearRightDoorAjarSt 0;
BA_ "GenSigStartValue" SG_ 909 LCK_RearRightDoorAjarSt 0;
BA_ "GenSigTimeoutValue" SG_ 909 LCK_RearRightDoorAjarSt 0;
BA_ "Remark" SG_ 909 LCK_RearRightDoorAjarSt "";
BA_ "EventCommandSignal" SG_ 909 LCK_TrunkAjarSt 0;
BA_ "GatewayedSignals" SG_ 909 LCK_TrunkAjarSt 0;
BA_ "GenSigInactiveValue" SG_ 909 LCK_TrunkAjarSt 0;
BA_ "GenSigInvalidValue" SG_ 909 LCK_TrunkAjarSt 0;
BA_ "GenSigSendType" SG_ 909 LCK_TrunkAjarSt 0;
BA_ "GenSigStartValue" SG_ 909 LCK_TrunkAjarSt 0;
BA_ "GenSigTimeoutValue" SG_ 909 LCK_TrunkAjarSt 0;
BA_ "Remark" SG_ 909 LCK_TrunkAjarSt "";
BA_ "EventCommandSignal" SG_ 909 LCK_FrontLeftDoorLockSt 0;
BA_ "GatewayedSignals" SG_ 909 LCK_FrontLeftDoorLockSt 0;
BA_ "GenSigInactiveValue" SG_ 909 LCK_FrontLeftDoorLockSt 0;
BA_ "GenSigInvalidValue" SG_ 909 LCK_FrontLeftDoorLockSt 0;
BA_ "GenSigSendType" SG_ 909 LCK_FrontLeftDoorLockSt 0;
BA_ "GenSigStartValue" SG_ 909 LCK_FrontLeftDoorLockSt 0;
BA_ "GenSigTimeoutValue" SG_ 909 LCK_FrontLeftDoorLockSt 0;
BA_ "Remark" SG_ 909 LCK_FrontLeftDoorLockSt "";
BA_ "EventCommandSignal" SG_ 909 LCK_FrontRightDoorLockSt 0;
BA_ "GatewayedSignals" SG_ 909 LCK_FrontRightDoorLockSt 0;
BA_ "GenSigInactiveValue" SG_ 909 LCK_FrontRightDoorLockSt 0;
BA_ "GenSigInvalidValue" SG_ 909 LCK_FrontRightDoorLockSt 0;
BA_ "GenSigSendType" SG_ 909 LCK_FrontRightDoorLockSt 0;
BA_ "GenSigStartValue" SG_ 909 LCK_FrontRightDoorLockSt 0;
BA_ "GenSigTimeoutValue" SG_ 909 LCK_FrontRightDoorLockSt 0;
BA_ "Remark" SG_ 909 LCK_FrontRightDoorLockSt "";
BA_ "EventCommandSignal" SG_ 909 LCK_RearLeftDoorLockSt 0;
BA_ "GatewayedSignals" SG_ 909 LCK_RearLeftDoorLockSt 0;
BA_ "GenSigInactiveValue" SG_ 909 LCK_RearLeftDoorLockSt 0;
BA_ "GenSigInvalidValue" SG_ 909 LCK_RearLeftDoorLockSt 0;
BA_ "GenSigSendType" SG_ 909 LCK_RearLeftDoorLockSt 0;
BA_ "GenSigStartValue" SG_ 909 LCK_RearLeftDoorLockSt 0;
BA_ "GenSigTimeoutValue" SG_ 909 LCK_RearLeftDoorLockSt 0;
BA_ "Remark" SG_ 909 LCK_RearLeftDoorLockSt "";
BA_ "EventCommandSignal" SG_ 909 LCK_RearRightDoorLockSt 0;
BA_ "GatewayedSignals" SG_ 909 LCK_RearRightDoorLockSt 0;
BA_ "GenSigInactiveValue" SG_ 909 LCK_RearRightDoorLockSt 0;
BA_ "GenSigInvalidValue" SG_ 909 LCK_RearRightDoorLockSt 0;
BA_ "GenSigSendType" SG_ 909 LCK_RearRightDoorLockSt 0;
BA_ "GenSigStartValue" SG_ 909 LCK_RearRightDoorLockSt 0;
BA_ "GenSigTimeoutValue" SG_ 909 LCK_RearRightDoorLockSt 0;
BA_ "Remark" SG_ 909 LCK_RearRightDoorLockSt "";
BA_ "EventCommandSignal" SG_ 909 LCK_RearLeftChildSaftyLockSt 0;
BA_ "GatewayedSignals" SG_ 909 LCK_RearLeftChildSaftyLockSt 0;
BA_ "GenSigInactiveValue" SG_ 909 LCK_RearLeftChildSaftyLockSt 0;
BA_ "GenSigInvalidValue" SG_ 909 LCK_RearLeftChildSaftyLockSt 0;
BA_ "GenSigSendType" SG_ 909 LCK_RearLeftChildSaftyLockSt 0;
BA_ "GenSigStartValue" SG_ 909 LCK_RearLeftChildSaftyLockSt 0;
BA_ "GenSigTimeoutValue" SG_ 909 LCK_RearLeftChildSaftyLockSt 0;
BA_ "Remark" SG_ 909 LCK_RearLeftChildSaftyLockSt "";
BA_ "EventCommandSignal" SG_ 909 LCK_RearRightChildSaftyLockSt 0;
BA_ "GatewayedSignals" SG_ 909 LCK_RearRightChildSaftyLockSt 0;
BA_ "GenSigInactiveValue" SG_ 909 LCK_RearRightChildSaftyLockSt 0;
BA_ "GenSigInvalidValue" SG_ 909 LCK_RearRightChildSaftyLockSt 0;
BA_ "GenSigSendType" SG_ 909 LCK_RearRightChildSaftyLockSt 0;
BA_ "GenSigStartValue" SG_ 909 LCK_RearRightChildSaftyLockSt 0;
BA_ "GenSigTimeoutValue" SG_ 909 LCK_RearRightChildSaftyLockSt 0;
BA_ "Remark" SG_ 909 LCK_RearRightChildSaftyLockSt "";
BA_ "EventCommandSignal" SG_ 909 EMS_EngStForPHEV 0;
BA_ "GatewayedSignals" SG_ 909 EMS_EngStForPHEV 0;
BA_ "GenSigInactiveValue" SG_ 909 EMS_EngStForPHEV 0;
BA_ "GenSigInvalidValue" SG_ 909 EMS_EngStForPHEV 0;
BA_ "GenSigSendType" SG_ 909 EMS_EngStForPHEV 1;
BA_ "GenSigStartValue" SG_ 909 EMS_EngStForPHEV 0;
BA_ "GenSigTimeoutValue" SG_ 909 EMS_EngStForPHEV 0;
BA_ "Remark" SG_ 909 EMS_EngStForPHEV "";
BA_ "EventCommandSignal" SG_ 909 WCM_Reminder 0;
BA_ "GatewayedSignals" SG_ 909 WCM_Reminder 0;
BA_ "GenSigInactiveValue" SG_ 909 WCM_Reminder 0;
BA_ "GenSigInvalidValue" SG_ 909 WCM_Reminder 0;
BA_ "GenSigSendType" SG_ 909 WCM_Reminder 1;
BA_ "GenSigStartValue" SG_ 909 WCM_Reminder 0;
BA_ "GenSigTimeoutValue" SG_ 909 WCM_Reminder 0;
BA_ "Remark" SG_ 909 WCM_Reminder "";
BA_ "EventCommandSignal" SG_ 909 WCM_ChargingSt 0;
BA_ "GatewayedSignals" SG_ 909 WCM_ChargingSt 0;
BA_ "GenSigInactiveValue" SG_ 909 WCM_ChargingSt 0;
BA_ "GenSigInvalidValue" SG_ 909 WCM_ChargingSt 0;
BA_ "GenSigSendType" SG_ 909 WCM_ChargingSt 1;
BA_ "GenSigStartValue" SG_ 909 WCM_ChargingSt 0;
BA_ "GenSigTimeoutValue" SG_ 909 WCM_ChargingSt 0;
BA_ "Remark" SG_ 909 WCM_ChargingSt "";
BA_ "EventCommandSignal" SG_ 909 LCK_FrontLeftDoorHandlePosition 0;
BA_ "GatewayedSignals" SG_ 909 LCK_FrontLeftDoorHandlePosition 0;
BA_ "GenSigInactiveValue" SG_ 909 LCK_FrontLeftDoorHandlePosition 0;
BA_ "GenSigInvalidValue" SG_ 909 LCK_FrontLeftDoorHandlePosition 255;
BA_ "GenSigSendType" SG_ 909 LCK_FrontLeftDoorHandlePosition 0;
BA_ "GenSigStartValue" SG_ 909 LCK_FrontLeftDoorHandlePosition 0;
BA_ "GenSigTimeoutValue" SG_ 909 LCK_FrontLeftDoorHandlePosition 0;
BA_ "Remark" SG_ 909 LCK_FrontLeftDoorHandlePosition "";
BA_ "EventCommandSignal" SG_ 909 LCK_FrontRightDoorHandlePosition 0;
BA_ "GatewayedSignals" SG_ 909 LCK_FrontRightDoorHandlePosition 0;
BA_ "GenSigInactiveValue" SG_ 909 LCK_FrontRightDoorHandlePosition 0;
BA_ "GenSigInvalidValue" SG_ 909 LCK_FrontRightDoorHandlePosition 255;
BA_ "GenSigSendType" SG_ 909 LCK_FrontRightDoorHandlePosition 0;
BA_ "GenSigStartValue" SG_ 909 LCK_FrontRightDoorHandlePosition 0;
BA_ "GenSigTimeoutValue" SG_ 909 LCK_FrontRightDoorHandlePosition 0;
BA_ "Remark" SG_ 909 LCK_FrontRightDoorHandlePosition "";
BA_ "EventCommandSignal" SG_ 909 LCK_RearLeftDoorHandlePosition 0;
BA_ "GatewayedSignals" SG_ 909 LCK_RearLeftDoorHandlePosition 0;
BA_ "GenSigInactiveValue" SG_ 909 LCK_RearLeftDoorHandlePosition 0;
BA_ "GenSigInvalidValue" SG_ 909 LCK_RearLeftDoorHandlePosition 255;
BA_ "GenSigSendType" SG_ 909 LCK_RearLeftDoorHandlePosition 0;
BA_ "GenSigStartValue" SG_ 909 LCK_RearLeftDoorHandlePosition 0;
BA_ "GenSigTimeoutValue" SG_ 909 LCK_RearLeftDoorHandlePosition 0;
BA_ "Remark" SG_ 909 LCK_RearLeftDoorHandlePosition "";
BA_ "EventCommandSignal" SG_ 909 LCK_RearRightDoorHandlePosition 0;
BA_ "GatewayedSignals" SG_ 909 LCK_RearRightDoorHandlePosition 0;
BA_ "GenSigInactiveValue" SG_ 909 LCK_RearRightDoorHandlePosition 0;
BA_ "GenSigInvalidValue" SG_ 909 LCK_RearRightDoorHandlePosition 255;
BA_ "GenSigSendType" SG_ 909 LCK_RearRightDoorHandlePosition 0;
BA_ "GenSigStartValue" SG_ 909 LCK_RearRightDoorHandlePosition 0;
BA_ "GenSigTimeoutValue" SG_ 909 LCK_RearRightDoorHandlePosition 0;
BA_ "Remark" SG_ 909 LCK_RearRightDoorHandlePosition "";
BA_ "EventCommandSignal" SG_ 909 WW_RWPMotorSt 0;
BA_ "GatewayedSignals" SG_ 909 WW_RWPMotorSt 0;
BA_ "GenSigInactiveValue" SG_ 909 WW_RWPMotorSt 0;
BA_ "GenSigInvalidValue" SG_ 909 WW_RWPMotorSt 0;
BA_ "GenSigSendType" SG_ 909 WW_RWPMotorSt 1;
BA_ "GenSigStartValue" SG_ 909 WW_RWPMotorSt 0;
BA_ "GenSigTimeoutValue" SG_ 909 WW_RWPMotorSt 0;
BA_ "Remark" SG_ 909 WW_RWPMotorSt "";
BA_ "EventCommandSignal" SG_ 909 LCK_FillerCapASt 0;
BA_ "GatewayedSignals" SG_ 909 LCK_FillerCapASt 0;
BA_ "GenSigInactiveValue" SG_ 909 LCK_FillerCapASt 0;
BA_ "GenSigInvalidValue" SG_ 909 LCK_FillerCapASt 0;
BA_ "GenSigSendType" SG_ 909 LCK_FillerCapASt 0;
BA_ "GenSigStartValue" SG_ 909 LCK_FillerCapASt 0;
BA_ "GenSigTimeoutValue" SG_ 909 LCK_FillerCapASt 0;
BA_ "Remark" SG_ 909 LCK_FillerCapASt "";
BA_ "EventCommandSignal" SG_ 909 LCK_FillerCapBSt 0;
BA_ "GatewayedSignals" SG_ 909 LCK_FillerCapBSt 0;
BA_ "GenSigInactiveValue" SG_ 909 LCK_FillerCapBSt 0;
BA_ "GenSigInvalidValue" SG_ 909 LCK_FillerCapBSt 0;
BA_ "GenSigSendType" SG_ 909 LCK_FillerCapBSt 0;
BA_ "GenSigStartValue" SG_ 909 LCK_FillerCapBSt 0;
BA_ "GenSigTimeoutValue" SG_ 909 LCK_FillerCapBSt 0;
BA_ "Remark" SG_ 909 LCK_FillerCapBSt "";
BA_ "EventCommandSignal" SG_ 909 MR_LeftMirrorFoldUnfoldSt 0;
BA_ "GatewayedSignals" SG_ 909 MR_LeftMirrorFoldUnfoldSt 0;
BA_ "GenSigInactiveValue" SG_ 909 MR_LeftMirrorFoldUnfoldSt 0;
BA_ "GenSigInvalidValue" SG_ 909 MR_LeftMirrorFoldUnfoldSt 0;
BA_ "GenSigSendType" SG_ 909 MR_LeftMirrorFoldUnfoldSt 1;
BA_ "GenSigStartValue" SG_ 909 MR_LeftMirrorFoldUnfoldSt 0;
BA_ "GenSigTimeoutValue" SG_ 909 MR_LeftMirrorFoldUnfoldSt 0;
BA_ "Remark" SG_ 909 MR_LeftMirrorFoldUnfoldSt "";
BA_ "EventCommandSignal" SG_ 909 SBM_SwapHvBattModeSt 0;
BA_ "GatewayedSignals" SG_ 909 SBM_SwapHvBattModeSt 0;
BA_ "GenSigInactiveValue" SG_ 909 SBM_SwapHvBattModeSt 0;
BA_ "GenSigInvalidValue" SG_ 909 SBM_SwapHvBattModeSt 0;
BA_ "GenSigSendType" SG_ 909 SBM_SwapHvBattModeSt 1;
BA_ "GenSigStartValue" SG_ 909 SBM_SwapHvBattModeSt 0;
BA_ "GenSigTimeoutValue" SG_ 909 SBM_SwapHvBattModeSt 0;
BA_ "Remark" SG_ 909 SBM_SwapHvBattModeSt "";
BA_ "EventCommandSignal" SG_ 909 SBM_SwapStaDiagCode 0;
BA_ "GatewayedSignals" SG_ 909 SBM_SwapStaDiagCode 0;
BA_ "GenSigInactiveValue" SG_ 909 SBM_SwapStaDiagCode 0;
BA_ "GenSigInvalidValue" SG_ 909 SBM_SwapStaDiagCode 0;
BA_ "GenSigSendType" SG_ 909 SBM_SwapStaDiagCode 1;
BA_ "GenSigStartValue" SG_ 909 SBM_SwapStaDiagCode 0;
BA_ "GenSigTimeoutValue" SG_ 909 SBM_SwapStaDiagCode 0;
BA_ "Remark" SG_ 909 SBM_SwapStaDiagCode "";
BA_ "EventCommandSignal" SG_ 909 SBM_SwapVehDiagCode 0;
BA_ "GatewayedSignals" SG_ 909 SBM_SwapVehDiagCode 0;
BA_ "GenSigInactiveValue" SG_ 909 SBM_SwapVehDiagCode 0;
BA_ "GenSigInvalidValue" SG_ 909 SBM_SwapVehDiagCode 0;
BA_ "GenSigSendType" SG_ 909 SBM_SwapVehDiagCode 1;
BA_ "GenSigStartValue" SG_ 909 SBM_SwapVehDiagCode 0;
BA_ "GenSigTimeoutValue" SG_ 909 SBM_SwapVehDiagCode 0;
BA_ "Remark" SG_ 909 SBM_SwapVehDiagCode "";
BA_ "EventCommandSignal" SG_ 909 SBM_SwapHvBattModeFaultSt 0;
BA_ "GatewayedSignals" SG_ 909 SBM_SwapHvBattModeFaultSt 0;
BA_ "GenSigInactiveValue" SG_ 909 SBM_SwapHvBattModeFaultSt 0;
BA_ "GenSigInvalidValue" SG_ 909 SBM_SwapHvBattModeFaultSt 0;
BA_ "GenSigSendType" SG_ 909 SBM_SwapHvBattModeFaultSt 1;
BA_ "GenSigStartValue" SG_ 909 SBM_SwapHvBattModeFaultSt 0;
BA_ "GenSigTimeoutValue" SG_ 909 SBM_SwapHvBattModeFaultSt 0;
BA_ "Remark" SG_ 909 SBM_SwapHvBattModeFaultSt "";
BA_ "EventCommandSignal" SG_ 909 IPDS_HDMapPowerSt 0;
BA_ "GatewayedSignals" SG_ 909 IPDS_HDMapPowerSt 0;
BA_ "GenSigInactiveValue" SG_ 909 IPDS_HDMapPowerSt 0;
BA_ "GenSigInvalidValue" SG_ 909 IPDS_HDMapPowerSt 0;
BA_ "GenSigSendType" SG_ 909 IPDS_HDMapPowerSt 1;
BA_ "GenSigStartValue" SG_ 909 IPDS_HDMapPowerSt 0;
BA_ "GenSigTimeoutValue" SG_ 909 IPDS_HDMapPowerSt 0;
BA_ "Remark" SG_ 909 IPDS_HDMapPowerSt "";
BA_ "EventCommandSignal" SG_ 909 IPDS_KL15L1PowerSt 0;
BA_ "GatewayedSignals" SG_ 909 IPDS_KL15L1PowerSt 0;
BA_ "GenSigInactiveValue" SG_ 909 IPDS_KL15L1PowerSt 0;
BA_ "GenSigInvalidValue" SG_ 909 IPDS_KL15L1PowerSt 0;
BA_ "GenSigSendType" SG_ 909 IPDS_KL15L1PowerSt 1;
BA_ "GenSigStartValue" SG_ 909 IPDS_KL15L1PowerSt 0;
BA_ "GenSigTimeoutValue" SG_ 909 IPDS_KL15L1PowerSt 0;
BA_ "Remark" SG_ 909 IPDS_KL15L1PowerSt "";
BA_ "EventCommandSignal" SG_ 909 IPDS_SRSECUPowerSt 0;
BA_ "GatewayedSignals" SG_ 909 IPDS_SRSECUPowerSt 0;
BA_ "GenSigInactiveValue" SG_ 909 IPDS_SRSECUPowerSt 0;
BA_ "GenSigInvalidValue" SG_ 909 IPDS_SRSECUPowerSt 0;
BA_ "GenSigSendType" SG_ 909 IPDS_SRSECUPowerSt 1;
BA_ "GenSigStartValue" SG_ 909 IPDS_SRSECUPowerSt 0;
BA_ "GenSigTimeoutValue" SG_ 909 IPDS_SRSECUPowerSt 0;
BA_ "Remark" SG_ 909 IPDS_SRSECUPowerSt "";
BA_ "EventCommandSignal" SG_ 909 IPDS_HODPowerSt 0;
BA_ "GatewayedSignals" SG_ 909 IPDS_HODPowerSt 0;
BA_ "GenSigInactiveValue" SG_ 909 IPDS_HODPowerSt 0;
BA_ "GenSigInvalidValue" SG_ 909 IPDS_HODPowerSt 0;
BA_ "GenSigSendType" SG_ 909 IPDS_HODPowerSt 1;
BA_ "GenSigStartValue" SG_ 909 IPDS_HODPowerSt 0;
BA_ "GenSigTimeoutValue" SG_ 909 IPDS_HODPowerSt 0;
BA_ "Remark" SG_ 909 IPDS_HODPowerSt "";
BA_ "EventCommandSignal" SG_ 909 KAE_BLEOption 0;
BA_ "GatewayedSignals" SG_ 909 KAE_BLEOption 0;
BA_ "GenSigInactiveValue" SG_ 909 KAE_BLEOption 0;
BA_ "GenSigInvalidValue" SG_ 909 KAE_BLEOption 0;
BA_ "GenSigSendType" SG_ 909 KAE_BLEOption 1;
BA_ "GenSigStartValue" SG_ 909 KAE_BLEOption 0;
BA_ "GenSigTimeoutValue" SG_ 909 KAE_BLEOption 0;
BA_ "Remark" SG_ 909 KAE_BLEOption "";
BA_ "EventCommandSignal" SG_ 909 KAE_UWBOption 0;
BA_ "GatewayedSignals" SG_ 909 KAE_UWBOption 0;
BA_ "GenSigInactiveValue" SG_ 909 KAE_UWBOption 0;
BA_ "GenSigInvalidValue" SG_ 909 KAE_UWBOption 0;
BA_ "GenSigSendType" SG_ 909 KAE_UWBOption 1;
BA_ "GenSigStartValue" SG_ 909 KAE_UWBOption 0;
BA_ "GenSigTimeoutValue" SG_ 909 KAE_UWBOption 0;
BA_ "Remark" SG_ 909 KAE_UWBOption "";
BA_ "EventCommandSignal" SG_ 909 PWL_WinCurrentPos_FLWinPst 0;
BA_ "GatewayedSignals" SG_ 909 PWL_WinCurrentPos_FLWinPst 0;
BA_ "GenSigInactiveValue" SG_ 909 PWL_WinCurrentPos_FLWinPst 0;
BA_ "GenSigInvalidValue" SG_ 909 PWL_WinCurrentPos_FLWinPst 0;
BA_ "GenSigSendType" SG_ 909 PWL_WinCurrentPos_FLWinPst 1;
BA_ "GenSigStartValue" SG_ 909 PWL_WinCurrentPos_FLWinPst 255;
BA_ "GenSigTimeoutValue" SG_ 909 PWL_WinCurrentPos_FLWinPst 0;
BA_ "Remark" SG_ 909 PWL_WinCurrentPos_FLWinPst "";
BA_ "EventCommandSignal" SG_ 909 UINM_FrontLeftPowerReleaseReq 0;
BA_ "GatewayedSignals" SG_ 909 UINM_FrontLeftPowerReleaseReq 0;
BA_ "GenSigInactiveValue" SG_ 909 UINM_FrontLeftPowerReleaseReq 0;
BA_ "GenSigInvalidValue" SG_ 909 UINM_FrontLeftPowerReleaseReq 0;
BA_ "GenSigSendType" SG_ 909 UINM_FrontLeftPowerReleaseReq 1;
BA_ "GenSigStartValue" SG_ 909 UINM_FrontLeftPowerReleaseReq 0;
BA_ "GenSigTimeoutValue" SG_ 909 UINM_FrontLeftPowerReleaseReq 0;
BA_ "Remark" SG_ 909 UINM_FrontLeftPowerReleaseReq "";
BA_ "EventCommandSignal" SG_ 909 UINM_FrontLeftPowerReleaseFaultSt 0;
BA_ "GatewayedSignals" SG_ 909 UINM_FrontLeftPowerReleaseFaultSt 0;
BA_ "GenSigInactiveValue" SG_ 909 UINM_FrontLeftPowerReleaseFaultSt 0;
BA_ "GenSigInvalidValue" SG_ 909 UINM_FrontLeftPowerReleaseFaultSt 0;
BA_ "GenSigSendType" SG_ 909 UINM_FrontLeftPowerReleaseFaultSt 1;
BA_ "GenSigStartValue" SG_ 909 UINM_FrontLeftPowerReleaseFaultSt 0;
BA_ "GenSigTimeoutValue" SG_ 909 UINM_FrontLeftPowerReleaseFaultSt 0;
BA_ "Remark" SG_ 909 UINM_FrontLeftPowerReleaseFaultSt "";
BA_ "EventCommandSignal" SG_ 909 UINM_FrontRightPowerReleaseReq 0;
BA_ "GatewayedSignals" SG_ 909 UINM_FrontRightPowerReleaseReq 0;
BA_ "GenSigInactiveValue" SG_ 909 UINM_FrontRightPowerReleaseReq 0;
BA_ "GenSigInvalidValue" SG_ 909 UINM_FrontRightPowerReleaseReq 0;
BA_ "GenSigSendType" SG_ 909 UINM_FrontRightPowerReleaseReq 1;
BA_ "GenSigStartValue" SG_ 909 UINM_FrontRightPowerReleaseReq 0;
BA_ "GenSigTimeoutValue" SG_ 909 UINM_FrontRightPowerReleaseReq 0;
BA_ "Remark" SG_ 909 UINM_FrontRightPowerReleaseReq "";
BA_ "EventCommandSignal" SG_ 909 UINM_FrontRightPowerReleaseFaultSt 0;
BA_ "GatewayedSignals" SG_ 909 UINM_FrontRightPowerReleaseFaultSt 0;
BA_ "GenSigInactiveValue" SG_ 909 UINM_FrontRightPowerReleaseFaultSt 0;
BA_ "GenSigInvalidValue" SG_ 909 UINM_FrontRightPowerReleaseFaultSt 0;
BA_ "GenSigSendType" SG_ 909 UINM_FrontRightPowerReleaseFaultSt 1;
BA_ "GenSigStartValue" SG_ 909 UINM_FrontRightPowerReleaseFaultSt 0;
BA_ "GenSigTimeoutValue" SG_ 909 UINM_FrontRightPowerReleaseFaultSt 0;
BA_ "Remark" SG_ 909 UINM_FrontRightPowerReleaseFaultSt "";
BA_ "EventCommandSignal" SG_ 909 UINM_RearLeftPowerReleaseFaultSt 0;
BA_ "GatewayedSignals" SG_ 909 UINM_RearLeftPowerReleaseFaultSt 0;
BA_ "GenSigInactiveValue" SG_ 909 UINM_RearLeftPowerReleaseFaultSt 0;
BA_ "GenSigInvalidValue" SG_ 909 UINM_RearLeftPowerReleaseFaultSt 0;
BA_ "GenSigSendType" SG_ 909 UINM_RearLeftPowerReleaseFaultSt 1;
BA_ "GenSigStartValue" SG_ 909 UINM_RearLeftPowerReleaseFaultSt 0;
BA_ "GenSigTimeoutValue" SG_ 909 UINM_RearLeftPowerReleaseFaultSt 0;
BA_ "Remark" SG_ 909 UINM_RearLeftPowerReleaseFaultSt "";
BA_ "EventCommandSignal" SG_ 909 UINM_RearLeftPowerReleaseReq 0;
BA_ "GatewayedSignals" SG_ 909 UINM_RearLeftPowerReleaseReq 0;
BA_ "GenSigInactiveValue" SG_ 909 UINM_RearLeftPowerReleaseReq 0;
BA_ "GenSigInvalidValue" SG_ 909 UINM_RearLeftPowerReleaseReq 0;
BA_ "GenSigSendType" SG_ 909 UINM_RearLeftPowerReleaseReq 1;
BA_ "GenSigStartValue" SG_ 909 UINM_RearLeftPowerReleaseReq 0;
BA_ "GenSigTimeoutValue" SG_ 909 UINM_RearLeftPowerReleaseReq 0;
BA_ "Remark" SG_ 909 UINM_RearLeftPowerReleaseReq "";
BA_ "EventCommandSignal" SG_ 909 UINM_RearRightPowerReleaseFaultSt 0;
BA_ "GatewayedSignals" SG_ 909 UINM_RearRightPowerReleaseFaultSt 0;
BA_ "GenSigInactiveValue" SG_ 909 UINM_RearRightPowerReleaseFaultSt 0;
BA_ "GenSigInvalidValue" SG_ 909 UINM_RearRightPowerReleaseFaultSt 0;
BA_ "GenSigSendType" SG_ 909 UINM_RearRightPowerReleaseFaultSt 1;
BA_ "GenSigStartValue" SG_ 909 UINM_RearRightPowerReleaseFaultSt 0;
BA_ "GenSigTimeoutValue" SG_ 909 UINM_RearRightPowerReleaseFaultSt 0;
BA_ "Remark" SG_ 909 UINM_RearRightPowerReleaseFaultSt "";
BA_ "EventCommandSignal" SG_ 909 UINM_RearRightPowerReleaseReq 0;
BA_ "GatewayedSignals" SG_ 909 UINM_RearRightPowerReleaseReq 0;
BA_ "GenSigInactiveValue" SG_ 909 UINM_RearRightPowerReleaseReq 0;
BA_ "GenSigInvalidValue" SG_ 909 UINM_RearRightPowerReleaseReq 0;
BA_ "GenSigSendType" SG_ 909 UINM_RearRightPowerReleaseReq 1;
BA_ "GenSigStartValue" SG_ 909 UINM_RearRightPowerReleaseReq 0;
BA_ "GenSigTimeoutValue" SG_ 909 UINM_RearRightPowerReleaseReq 0;
BA_ "Remark" SG_ 909 UINM_RearRightPowerReleaseReq "";
BA_ "EventCommandSignal" SG_ 909 BMS_BattSOCAccurate 0;
BA_ "GatewayedSignals" SG_ 909 BMS_BattSOCAccurate 0;
BA_ "GenSigInactiveValue" SG_ 909 BMS_BattSOCAccurate 0;
BA_ "GenSigInvalidValue" SG_ 909 BMS_BattSOCAccurate 0;
BA_ "GenSigSendType" SG_ 909 BMS_BattSOCAccurate 1;
BA_ "GenSigStartValue" SG_ 909 BMS_BattSOCAccurate 5550;
BA_ "GenSigTimeoutValue" SG_ 909 BMS_BattSOCAccurate 0;
BA_ "Remark" SG_ 909 BMS_BattSOCAccurate "";
BA_ "EventCommandSignal" SG_ 909 PWL_WinCurrentPos_RRWinPst 0;
BA_ "GatewayedSignals" SG_ 909 PWL_WinCurrentPos_RRWinPst 0;
BA_ "GenSigInactiveValue" SG_ 909 PWL_WinCurrentPos_RRWinPst 0;
BA_ "GenSigInvalidValue" SG_ 909 PWL_WinCurrentPos_RRWinPst 0;
BA_ "GenSigSendType" SG_ 909 PWL_WinCurrentPos_RRWinPst 1;
BA_ "GenSigStartValue" SG_ 909 PWL_WinCurrentPos_RRWinPst 255;
BA_ "GenSigTimeoutValue" SG_ 909 PWL_WinCurrentPos_RRWinPst 0;
BA_ "Remark" SG_ 909 PWL_WinCurrentPos_RRWinPst "";
BA_ "EventCommandSignal" SG_ 909 PWL_WinCurrentPos_RLWinPst 0;
BA_ "GatewayedSignals" SG_ 909 PWL_WinCurrentPos_RLWinPst 0;
BA_ "GenSigInactiveValue" SG_ 909 PWL_WinCurrentPos_RLWinPst 0;
BA_ "GenSigInvalidValue" SG_ 909 PWL_WinCurrentPos_RLWinPst 0;
BA_ "GenSigSendType" SG_ 909 PWL_WinCurrentPos_RLWinPst 1;
BA_ "GenSigStartValue" SG_ 909 PWL_WinCurrentPos_RLWinPst 255;
BA_ "GenSigTimeoutValue" SG_ 909 PWL_WinCurrentPos_RLWinPst 0;
BA_ "Remark" SG_ 909 PWL_WinCurrentPos_RLWinPst "";
BA_ "EventCommandSignal" SG_ 909 ACEleclocksSt 0;
BA_ "GatewayedSignals" SG_ 909 ACEleclocksSt 0;
BA_ "GenSigInactiveValue" SG_ 909 ACEleclocksSt 0;
BA_ "GenSigInvalidValue" SG_ 909 ACEleclocksSt 0;
BA_ "GenSigSendType" SG_ 909 ACEleclocksSt 1;
BA_ "GenSigStartValue" SG_ 909 ACEleclocksSt 0;
BA_ "GenSigTimeoutValue" SG_ 909 ACEleclocksSt 0;
BA_ "Remark" SG_ 909 ACEleclocksSt "";
BA_ "EventCommandSignal" SG_ 909 DSASBM_MotResp 0;
BA_ "GatewayedSignals" SG_ 909 DSASBM_MotResp 0;
BA_ "GenSigInactiveValue" SG_ 909 DSASBM_MotResp 0;
BA_ "GenSigInvalidValue" SG_ 909 DSASBM_MotResp 0;
BA_ "GenSigSendType" SG_ 909 DSASBM_MotResp 1;
BA_ "GenSigStartValue" SG_ 909 DSASBM_MotResp 0;
BA_ "GenSigTimeoutValue" SG_ 909 DSASBM_MotResp 0;
BA_ "Remark" SG_ 909 DSASBM_MotResp "";
BA_ "EventCommandSignal" SG_ 792 UMM_SecondRHSeatSt 0;
BA_ "GatewayedSignals" SG_ 792 UMM_SecondRHSeatSt 0;
BA_ "GenSigInactiveValue" SG_ 792 UMM_SecondRHSeatSt 0;
BA_ "GenSigInvalidValue" SG_ 792 UMM_SecondRHSeatSt 0;
BA_ "GenSigSendType" SG_ 792 UMM_SecondRHSeatSt 1;
BA_ "GenSigStartValue" SG_ 792 UMM_SecondRHSeatSt 0;
BA_ "GenSigTimeoutValue" SG_ 792 UMM_SecondRHSeatSt 0;
BA_ "Remark" SG_ 792 UMM_SecondRHSeatSt "";
BA_ "EventCommandSignal" SG_ 792 UMM_SecondLHSeatSt 0;
BA_ "GatewayedSignals" SG_ 792 UMM_SecondLHSeatSt 0;
BA_ "GenSigInactiveValue" SG_ 792 UMM_SecondLHSeatSt 0;
BA_ "GenSigInvalidValue" SG_ 792 UMM_SecondLHSeatSt 0;
BA_ "GenSigSendType" SG_ 792 UMM_SecondLHSeatSt 1;
BA_ "GenSigStartValue" SG_ 792 UMM_SecondLHSeatSt 0;
BA_ "GenSigTimeoutValue" SG_ 792 UMM_SecondLHSeatSt 0;
BA_ "Remark" SG_ 792 UMM_SecondLHSeatSt "";
BA_ "EventCommandSignal" SG_ 792 LCK_PowerFillerCapAngle 0;
BA_ "GatewayedSignals" SG_ 792 LCK_PowerFillerCapAngle 0;
BA_ "GenSigInactiveValue" SG_ 792 LCK_PowerFillerCapAngle 0;
BA_ "GenSigInvalidValue" SG_ 792 LCK_PowerFillerCapAngle 0;
BA_ "GenSigSendType" SG_ 792 LCK_PowerFillerCapAngle 1;
BA_ "GenSigStartValue" SG_ 792 LCK_PowerFillerCapAngle 0;
BA_ "GenSigTimeoutValue" SG_ 792 LCK_PowerFillerCapAngle 0;
BA_ "Remark" SG_ 792 LCK_PowerFillerCapAngle "";
BA_ "EventCommandSignal" SG_ 792 EL_ReverseLightSt 0;
BA_ "GatewayedSignals" SG_ 792 EL_ReverseLightSt 0;
BA_ "GenSigInactiveValue" SG_ 792 EL_ReverseLightSt 0;
BA_ "GenSigInvalidValue" SG_ 792 EL_ReverseLightSt 0;
BA_ "GenSigSendType" SG_ 792 EL_ReverseLightSt 1;
BA_ "GenSigStartValue" SG_ 792 EL_ReverseLightSt 0;
BA_ "GenSigTimeoutValue" SG_ 792 EL_ReverseLightSt 0;
BA_ "Remark" SG_ 792 EL_ReverseLightSt "";
BA_ "EventCommandSignal" SG_ 792 EL_ReverseLightFaultSt 0;
BA_ "GatewayedSignals" SG_ 792 EL_ReverseLightFaultSt 0;
BA_ "GenSigInactiveValue" SG_ 792 EL_ReverseLightFaultSt 0;
BA_ "GenSigInvalidValue" SG_ 792 EL_ReverseLightFaultSt 0;
BA_ "GenSigSendType" SG_ 792 EL_ReverseLightFaultSt 1;
BA_ "GenSigStartValue" SG_ 792 EL_ReverseLightFaultSt 0;
BA_ "GenSigTimeoutValue" SG_ 792 EL_ReverseLightFaultSt 0;
BA_ "Remark" SG_ 792 EL_ReverseLightFaultSt "";
BA_ "EventCommandSignal" SG_ 792 EL_RLPositionLightSt 0;
BA_ "GatewayedSignals" SG_ 792 EL_RLPositionLightSt 0;
BA_ "GenSigInactiveValue" SG_ 792 EL_RLPositionLightSt 0;
BA_ "GenSigInvalidValue" SG_ 792 EL_RLPositionLightSt 0;
BA_ "GenSigSendType" SG_ 792 EL_RLPositionLightSt 1;
BA_ "GenSigStartValue" SG_ 792 EL_RLPositionLightSt 0;
BA_ "GenSigTimeoutValue" SG_ 792 EL_RLPositionLightSt 0;
BA_ "Remark" SG_ 792 EL_RLPositionLightSt "";
BA_ "EventCommandSignal" SG_ 792 EL_RLPositionLightFaultSt 0;
BA_ "GatewayedSignals" SG_ 792 EL_RLPositionLightFaultSt 0;
BA_ "GenSigInactiveValue" SG_ 792 EL_RLPositionLightFaultSt 0;
BA_ "GenSigInvalidValue" SG_ 792 EL_RLPositionLightFaultSt 0;
BA_ "GenSigSendType" SG_ 792 EL_RLPositionLightFaultSt 1;
BA_ "GenSigStartValue" SG_ 792 EL_RLPositionLightFaultSt 0;
BA_ "GenSigTimeoutValue" SG_ 792 EL_RLPositionLightFaultSt 0;
BA_ "Remark" SG_ 792 EL_RLPositionLightFaultSt "";
BA_ "EventCommandSignal" SG_ 792 EL_RRPositionLightSt 0;
BA_ "GatewayedSignals" SG_ 792 EL_RRPositionLightSt 0;
BA_ "GenSigInactiveValue" SG_ 792 EL_RRPositionLightSt 0;
BA_ "GenSigInvalidValue" SG_ 792 EL_RRPositionLightSt 0;
BA_ "GenSigSendType" SG_ 792 EL_RRPositionLightSt 1;
BA_ "GenSigStartValue" SG_ 792 EL_RRPositionLightSt 0;
BA_ "GenSigTimeoutValue" SG_ 792 EL_RRPositionLightSt 0;
BA_ "Remark" SG_ 792 EL_RRPositionLightSt "";
BA_ "EventCommandSignal" SG_ 792 EL_RRPositionLightFaultSt 0;
BA_ "GatewayedSignals" SG_ 792 EL_RRPositionLightFaultSt 0;
BA_ "GenSigInactiveValue" SG_ 792 EL_RRPositionLightFaultSt 0;
BA_ "GenSigInvalidValue" SG_ 792 EL_RRPositionLightFaultSt 0;
BA_ "GenSigSendType" SG_ 792 EL_RRPositionLightFaultSt 1;
BA_ "GenSigStartValue" SG_ 792 EL_RRPositionLightFaultSt 0;
BA_ "GenSigTimeoutValue" SG_ 792 EL_RRPositionLightFaultSt 0;
BA_ "Remark" SG_ 792 EL_RRPositionLightFaultSt "";
BA_ "EventCommandSignal" SG_ 792 EL_RearFogLightSt 0;
BA_ "GatewayedSignals" SG_ 792 EL_RearFogLightSt 0;
BA_ "GenSigInactiveValue" SG_ 792 EL_RearFogLightSt 0;
BA_ "GenSigInvalidValue" SG_ 792 EL_RearFogLightSt 0;
BA_ "GenSigSendType" SG_ 792 EL_RearFogLightSt 1;
BA_ "GenSigStartValue" SG_ 792 EL_RearFogLightSt 0;
BA_ "GenSigTimeoutValue" SG_ 792 EL_RearFogLightSt 0;
BA_ "Remark" SG_ 792 EL_RearFogLightSt "";
BA_ "EventCommandSignal" SG_ 792 EL_RearFogLightFaultSt 0;
BA_ "GatewayedSignals" SG_ 792 EL_RearFogLightFaultSt 0;
BA_ "GenSigInactiveValue" SG_ 792 EL_RearFogLightFaultSt 0;
BA_ "GenSigInvalidValue" SG_ 792 EL_RearFogLightFaultSt 0;
BA_ "GenSigSendType" SG_ 792 EL_RearFogLightFaultSt 1;
BA_ "GenSigStartValue" SG_ 792 EL_RearFogLightFaultSt 0;
BA_ "GenSigTimeoutValue" SG_ 792 EL_RearFogLightFaultSt 0;
BA_ "Remark" SG_ 792 EL_RearFogLightFaultSt "";
BA_ "EventCommandSignal" SG_ 860 VCU_7_CRC 0;
BA_ "GatewayedSignals" SG_ 860 VCU_7_CRC 0;
BA_ "GenSigInactiveValue" SG_ 860 VCU_7_CRC 0;
BA_ "GenSigInvalidValue" SG_ 860 VCU_7_CRC 0;
BA_ "GenSigSendType" SG_ 860 VCU_7_CRC 1;
BA_ "GenSigStartValue" SG_ 860 VCU_7_CRC 0;
BA_ "GenSigTimeoutValue" SG_ 860 VCU_7_CRC 0;
BA_ "Remark" SG_ 860 VCU_7_CRC "涉及ID管理表";
BA_ "EventCommandSignal" SG_ 860 VCU_7_Counter 0;
BA_ "GatewayedSignals" SG_ 860 VCU_7_Counter 0;
BA_ "GenSigInactiveValue" SG_ 860 VCU_7_Counter 0;
BA_ "GenSigInvalidValue" SG_ 860 VCU_7_Counter 0;
BA_ "GenSigSendType" SG_ 860 VCU_7_Counter 1;
BA_ "GenSigStartValue" SG_ 860 VCU_7_Counter 0;
BA_ "GenSigTimeoutValue" SG_ 860 VCU_7_Counter 0;
BA_ "Remark" SG_ 860 VCU_7_Counter "涉及ID管理表";
BA_ "EventCommandSignal" SG_ 860 VCU_RoadMod 0;
BA_ "GatewayedSignals" SG_ 860 VCU_RoadMod 0;
BA_ "GenSigInactiveValue" SG_ 860 VCU_RoadMod 0;
BA_ "GenSigInvalidValue" SG_ 860 VCU_RoadMod 0;
BA_ "GenSigSendType" SG_ 860 VCU_RoadMod 1;
BA_ "GenSigStartValue" SG_ 860 VCU_RoadMod 0;
BA_ "GenSigTimeoutValue" SG_ 860 VCU_RoadMod 0;
BA_ "Remark" SG_ 860 VCU_RoadMod "涉及ID管理表";
BA_ "EventCommandSignal" SG_ 860 VCU_GearLvl 0;
BA_ "GatewayedSignals" SG_ 860 VCU_GearLvl 0;
BA_ "GenSigInactiveValue" SG_ 860 VCU_GearLvl 0;
BA_ "GenSigInvalidValue" SG_ 860 VCU_GearLvl 0;
BA_ "GenSigSendType" SG_ 860 VCU_GearLvl 1;
BA_ "GenSigStartValue" SG_ 860 VCU_GearLvl 0;
BA_ "GenSigTimeoutValue" SG_ 860 VCU_GearLvl 0;
BA_ "Remark" SG_ 860 VCU_GearLvl "涉及ID管理表";
BA_ "EventCommandSignal" SG_ 860 VCU_VehDrvMod 0;
BA_ "GatewayedSignals" SG_ 860 VCU_VehDrvMod 0;
BA_ "GenSigInactiveValue" SG_ 860 VCU_VehDrvMod 0;
BA_ "GenSigInvalidValue" SG_ 860 VCU_VehDrvMod 0;
BA_ "GenSigSendType" SG_ 860 VCU_VehDrvMod 1;
BA_ "GenSigStartValue" SG_ 860 VCU_VehDrvMod 0;
BA_ "GenSigTimeoutValue" SG_ 860 VCU_VehDrvMod 0;
BA_ "Remark" SG_ 860 VCU_VehDrvMod "涉及ID管理表";
BA_ "EventCommandSignal" SG_ 860 VCU_VehRdySt 0;
BA_ "GatewayedSignals" SG_ 860 VCU_VehRdySt 0;
BA_ "GenSigInactiveValue" SG_ 860 VCU_VehRdySt 0;
BA_ "GenSigInvalidValue" SG_ 860 VCU_VehRdySt 0;
BA_ "GenSigSendType" SG_ 860 VCU_VehRdySt 1;
BA_ "GenSigStartValue" SG_ 860 VCU_VehRdySt 0;
BA_ "GenSigTimeoutValue" SG_ 860 VCU_VehRdySt 0;
BA_ "Remark" SG_ 860 VCU_VehRdySt "涉及ID管理表";
BA_ "EventCommandSignal" SG_ 860 VCU_PlgConnSt 0;
BA_ "GatewayedSignals" SG_ 860 VCU_PlgConnSt 0;
BA_ "GenSigInactiveValue" SG_ 860 VCU_PlgConnSt 0;
BA_ "GenSigInvalidValue" SG_ 860 VCU_PlgConnSt 0;
BA_ "GenSigSendType" SG_ 860 VCU_PlgConnSt 1;
BA_ "GenSigStartValue" SG_ 860 VCU_PlgConnSt 0;
BA_ "GenSigTimeoutValue" SG_ 860 VCU_PlgConnSt 0;
BA_ "Remark" SG_ 860 VCU_PlgConnSt "涉及ID管理表";
BA_ "EventCommandSignal" SG_ 860 VCU_GearLvlDisp 0;
BA_ "GatewayedSignals" SG_ 860 VCU_GearLvlDisp 0;
BA_ "GenSigInactiveValue" SG_ 860 VCU_GearLvlDisp 0;
BA_ "GenSigInvalidValue" SG_ 860 VCU_GearLvlDisp 0;
BA_ "GenSigSendType" SG_ 860 VCU_GearLvlDisp 1;
BA_ "GenSigStartValue" SG_ 860 VCU_GearLvlDisp 0;
BA_ "GenSigTimeoutValue" SG_ 860 VCU_GearLvlDisp 0;
BA_ "Remark" SG_ 860 VCU_GearLvlDisp "涉及ID管理表";
BA_ "EventCommandSignal" SG_ 860 VCU_SuspModeReq 0;
BA_ "GatewayedSignals" SG_ 860 VCU_SuspModeReq 0;
BA_ "GenSigInactiveValue" SG_ 860 VCU_SuspModeReq 0;
BA_ "GenSigInvalidValue" SG_ 860 VCU_SuspModeReq 0;
BA_ "GenSigSendType" SG_ 860 VCU_SuspModeReq 1;
BA_ "GenSigStartValue" SG_ 860 VCU_SuspModeReq 0;
BA_ "GenSigTimeoutValue" SG_ 860 VCU_SuspModeReq 0;
BA_ "Remark" SG_ 860 VCU_SuspModeReq "涉及ID管理表";
BA_ "EventCommandSignal" SG_ 860 VCU_SuspModeReqEnable 0;
BA_ "GatewayedSignals" SG_ 860 VCU_SuspModeReqEnable 0;
BA_ "GenSigInactiveValue" SG_ 860 VCU_SuspModeReqEnable 0;
BA_ "GenSigInvalidValue" SG_ 860 VCU_SuspModeReqEnable 0;
BA_ "GenSigSendType" SG_ 860 VCU_SuspModeReqEnable 1;
BA_ "GenSigStartValue" SG_ 860 VCU_SuspModeReqEnable 0;
BA_ "GenSigTimeoutValue" SG_ 860 VCU_SuspModeReqEnable 0;
BA_ "Remark" SG_ 860 VCU_SuspModeReqEnable "涉及ID管理表";
BA_ "EventCommandSignal" SG_ 860 VCU_GearPosition 0;
BA_ "GatewayedSignals" SG_ 860 VCU_GearPosition 0;
BA_ "GenSigInactiveValue" SG_ 860 VCU_GearPosition 0;
BA_ "GenSigInvalidValue" SG_ 860 VCU_GearPosition 0;
BA_ "GenSigSendType" SG_ 860 VCU_GearPosition 1;
BA_ "GenSigStartValue" SG_ 860 VCU_GearPosition 0;
BA_ "GenSigTimeoutValue" SG_ 860 VCU_GearPosition 0;
BA_ "Remark" SG_ 860 VCU_GearPosition "涉及ID管理表";
BA_ "EventCommandSignal" SG_ 860 VCU_EcoPlusMod 0;
BA_ "GatewayedSignals" SG_ 860 VCU_EcoPlusMod 0;
BA_ "GenSigInactiveValue" SG_ 860 VCU_EcoPlusMod 0;
BA_ "GenSigInvalidValue" SG_ 860 VCU_EcoPlusMod 0;
BA_ "GenSigSendType" SG_ 860 VCU_EcoPlusMod 1;
BA_ "GenSigStartValue" SG_ 860 VCU_EcoPlusMod 0;
BA_ "GenSigTimeoutValue" SG_ 860 VCU_EcoPlusMod 0;
BA_ "Remark" SG_ 860 VCU_EcoPlusMod "涉及ID管理表";
BA_ "EventCommandSignal" SG_ 860 ICC_RoadMod 0;
BA_ "GatewayedSignals" SG_ 860 ICC_RoadMod 0;
BA_ "GenSigInactiveValue" SG_ 860 ICC_RoadMod 0;
BA_ "GenSigInvalidValue" SG_ 860 ICC_RoadMod 0;
BA_ "GenSigSendType" SG_ 860 ICC_RoadMod 1;
BA_ "GenSigStartValue" SG_ 860 ICC_RoadMod 0;
BA_ "GenSigTimeoutValue" SG_ 860 ICC_RoadMod 0;
BA_ "Remark" SG_ 860 ICC_RoadMod "涉及ID管理表";
BA_ "EventCommandSignal" SG_ 860 VCU_TrailerModeSt 0;
BA_ "GatewayedSignals" SG_ 860 VCU_TrailerModeSt 0;
BA_ "GenSigInactiveValue" SG_ 860 VCU_TrailerModeSt 0;
BA_ "GenSigInvalidValue" SG_ 860 VCU_TrailerModeSt 0;
BA_ "GenSigSendType" SG_ 860 VCU_TrailerModeSt 1;
BA_ "GenSigStartValue" SG_ 860 VCU_TrailerModeSt 0;
BA_ "GenSigTimeoutValue" SG_ 860 VCU_TrailerModeSt 0;
BA_ "Remark" SG_ 860 VCU_TrailerModeSt "涉及ID管理表";
BA_ "EventCommandSignal" SG_ 860 VCU_BMS_BattSocDisp 0;
BA_ "GatewayedSignals" SG_ 860 VCU_BMS_BattSocDisp 0;
BA_ "GenSigInactiveValue" SG_ 860 VCU_BMS_BattSocDisp 0;
BA_ "GenSigInvalidValue" SG_ 860 VCU_BMS_BattSocDisp 16383;
BA_ "GenSigSendType" SG_ 860 VCU_BMS_BattSocDisp 1;
BA_ "GenSigStartValue" SG_ 860 VCU_BMS_BattSocDisp 16382;
BA_ "GenSigTimeoutValue" SG_ 860 VCU_BMS_BattSocDisp 16382;
BA_ "Remark" SG_ 860 VCU_BMS_BattSocDisp "涉及ID管理表";
BA_ "EventCommandSignal" SG_ 860 VCU_VehElcConspAccumAvg 0;
BA_ "GatewayedSignals" SG_ 860 VCU_VehElcConspAccumAvg 0;
BA_ "GenSigInactiveValue" SG_ 860 VCU_VehElcConspAccumAvg 0;
BA_ "GenSigInvalidValue" SG_ 860 VCU_VehElcConspAccumAvg 0;
BA_ "GenSigSendType" SG_ 860 VCU_VehElcConspAccumAvg 1;
BA_ "GenSigStartValue" SG_ 860 VCU_VehElcConspAccumAvg 1023;
BA_ "GenSigTimeoutValue" SG_ 860 VCU_VehElcConspAccumAvg 1023;
BA_ "Remark" SG_ 860 VCU_VehElcConspAccumAvg "涉及ID管理表";
BA_ "EventCommandSignal" SG_ 860 ICC_360Switch 0;
BA_ "GatewayedSignals" SG_ 860 ICC_360Switch 0;
BA_ "GenSigInactiveValue" SG_ 860 ICC_360Switch 0;
BA_ "GenSigInvalidValue" SG_ 860 ICC_360Switch 0;
BA_ "GenSigSendType" SG_ 860 ICC_360Switch 1;
BA_ "GenSigStartValue" SG_ 860 ICC_360Switch 0;
BA_ "GenSigTimeoutValue" SG_ 860 ICC_360Switch 0;
BA_ "Remark" SG_ 860 ICC_360Switch "涉及ID管理表";
VAL_ 549 ADC_APAst 0 "Off" 1 "Standby" 2 "Searching" 3 "Guidance active" 4 "Completed" 5 "Failure" 6 "Terminated" 7 "Pause"  ;
VAL_ 549 ADC_AVPst 0 "None" 1 "standby" 2 "Parked_in_slot" 3 "failure" 4 "Checking_Learning" 5 "Route_learning" 6 "Map_builded_awaiting_confirmation" 7 "Post_processing_after_map_building" 8 "Map_building_completed" 9 "Map_building_terminated" 10 "Checking_Cruising" 11 "Route_matching_successful" 12 "Cruising" 13 "Cruising_paused" 14 "Cruising_terminated" 15 "Cruising_completed"  ;
VAL_ 549 ADC_PAAFuncSt 0 "None" 1 "APA" 2 "RPA" 3 "HPA" 4 "AVP" 5 "RA" 6 "Custom Slot" 7 "PAA" 8 "DPA" 9 "summon" 10 "BSPA" 11 "Voice APA"  ;
VAL_ 549 ADC_PAAVoiceReminder 16 "The parking function is temporarily unavailable due to excessive speed" 17 "Searching for parking space, please proceed" 18 "Found parking space, please stop" 19 "Please hold the brake and click to start parking" 20 "Please release brakes and steering wheel" 21 "Parking completed" 22 "Remote parking is temporarily unavailable because no parking space is found" 23 "Remote parking is temporarily unavailable in automatic parking" 24 "Please close the door and continue" 25 "Please click to continue" 26 "Obstruction detected, please wait" 27 "Search timeout, parking exit" 28 "Please slow down" 29 "Speed is too fast, parking is about to exit" 30 "Please proceed" 31 "Please select the docking direction" 32 "Exit parking" 33 "Limited space, parking exit" 34 "System response timed out, parking exits" 35 "Throttle intervention, parking exit" 36 "Assist driving function starts and parking exits" 37 "Steering wheel interferes, parking exits" 38 "Gear intervention, parking exit" 39 "Sorry, there is a small problem with the system, parking exit" 768 "Please adjust the parking space after parking" 1024 "Reverse tracking is enabled, release brake and steering wheel" 1025 "Be aware of your surroundings and be ready to brake" 1026 "Reverse tracking completed" 1027 "Please switch to R" 1028 "Wait timeout, the function exits" 1029 "Please release the brakes before continuing" 1031 "Sorry, there is a small problem with the system, the reverse tracking is not working" 1031 "Reverse tracking has exited, please take over vehicle" 1032 "Sorry, there is a small problem with the system, reverse tracking has been quitted" 1033 "Caution when reversing" 1536 "Start Setting, please wait" 1537 "Start point set successfully!Please move to the parking space so I can learn the route" 1538 "Start point setting failed" 1539 "Route only 150 meters recorded, please park as soon as possible" 1540 "Please park in the parking space as soon as possible, otherwise this route learning will not be saved" 1541 "Excessive speed, please keep the speed less than 20 km/h" 1542 "Sorry, route learning failed" 1543 "Please click setting end" 1544 "Setting endpoint, please wait" 1545 "Finish setting is successful, click Save" 1546 "Endpoint setting failed" 1547 "Please save the route" 1548 "Saving the route" 1549 "Route saved successfully" 1550 "Sorry, route saving failed" 1551 "The route can only record 150 meters, please park as soon as possible" 1552 "Matching route" 1553 "The route is successfully matched" 1554 "Obstacle removed, parking continues" 1555 "Pay attention to pedestrians ahead" 1556 "Attention traffic ahead" 1557 "Please note the speed bump ahead" 1558 "About to turn left" 1559 "About to turn right" 1560 "Intersection ahead, please pay attention to your surroundings" 1561 "Curve ahead" 1562 "Vehicle deceleration" 1563 "rounding" 1564 "Approaching parking space" 1565 "Near the end" 2816 "Ready to go, now guide you to the designated area for valet parking" 2817 "Please keep straight" 2818 "Center lane, please" 2819 "Please keep to the left" 2820 "Please keep on the right side" 2821 "Please go straight ahead" 2822 "Turn left about 20 meters ahead" 2823 "Turn right about 20 meters ahead" 2824 "turn left" 2825 "turn right" 2826 "Off course, rerouting the course" 2827 "You are going too fast for the system to complete location" 2828 "Boot exit" 2829 "The system fails to locate and exits the boot" 2830 "Boot complete" 2831 "You have reached the valet parking activated area" 2832 "You are not within the valet parking available area" 2833 "Please select valet parking" 2834 "The pickup position has been reached"  ;
VAL_ 549 ADC_PAAVRSwitchFailSt 0 "No Fail" 1 "Fail"  ;
VAL_ 549 ADC_APKDisplayReq 0 "Not request" 1 "Request"  ;
VAL_ 549 ADC_APAActFuncInd 0 "No Active" 1 "Automatic cross park in" 2 "Automatic Parallel Park in" 3 "Automatic crossl park out" 4 "Automatic parallel park out" 5 "Remote cross Parkin" 6 "Remote parallel Parkin" 7 "Remote crossl POC" 8 "Remote parallel POC" 9 "Remote Front out" 10 "Remote Back out" 11 "Reserved" 12 "Reserved" 13 "Reserved" 14 "Reserved" 15 "Reserved"  ;
VAL_ 549 ADC_APABackParkDisplayReq 0 "None" 1 "Image parking" 2 "Space parking" 3 "Reserve"  ;
VAL_ 549 ADC_VCU_Gearshiftprompt 0 "Not request" 1 "Prohibit"  ;
VAL_ 549 ADC_PedWarnToneCtrl 0 "No Request" 1 "On" 2 "Off" 3 "reserve"  ;
VAL_ 549 ADC_PAAToNDAReq 0 "No Request" 1 "PAA to NDA" 2 "NDA to PAA" 3 "Reserved"  ;
VAL_ 549 ADC_PAARemoteParkingMode 0 "Default" 1 "Remote parking" 2 "Automatic parking" 3 "Not used"  ;
VAL_ 549 ADC_PAARemoteParkingEnable 0 "Disable" 1 "Enable"  ;
VAL_ 549 ADC_LocalToBeDRVReq 0 "No request" 1 "Request"  ;
VAL_ 549 ADC_UsageModeStAscendReq 0 "No Request" 1 "Power On Request (PTready)"  ;
VAL_ 549 ADC_UsageModeStDescendReq 0 "No request" 1 "Request"  ;
VAL_ 549 ADC_PAAIGCInhibitSt 0 "Not Inhibit" 1 "Inhibit"  ;
VAL_ 549 ADC_UsageModeStHold 0 "No request" 1 "UsageMode Hold"  ;
VAL_ 549 ADC_PAARespondMode 0 "None" 1 "RPA Parkin  遥控泊入" 2 "RPA Parkout 遥控泊出" 3 "RSPA 遥控直行"  ;
VAL_ 549 ADC_PAAEDKFunInhibitReq 0 "Not inhibit" 1 "Inhibit"  ;
VAL_ 549 ADC_UsageModeStHoldVD 0 "not valid;" 1 "valid;"  ;
VAL_ 549 ADC_RAEBEmgyBrkReq 0 "Not active" 1 "Active"  ;
VAL_ 549 ADC_PAADrvReq 0 "No_Request" 1 "Req_ClosAllDoors" 2 "Req_PowerReady" 3 "Req_StopCharging" 4 "Req_GearP" 5 "Req_DrivePathScope" 6 "Req_UpdatePath" 7 "Req_PowerOFF" 8 "Req_FasteSaftyBelt" 9 "Req_ConfirmStartButton" 10 "Req_GettingOff" 11 "Req_ConfirmNoPerson_" 12 "Req_ConfirmContinueButton" 13 "Req_DriveActiveScope" 14 "Req_ReleaseBrake" 15 "Req_SlowDwon" 16 "Req_PressBrake" 17 "Req_Stop" 18 "Req_SelectedDirection" 19 "Req_Forward" 20 "Req_EPB" 21 "Req_Close_Trunk" 22 "Req_CloseEngineDoor" 23 "Req_CloseDriverDoor" 24 "Req_ReleaseGasPedal" 25 "Req_GetInTakeOver" 26 "Req_ExpandRearviewMirror" 27 "Req_PayAttentionSurrounding" 28 "Req_SelectFunction" 29 "Req_SelectPickUpPoint" 30 "Req_SetStartPoint" 31 "Req_SetEndPoint" 32 "Req_StartAPAtoParkIntoLearningSlot" 33 "Req_DriverParkIntoLearningSlot" 34 "Req_PressBrakePedalAndContinueButton" 35 "Req_ClosePassengerDoors" 36 "Req_ProperDistance" 37 "Req_GearR" 38 "Req_ConfirmStartButtonByVoice" 39 "Req_SelectSlotByVoice" 40 "Req_ForwardToEndPoint" 41 "Req_ParkingOtherSlot" 42 "Req_ParkingInMobileSlot" 43 "Req_PayAttentionSurroundingsKeepBrakingInTime" 44 "Req_SetParkingSlot" 45 "Info_ApproachingLimitBlockAndParkingToCompleted" 46 "Req_DonotPressTheAcceleratorPedal" 47 "Req_ReleaseTheBrakeAndParkingToCompleted" 48 "Info_DrvingModeToParkingMode" 49 "Req_LeaveTheCarWithYourKeyAndBelongings" 50 "Info_LeaveCarAndClosedDoor" 51 "Req_DoubleShifterLever" 52 "Req_StopVehicleBeforParking" 55 "Req_TabSelfCheck" 56 "Req_TabParking" 57 "Info_SearchingProcess" 58 "Info_CruisingProcess" 59 "Info_PrakingProcess" 60 "Info_FuncitonSuspend" 61 "Info_FuncitonRecover" 62 "Info_FuncitonOff" 63 "Info_FuncitonComplete" 64 "Info_ConditionDetecting" 65 "Info_ConditionDetected" 66 "Info_PathMatching" 67 "Info_PathMatched" 68 "Info_ArrivedEndingPoint" 69 "Info_ArrivedStartingPoint" 70 "Info_CommunicationComplete" 71 "Info_ParkingToCruising" 72 "Info_CruisingToParking" 73 "Info_AlreadyInParkingSpace" 74 "Info_DriverSeatEmpty" 75 "Info_ParkingInFixedLot" 76 "Info_SearchingRandomLot" 77 "Info_NoParkingLot" 78 "Info_UnallowedParkingLot" 79 "Info_SteerByPeople" 80 "Info_SteerByObstacle" 81 "Info_AlreardySearchedLot" 82 "Info_DetectedObstacle" 83 "Info_DetectedPeople" 84 "Info_DetectedCrossing" 85 "Info_DetectedVehicle" 86 "Info_DetectedSpeedBumps" 87 "Info_SteerByVehicle" 88 "Info_TurnLeft" 89 "Info_TurnRight" 90 "Info_RefindParkingSpace" 91 "Info_OutOfAvailableParkingLot" 92 "Info_PathMatchingFailed" 93 "Info_ConditionDetectingFailed" 94 "Info_FoundParkingSpace" 95 "Info_InGuideRegion" 96 "Info_UnactiveRegion" 97 "Info_PowerOffFailed" 98 "Info_ParkingBrakeFailure" 99 "Info_DoorLockFailure" 100 "Info_ShutWindowFailure" 101 "Info_CloseToDestination" 102 "Info_ReachedTheEnd" 103 "Info_FunctionStart" 104 "Info_ParkingRearviewMirrorFolded" 105 "Info_ParkingSenslesEty" 106 "Info_NumberOfLineLearnlimited" 107 "Info_ExceedMaxlearningdistance" 108 "Info_OnlineMappingExceedLimit" 109 "Info_OfflineMappingExceedLimit" 110 "Info_LearningFailed" 111 "Info_SurroundingStaticObstacleTooClose" 112 "Info_SurroundingLightAbnormal" 113 "Info_Info_SurroundingSlopeAbnormal" 114 "Info_SurroundingRainy" 115 "Info_LearningFewerPointFeature" 116 "Info_CameraBlocked" 117 "Info_SurroundingSnowy" 118 "Info_LineSaveFailed" 119 "Info_SpeedExceedWarning" 120 "Info_DistanceExceedLv1Warning" 121 "Info_DistanceExceedLv2Warning" 122 "Info_ReservedDistanceExceed" 123 "Info_StartPointSuccess" 124 "Info_EndPointSuccess" 125 "Info_StartPointFail" 126 "Info_EndPointFail" 127 "Info_DetectedTurbulence" 128 "Info_DetectedSlope" 129 "Info_WaitingCarPullAway" 130 "Info_BrakeOnTime" 131 "Info_RemoteControl" 132 "Info_ArrivalDrop_offPointUseSmartKey" 133 "Info_ArrivalDrop_offPointUseAPP" 134 "Req_TryAgain_BeforeTakeKeyAway" 135 "Info_ParkingMode_CurrentlyUnavailable" 136 "Info_Move_Rotate" 137 "Info_ADASOpening" 138 "Req_Stop_Custom" 139 "Info_NarrowSlot_StopOutward" 140 "Info_Bluetooth_Detection" 141 "Info_PrkgSlotLeftOffsetNoAvailable" 142 "InfoPrkgSlotRightOffsetNoAvailable" 143 "Info_ParkingMode_CurrentlyUnavailable" 144 "ExcessiveVehicleSpeed_ReduceSpeedToInitiateParing" 145 "ReversePathAssistInProgress_PleaseMonitorTheSurroundings" 146 "Req_ConnectBluetooth" 147 "Info_BluetoothSignalWeak" 148 "Info_PrakingOutProcess" 149 "Info_PrakingInProcess" 150 "Info_TurbulencePossibility"  ;
VAL_ 549 ADC_PAAQuitInd 0 "No_Request" 1 "Quit_SysFailure" 2 "Quit_SpeedHigh" 3 "Quit_TimingOverflow" 4 "Quit_ParkingTimingOverflow" 5 "Quit_MoveTimesOverflow" 6 "Quit_WaitTimingOverflow" 7 "Quit_RecoverInterruptTimesOverflow" 8 "Quit_GasPedalIntervention" 9 "Quit_BrakePedalIntervention" 10 "Quit_GearIntervention" 11 "Quit_ExternalECUActive" 12 "Quit_TrajectoryLimit" 13 "Quit_SpaceLimit" 14 "Quit_PhoneDisconnected" 15 "Quit_SeatBeltUnbuckle" 16 "Quit_DoorOpen" 17 "Quit_EPBApply" 18 "Quit_VehicleBlock" 19 "Quit_GearResponseTimeOut" 20 "Quit_LuggageDoorOpen" 21 "Quit_SteeringWheelHandsOn" 22 "Quit_CancelButtonPressed" 23 "Quit_DoorLock" 24 "Quit_SBMFailureReason" 25 "Quit_RemoteDeviceFairlureReason" 26 "Quilt_UnsafeBehavior" 27 "Quit_PhoneLowBattey" 28 "Quit_VCUFailureReason" 29 "Quit_ESPFailureReason" 30 "Quit_EPSFailureReason" 31 "Quit_TBOXFailureReason" 32 "Quit_ExternalECUFailure" 33 "Quit_NoParkingLot" 34 "Quit_UnallowedParkingLot" 35 "Quit_PTReadyFailure" 36 "Quit_AlreadyInParkingSpace" 37 "Quit_PathEndingArrived" 38 "Quit_TaskFailed" 39 "Quit_PathMatchFailed" 40 "Quit_RearviewMirrorFolded" 41 "Quit_PowerOffFailed" 42 "Quit_FuncitonOff" 43 "Quit_EPSHandshakingFailed" 44 "Quit_ESPHandshakingFailed" 45 "Quit_PathMatchingFailed" 46 "Quit_ConditionDetectingFailed" 47 "Quit_PositionUnaviable" 48 "Quit_ObtainPathFailed" 49 "Quit_NoParkingLot2" 50 "Quit_UnallowedParkingLot2" 51 "Quit_OutOfAvailableParkingLot" 52 "Quit_UnactiveRegion" 53 "Quit_DoorLockFailure" 54 "Quit_AbnormalTirePressure" 55 "Quit_GearInterrupt" 56 "Quit_UserCancel" 57 "Quit_DriverDoorOpened" 58 "Quit_HoodOpened" 59 "Quit_CrashedDetected" 60 "Quit_LightAbnormal" 61 "Quit_RainyDay" 62 "Quit_SlopeAbnormal" 63 "Quit_FewPointFeature" 64 "Quit_FrontCameraDirty" 65 "Quit_SurroundCameraDirty" 66 "Quit_No_Valid_Path" 67 "Quit_Charger_connected" 68 "Quit_FunctionButtonPressed" 69 "Quit_OffTrack" 70 "Quit_SystemFailureFunctionUnusable" 71 "Quit_SpeedTooHighPleaseReduce" 72 "Quit_RouteTooShort" 73 "Quit_PleaseCloseADASFuncionAndOpenRA" 74 "Quit_ReachFinishLinePleaseTakeOverTheVehicle" 75 "Quit_FuntionQuitPleaseTakeOverTheVehicle" 76 "Quit_SytemTimeOutFuntionQuit" 77 "Quit_AbnormalGearPositionFuntionQuit" 78 "Quit_ConditionNotMetFuntionQuit" 79 "Quit_DrivingFunctionActive" 80 "Quit_LearnningLineDistanceLimit" 81 "Quit_ObstacleTooClose" 82 "Quit_BackDistanceTooLong" 83 "Quit_VehModeUnavailable" 84 "Quit_MatchTimeout" 85 "Quit_RemoteControlFail" 86 "Quit_LeraningConditionFail" 87 "Quit_NoDriver" 88 "Quit_Re_EnterParking" 89 "Quit_LearnningMapFail"  ;
VAL_ 549 ADC_PAARecInd 0 "No_Request" 1 "Recover_PressInterruptSwitch" 2 "Recover_MobileOutRange" 3 "Recover_DoorOpened" 4 "Recover_FoundObstacleTrajectory" 5 "Recover_MobileCommunicationWeak" 6 "Recover_SeatBeltUnbuckle" 7 "Recover_ParkingTimingOverflow" 8 "Recover_MoveTimesOverflow" 9 "Recover_GasPedalIntervention" 10 "Recover_BrakePedalIntervention" 11 "Recover_SpaceLimit" 12 "Recover_PhoneDisconnected" 13 "Recover_EPBApply" 14 "Recover_VehicleBlock" 15 "Recover_LuggageDoorOpen" 16 "Recover_PhoneLowBattey" 17 "Recover_NoParkingLot" 18 "Recover_UnallowedParkingLot" 19 "Recover_RearviewMirrorFolded" 20 "Recover_SteeringWheelHandsOn" 21 "Recover_GearIntervention" 22 "Recover_FrontCameraDirty" 23 "Recover_SurroundCameraDirty" 24 "Recover_PressContinueSwitch" 25 "Recover_VehicleCrossing" 26 "Recover_PressContinueSwitchBrakePedal" 27 "Recover_ObstacleAvoidancePleaseWait" 28 "Recover_HoodOpen" 29 "Info_DetectedSideObstacle"  ;
VAL_ 549 ADC_RAButtonPress 0 "Not Press" 1 "Press"  ;
VAL_ 549 ADC_Rast 0 "Off" 1 "Standby" 2 "Confirm" 3 "Active" 4 "Completed" 5 "Failure" 6 "Terminated" 7 "Reserved"  ;
VAL_ 549 ADC_SBMAuthst 0 "Default" 1 "Fail" 2 "Pass" 3 "Not used"  ;
VAL_ 549 ADC_AuthPassSt 0 "Default" 1 "Fail" 2 "Pass" 3 "Not used"  ;
VAL_ 549 ADC_VehPoscoord 0 "Veh Coordinate" 1 "Slot Coordinate"  ;
VAL_ 549 ADC_HPAst 0 "Standby" 1 "Parking" 2 "HPA Completed" 3 "HPA Interrupt" 4 "HPA Terminated" 5 "HPA Resume" 6 "HPA Failure" 7 "HPA backend mapping" 8 "HPA parking into slot" 9 "HPA Checking" 10 "HPA Learning"  ;
VAL_ 549 ADC_parkInOutDirection 0 "None" 1 "Right cross or Diagonal rear-end park in右垂直/斜列车尾泊入" 2 "Left cross or Diagonal rear-end park in左垂直/斜列车尾泊入" 3 "Right Parallel  rear-end park in右水平车尾泊入" 4 "Left Parallel  rear-end park in左水平车尾泊入" 5 "Right Diagonal park in右斜列泊入（兼容旧ADC）" 6 "Left Diagonal park in左斜列泊入（兼容旧ADC）" 7 "Right cross or Diagonal front-end park in右垂直/斜列车头泊入" 8 "Left cross or  Diagonal front-end park in左垂直/斜列车头泊入" 9 "Right cross or Diagonal front-end park out右垂直/斜列车头泊出" 10 "Left cross or Diagonal front-end park out左垂直/斜列车头泊出" 11 "Right Parallel front-end park out右水平车头泊出" 12 "Left Parallel front-end park out左水平车头泊出" 13 "Right cross or Diagonal rear-end park out右垂直/斜列车尾泊出" 14 "Left cross or Diagonal rear-end park out左垂直/斜列车尾泊出"  ;
VAL_ 549 ADC_RPAStMessagePush 0 "Not Request" 1 "RPA standby" 2 "LRPA start" 3 "LRPA complete" 4 "LRPA teminal"  ;
VAL_ 549 ADC_RPAtype 0 "invalid" 1 "RPAWithoutConfirmation" 2 "RPAByConfirmationSelected"  ;
VAL_ 549 ADC_DskScreenOperationReq 0 "No request" 1 "Request"  ;
VAL_ 549 ADC_SenslesEtyParkingSt 0 "Off" 1 "On"  ;
VAL_ 549 ADC_PAALimitToast 0 "No Request;" 1 "APA OverSpeed;" 2 "Failure Limit;" 3 "Vehicle Mode Limit;" 4 "ADAS Limit;" 5 "Not Ready Limit;" 6 "AVM OverSpeed;" 7 "Not ParkSlot;"  ;
VAL_ 549 ADC_PAALimitReminder 0 "No Request;" 1 "APA OverSpeed;" 2 "Failure Limit;" 3 "Vehicle Mode Limit;" 4 "ADAS Limit;" 5 "Not Ready Limit;" 6 "AVM OverSpeed;" 7 "reserved"  ;
VAL_ 549 ADC_ParkOutMode 0 "None" 1 "Cross or Diagonal   front-end  park out垂直/斜列车头泊出" 2 "Cross or Diagonal  rear-end  park out垂直/斜列车尾泊出" 3 "Parallel front-end park out水平车头泊出" 4 "Reserve" 5 "Reserve" 6 "Reserve" 7 "Reserve"  ;
VAL_ 549 ADAS_ParkStats 0 "OFF" 1 "VPD parkin active" 2 "VPD parkin abort" 3 "VPD parkin finish" 4 "VPD parkout active" 5 "VPD parkout abort" 6 "VPD parkout finish" 7 "EPA active" 8 "EPA abort" 9 "EPA finish" 10 "RPA parkin active" 11 "RPA parkin abort" 12 "RPA parkin finish" 13 "RPA parkout active" 14 "RPA parkout abort" 15 "RPA parkout finish" 16 "RDA forward active" 17 "RDA forward abort" 18 "RDA forward finish" 19 "RDA back active" 20 "RDA back abort" 21 "RDA back finish" 22 "APA parkin active" 23 "APA parkin abort" 24 "APA parkin finish" 25 "APA parkout active" 26 "APA parkout abort" 27 "APA parkout finish"  ;
VAL_ 549 ADC_ParkinDir 0 "None" 1 "Left Parkin" 2 "Right Parkin" 3 "Reserve"  ;
VAL_ 549 ADC_FrontEndParkInRes 0 "None" 1 "Rear-End" 2 "Front-End" 3 "Reserve"  ;
VAL_ 549 ADC_ParkSlotType 0 "None" 1 "Normal slot正常车位" 2 "Narrow slot窄车位" 3 "Mechanical slot机械车位"  ;
VAL_ 549 ADC_BleRPAPageSt 0 "none" 1 "RPA standby" 2 "readyforstart" 3 "parking（泊车中）" 4 "pause" 5 "ReadyForRecover" 6 "complete" 7 "selftestNG" 8 "Aborted"  ;
VAL_ 549 ADC_RPAPreferRes 0 "None" 1 "left prefer偏左泊入" 2 "mid prefer居中泊入" 3 "right prefer偏右治入"  ;
VAL_ 549 ADC_RPAPrkSlotoffset 0 "None无选择" 1 "left prefer偏左泊入" 2 "mid prefer居中泊入" 3 "right refer偏右泊入"  ;
VAL_ 549 ADC_RPAPreferavl 0 "None不显示" 1 "mid&left&right支持居中+偏左+偏右" 2 "mid&left支持居中+偏左" 3 "mid&right支持居中+偏右" 4 "mid仅支持居中"  ;
VAL_ 549 ADC_RPABlechnReq 0 "Close" 1 "Open"  ;
VAL_ 549 ADC_RPABlePushSt 0 "No Request" 1 "RPAin ready" 2 "RPAout ready（预留）" 3 "RSPA ready（预留）" 4 "LRPAin ready  离车泊入"  ;
VAL_ 1359 CCU_NMCBV 0 "Node has not woken up the    network(passive wakeup);" 1 "Node has woken up the network(active wakeup)" 0 "NM PDU contains no Partial Network request information" 1 "NM PDU contains Partial Network request information"  ;
VAL_ 1359 CCU_NMWakeupOrigin 0 "Reserved" 1 "CAN channel 0" 2 "CAN channel 1" 3 "CAN channel 2" 4 "CAN channel 3" 5 "CAN channel 4" 6 "CAN channel 5" 7 "CAN channel 6" 8 "CAN channel 7" 9 "CAN channel 8" 10 "CAN channel 9" 11 "CAN channel 10" 12 "CAN channel 11" 13 "CAN channel 12" 14 "CAN channel 13" 15 "CAN channel 14" 16 "CAN channel 15" 17 "Reserved" 18 "Reserved" 19 "Reserved" 20 "AcoreRequest" 21 "Reserved" 22 "Reserved" 23 "Reserved" 24 "Reserved" 25 "Reserved" 26 "Reserved" 27 "Reserved" 28 "Reserved" 29 "Reserved" 30 "Reserved" 31 "Reserved" 32 "Reserved" 33 "Reserved" 34 "Reserved" 35 "Reserved" 36 "Reserved" 37 "Reserved" 38 "Reserved" 39 "Reserved" 40 "Reserved" 41 "Reserved" 42 "Reserved" 43 "Reserved" 44 "Reserved" 45 "Reserved" 46 "Reserved" 47 "Reserved" 48 "Reserved" 49 "Reserved" 50 "UsageModeSt" 51 "NMiDPSNMKeepAwakeFlag" 52 "NMEEMKeepAwakeFlag" 53 "NMEEMKeepAwakeFlag_Aux" 54 "NMVCUGlobalKeepAwakeFlag" 55 "NMVCUChargingKeepAwakeFlag（新能源，VCU_hcu）" 56 "DoIPActiveLineStatus" 57 "NMBMSGlobalKeepAwakeFlag" 58 "NMBMSChargingKeepAwakeFlag" 59 "NMBMSThermalRunawayKeepAwakeFlag（新能源，BMS）" 60 "Reserved" 61 "NMBMSThermalRunawayKeepAwakeFlag （动力，VCU_slccu）" 62 "NMVCUChargingKeepAwakeFlag（动力，VCU_slccu）" 63 "NMVCU2GlobalKeepAwakeFlag" 64 "NMVHMKeepAwakeFlag" 65 "Reserved" 66 "CSM_RC_KeepAwake" 67 "NMHVACKeepAwakeFlag（新能源，TMS）" 68 "Reserved" 69 "Reserved" 70 "BDC_NMBDCKeepAwakeFlag" 71 "NMTMSChargingKeepAwakeFlag" 72 "NMTMSGlobalKeepAwakeFlag" 73 "Reserved" 74 "Reserved" 75 "Reserved" 76 "Reserved" 77 "Reserved" 78 "Reserved" 79 "Reserved" 80 "Reserved" 81 "Reserved" 82 "Reserved" 83 "Reserved" 84 "Reserved" 85 "Reserved" 86 "Reserved" 87 "Reserved" 88 "Reserved" 89 "NMWCCDownloadRequest_RT1" 90 "CAN7_DiagMSG_ID ！" 91 "CAN7_DiagMSG_ID" 92 "Reserved" 93 "Reserved" 94 "Reserved" 95 "Reserved" 96 "Reserved" 97 "Reserved" 98 "Reserved" 99 "Reserved" 100 "NMATWSKeepAwakeFlag" 101 "NMExteriorLightKeepAwakeFlag" 102 "NMLockingKeepAwakeFlag" 103 "NMPWLKeepAwakeFlag" 104 "NMSunRoofKeepAwakeFlag" 105 "NMPLGKeepAwakeFlag" 106 "NMPowerOperatedDoorKeepAwakeFlag" 107 "MR_NMMirrorKeepAwakeFlag" 108 "NMSeatControlKeepAwakeFlag" 109 "NMHVACKeepAwakeFlag" 110 "NMHVACRLSLinAwakeFlag" 111 "NMAQCKeepAwakeFlag" 112 "NMTPMSKeepAwakeFlag" 113 "ILC_NMKeepAwakeFlag" 114 "NMESMKeepAwakeFlag" 115 "NMKAEKeepAwakeFlag" 116 "NMVRMPNCCharingKeepAwakeFlag" 140 "NMWCCDownloadReques_RT2"  ;
VAL_ 1359 CCU_PNCInformation0 0 "No request" 1 "Request" 0 "No request" 1 "Request" 0 "No request" 1 "Request" 0 "No request" 1 "Request" 1 "Request" 0 "No request" 1 "Request" 0 "No request" 1 "Request"  ;
VAL_ 1359 CCU_PNCInformation1 0 "No request" 1 "Request" 0 "No request" 1 "Request"  ;
VAL_ 905 ICM_SetIACCSt 0 "Not active" 1 "Active"  ;
VAL_ 516 VCU_MaxDriveTorqVD 0 "Not valid" 1 "Valid"  ;
VAL_ 516 VCU_RecpTorqVD 0 "Invalid;" 1 "Valid;"  ;
VAL_ 516 VCU_MaxRecpTorqVD 0 "Invalid" 1 "Valid"  ;
VAL_ 516 VCU_CrntGearLvl 0 "Invalid" 1 "'D' Drive gear" 2 "'N' Neutral gear" 3 "'R' Reverse gear" 4 "'P' Park gear" 5 "Not used" 6 "Not used" 7 "Not used"  ;
VAL_ 516 VCU_CrntGearLvlVD 1 "Valid;" 0 "Not valid.;"  ;
VAL_ 516 VCU_BrkPedPstVD 0 "Not valid" 1 "Valid"  ;
VAL_ 516 VCU_GearIntervern 0 "with not intervention" 1 "with intervention"  ;
VAL_ 516 VCU_AccPedalVirtPstVD 0 "Not valid" 1 "Valid"  ;
VAL_ 516 VCU_AccPedalVirtPst 511 "error;" 510 "Init;"  ;
VAL_ 516 VCU_BrkPedalSt 0 "Not pressed                                                                     1"  ;
VAL_ 516 VCU_BrkPedalStVD 0 "Not Valid                                                                           1"  ;
VAL_ 516 VCU_ACCLimitOperatingSt 0 "Not active" 1 "active"  ;
VAL_ 516 VCU_AccButtInfo 0 "not press" 1 "press" 0 "not press" 1 "press" 0 "not press" 1 "press" 0 "not press" 1 "press" 0 "not press" 1 "press" 0 "Normal" 1 "Abnormal"  ;
VAL_ 516 VCU_ACCmaxSpdLimit 0 "No Limit" 1 "10 Km/h" 2 "20 Km/h" 3 "30 Km/h" 4 "40 Km/h" 5 "50 Km/h" 6 "60 Km/h" 7 "70 Km/h" 8 "80 Km/h" 9 "90 Km/h" 10 "100 Km/h" 11 "110 Km/h" 12 "120 Km/h" 13 "130 Km/h" 14 "140 Km/h" 15 "Reserved"  ;
VAL_ 516 VCU_RecpTorqFAVD 1 "Valid;" 0 "Invalid;"  ;
VAL_ 516 VCU_RecpTorqRAVD 1 "Valid;" 0 "Invalid;"  ;
VAL_ 516 VCU_MaxRecpTorqFAVD 1 "Valid;" 0 "Not valid;"  ;
VAL_ 516 VCU_MaxRecpTorqRAVD 1 "Valid;" 0 "Not valid;"  ;
VAL_ 516 VCU_BcsDecelEnable 0 "Not active" 1 "Active"  ;
VAL_ 516 VCU_CrntGearNoTrans 4 "'P' Park gear;" 3 "'R' Reverse gear;" 2 "'N' Neutral gear;" 1 "'D' Drive gear;" 0 "Invalid;"  ;
VAL_ 516 VCU_EzTSt 0 "Invalid" 1 "Off" 2 "Standby" 3 "Active"  ;
VAL_ 516 VCU_ITASSt 0 "invalid" 1 "Off" 2 "Standby" 3 "Active" 4 "Rampoff Request" 5 "Rampoff2" 6 "Reserved" 7 "Reserved"  ;
VAL_ 909 LCK_HoodAjarSt 0 "Closed" 1 "Opened"  ;
VAL_ 909 LCK_FrontLeftDoorAjarSt 0 "Closed" 1 "Opened"  ;
VAL_ 909 LCK_FrontRightDoorAjarSt 0 "Closed" 1 "Opened"  ;
VAL_ 909 LCK_RearLeftDoorAjarSt 0 "Closed" 1 "Opened"  ;
VAL_ 909 LCK_RearRightDoorAjarSt 0 "Closed" 1 "Opened"  ;
VAL_ 909 LCK_TrunkAjarSt 0 "Closed" 1 "Opened"  ;
VAL_ 909 LCK_FrontLeftDoorLockSt 0 "Locked" 1 "Unlocked"  ;
VAL_ 909 LCK_FrontRightDoorLockSt 0 "Locked" 1 "Unlocked"  ;
VAL_ 909 LCK_RearLeftDoorLockSt 0 "Locked" 1 "Unlocked"  ;
VAL_ 909 LCK_RearRightDoorLockSt 0 "Locked" 1 "Unlocked"  ;
VAL_ 909 LCK_RearLeftChildSaftyLockSt 0 "Locked" 1 "Unlocked"  ;
VAL_ 909 LCK_RearRightChildSaftyLockSt 0 "Locked" 1 "Unlocked"  ;
VAL_ 909 EMS_EngStForPHEV 0 "Standby" 1 "Ready" 2 "Cranking" 3 "Running" 4 "Stopping" 5 "Stopped" 6 "Aotostopping"  ;
VAL_ 909 WCM_Reminder 0 "No_warning" 1 "Phone_left_in_car"  ;
VAL_ 909 WCM_ChargingSt 0 "Standby" 1 "Charging" 2 "Charging completed (available when Rx support)" 3 "Not standby"  ;
VAL_ 909 LCK_FrontLeftDoorHandlePosition 0 "FullyClosed" 100 "FullyOpened" 254 "Uninitialized" 255 "Unknown"  ;
VAL_ 909 LCK_FrontRightDoorHandlePosition 0 "FullyClosed" 100 "FullyOpened" 254 "Uninitialized" 255 "Unknown"  ;
VAL_ 909 LCK_RearLeftDoorHandlePosition 0 "FullyClosed" 100 "FullyOpened" 254 "Uninitialized" 255 "Unknown"  ;
VAL_ 909 LCK_RearRightDoorHandlePosition 0 "FullyClosed" 100 "FullyOpened" 254 "Uninitialized" 255 "Unknown"  ;
VAL_ 909 WW_RWPMotorSt 0 "Off" 1 "Reserve" 2 "Stall protection" 3 "Failure" 4 "Low speed" 5 "High speed" 6 "Hard stopped" 7 "Interval delaying"  ;
VAL_ 909 LCK_FillerCapASt 0 "Closed" 1 "Opened"  ;
VAL_ 909 LCK_FillerCapBSt 0 "Closed" 1 "Opened"  ;
VAL_ 909 MR_LeftMirrorFoldUnfoldSt 0 "Unknown" 1 "Mirror fold" 2 "Mirror unfold" 3 "Reserved"  ;
VAL_ 909 SBM_SwapHvBattModeSt 0 "default" 1 "Station open the door for veichle go in" 2 "Station find Vehicle stop OK" 3 "Station prepare to swap" 4 "Station begin to swap" 5 "Station finish assembling" 6 "Station complete to swap" 7 "Station pause swapping" 8 "Station open the door for veichle go out"  ;
VAL_ 909 SBM_SwapStaDiagCode 0 "Normal" 1 "Fault,BT cominication error" 2 "Fault,SWAP station error" 3 "Fault,vehile error"  ;
VAL_ 909 SBM_SwapHvBattModeFaultSt 0 "default" 1 "Normal" 2 "Error,can recovery" 3 "Error,can not recover"  ;
VAL_ 909 IPDS_HDMapPowerSt 0 "Not Active" 1 "Active"  ;
VAL_ 909 IPDS_KL15L1PowerSt 0 "Not Active" 1 "Active"  ;
VAL_ 909 IPDS_SRSECUPowerSt 0 "Not Active" 1 "Active"  ;
VAL_ 909 IPDS_HODPowerSt 0 "Not Active" 1 "Active"  ;
VAL_ 909 KAE_BLEOption 0 "Not active" 1 "Active"  ;
VAL_ 909 KAE_UWBOption 0 "Not active" 1 "Active"  ;
VAL_ 909 PWL_WinCurrentPos_FLWinPst 255 "Undefined window position"  ;
VAL_ 909 UINM_FrontLeftPowerReleaseReq 0 "NoReq" 1 "Release"  ;
VAL_ 909 UINM_FrontLeftPowerReleaseFaultSt 0 "noraml" 1 "fault"  ;
VAL_ 909 UINM_FrontRightPowerReleaseReq 0 "NoReq" 1 "Release"  ;
VAL_ 909 UINM_FrontRightPowerReleaseFaultSt 0 "noraml" 1 "fault"  ;
VAL_ 909 UINM_RearLeftPowerReleaseFaultSt 0 "noraml" 1 "fault"  ;
VAL_ 909 UINM_RearLeftPowerReleaseReq 0 "NoReq" 1 "Release"  ;
VAL_ 909 UINM_RearRightPowerReleaseFaultSt 0 "noraml" 1 "fault"  ;
VAL_ 909 UINM_RearRightPowerReleaseReq 0 "NoReq" 1 "Release"  ;
VAL_ 909 PWL_WinCurrentPos_RRWinPst 255 "Undefined window position"  ;
VAL_ 909 PWL_WinCurrentPos_RLWinPst 255 "Undefined window position"  ;
VAL_ 909 ACEleclocksSt 0 "init" 1 "Uncloked" 2 "Locked" 3 "Error,bosh open" 4 "Error,bosh close"  ;
VAL_ 909 DSASBM_MotResp 0 "No Action" 1 "Executing Retraction Assistance" 2 "Executing Clearance Removal 1" 3 "Executing Clearance Removal 2" 4 "Executing Dynamic Support 1" 5 "Executing Dynamic Support 2" 6 "Executing Pre-crash Protection" 7 "Executing Vibration Warning 1" 8 "Executing Vibration Warning 2" 9 "Reserved" 10 "Retraction Assistance Completed" 11 "Clearance Removal Completed" 12 "Executing Dynamic Support 3" 13 "Executing Dynamic Support 4" 14 "Executing Vibration Notification" 15 "Reserved"  ;
VAL_ 792 UMM_SecondRHSeatSt 0 "Undefined" 1 "Off" 2 "On" 3 "Failure"  ;
VAL_ 792 UMM_SecondLHSeatSt 0 "Undefined" 1 "Off" 2 "On" 3 "Failure"  ;
VAL_ 792 LCK_PowerFillerCapAngle 0 "FullyClosed" 255 "Unknown"  ;
VAL_ 792 EL_ReverseLightSt 0 "OFF" 1 "ON"  ;
VAL_ 792 EL_ReverseLightFaultSt 0 "Not fault" 1 "Fault"  ;
VAL_ 792 EL_RLPositionLightSt 0 "OFF" 1 "ON"  ;
VAL_ 792 EL_RLPositionLightFaultSt 0 "Not fault" 1 "Fault"  ;
VAL_ 792 EL_RRPositionLightSt 0 "OFF" 1 "ON"  ;
VAL_ 792 EL_RRPositionLightFaultSt 0 "Not fault" 1 "Fault"  ;
VAL_ 792 EL_RearFogLightSt 0 "OFF" 1 "ON"  ;
VAL_ 792 EL_RearFogLightFaultSt 0 "Not fault" 1 "Fault"  ;
VAL_ 860 VCU_RoadMod 0 "Invalid" 1 "Mud Mode" 2 "Snow Mode" 3 "Sand Mode" 4 "Offroad Mode" 5 "Slippery Mode" 7 "Off"  ;
VAL_ 860 VCU_GearLvl 0 "Invalid" 1 "'D' Drive gear" 2 "'N' Neutral gear" 3 "'R' Reverse gear" 4 "'P' Park gear" 5 "Not used" 6 "Not used" 7 "Not used" 8 "Not used" 9 "Not used" 10 "Not used" 11 "Not used" 12 "Not used" 13 "Not used" 14 "Not used" 15 "Not used"  ;
VAL_ 860 VCU_VehDrvMod 7 "Individual；" 6 "reserved；" 5 "SPORT Mode;" 4 "Driving Mode;超跑模式" 3 "Comfort Mode;" 2 "ECO Mode;" 1 "reserved；" 0 "Invalid;"  ;
VAL_ 860 VCU_VehRdySt 0 "Not ready" 1 "Ready"  ;
VAL_ 860 VCU_PlgConnSt 0 "Not connected" 1 "Plug connector connected"  ;
VAL_ 860 VCU_GearLvlDisp 0 "Invalid" 1 "'D' Drive gear" 2 "'N' Neutral gear" 3 "'R' Reverse gear" 4 "'P' Park gear" 5 "Reserved" 6 "Reserved" 7 "Reserved" 8 "Reserved" 9 "Reserved" 10 "Reserved" 11 "Reserved" 12 "Reserved" 13 "Reserved" 14 "Reserved" 15 "Reserved"  ;
VAL_ 860 VCU_SuspModeReq 0 "not request" 1 "comfort mode" 2 "normal mode(reserved)" 3 "sport mode"  ;
VAL_ 860 VCU_SuspModeReqEnable 0 "disable" 1 "enable"  ;
VAL_ 860 VCU_GearPosition 7 "Request to remove anti-theft" 6 "EPB Locking failure, return 'N' gear;" 5 "'D' Drive gear;" 4 "'R' Reverse gear;" 3 "'N' Neutral gear;" 2 "'P' Park gear;" 1 "P_Pending;" 0 "Undefined;"  ;
VAL_ 860 VCU_EcoPlusMod 0 "No command" 1 "ON" 2 "OFF" 3 "reserved"  ;
VAL_ 860 ICC_RoadMod 0 "Invalid" 1 "Highway" 2 "Auto Mode" 3 "Snow Mode" 4 "Mud Mode" 5 "Sand Mode" 6 "Ruggged Mode" 7 "Wade Mode" 8 "Expert Mode"  ;
VAL_ 860 VCU_TrailerModeSt 0 "No command" 1 "Trailer Mode is close and TRM is nunconnected" 2 "Trailer Mode is open but TRM is nunconnected" 3 "Trailer Mode is open and TRM is connected" 4 "Trailer Mode is close but TRM is connected" 5 "Trailer Mode is open but TRM connection is status unkown" 6 "Trailer Mode is close but TRM connection is status unkown" 7 "Trailer Mode is Not available"  ;
VAL_ 860 VCU_BMS_BattSocDisp 16382 "Init;" 16383 "error"  ;
VAL_ 860 ICC_360Switch 0 "No Request" 1 "ON" 2 "OFF" 3 "Reserved"  ;
